VERSION ""

NS_ :

BS_:

BU_: ACS CC TCO SSC RD REX VGW TPMS TECU IC EMS EBS

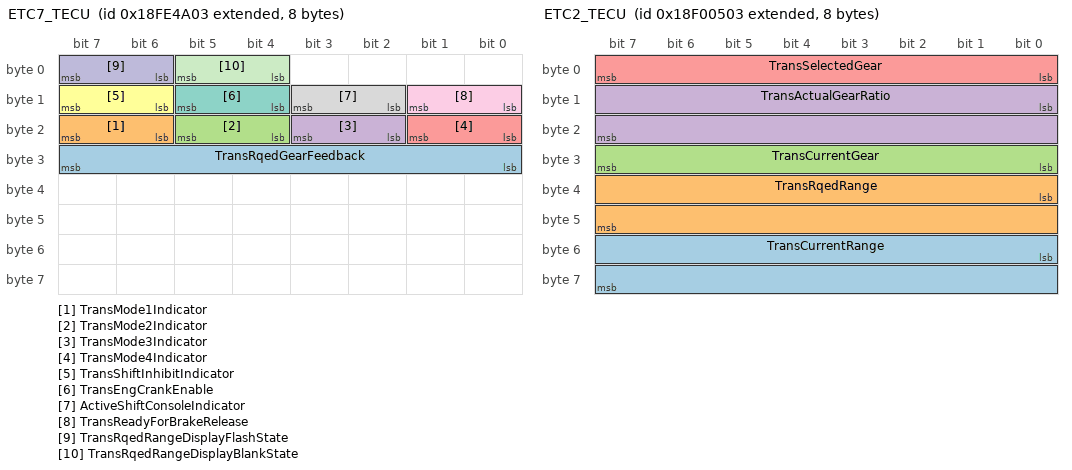
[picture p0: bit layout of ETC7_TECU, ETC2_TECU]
BO_ 2566801923 ETC7_TECU: 8 TECU
 SG_ TransRqedGearFeedback : 24|8@1+ (1,-125) [-125|125] "" Vector__XXX
 SG_ TransMode1Indicator : 22|2@1+ (1,0) [0|3] "" Vector__XXX
 SG_ TransMode2Indicator : 20|2@1+ (1,0) [0|3] "" Vector__XXX
 SG_ TransMode3Indicator : 18|2@1+ (1,0) [0|3] "" Vector__XXX
 SG_ TransMode4Indicator : 16|2@1+ (1,0) [0|3] "" Vector__XXX
 SG_ TransShiftInhibitIndicator : 14|2@1+ (1,0) [0|3] "" Vector__XXX
 SG_ TransEngCrankEnable : 12|2@1+ (1,0) [0|3] ""  EMS
 SG_ ActiveShiftConsoleIndicator : 10|2@1+ (1,0) [0|3] "" Vector__XXX
 SG_ TransReadyForBrakeRelease : 8|2@1+ (1,0) [0|3] "" Vector__XXX
 SG_ TransRqedRangeDisplayFlashState : 6|2@1+ (1,0) [0|3] "" Vector__XXX
 SG_ TransRqedRangeDisplayBlankState : 4|2@1+ (1,0) [0|3] "" Vector__XXX

BO_ 2565866755 ETC2_TECU: 8 TECU
 SG_ TransCurrentRange : 48|16@1+ (1,0) [0|255] "" Vector__XXX
 SG_ TransRqedRange : 32|16@1+ (1,0) [0|255] "" Vector__XXX
 SG_ TransCurrentGear : 24|8@1+ (1,-125) [-125|125] ""  IC,EBS
 SG_ TransActualGearRatio : 8|16@1+ (0.001,0) [0|64.255] "" Vector__XXX
 SG_ TransSelectedGear : 0|8@1+ (1,-125) [-125|125] ""  EMS,IC

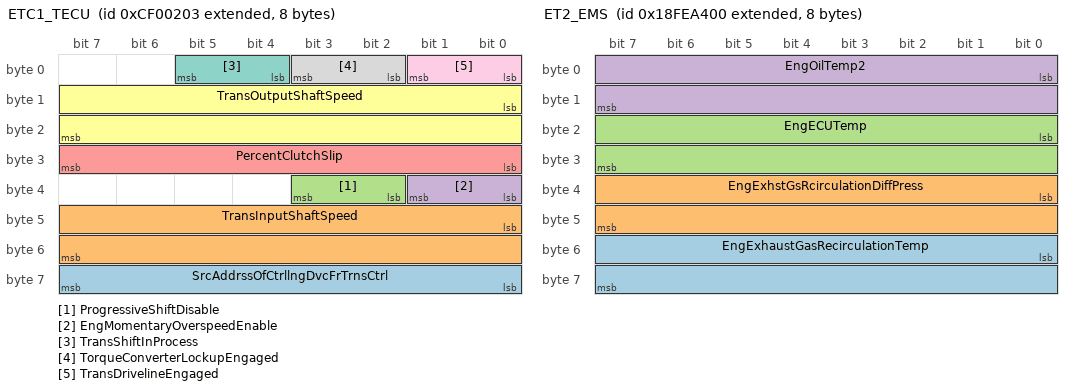
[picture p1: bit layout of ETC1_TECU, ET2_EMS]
BO_ 2364539395 ETC1_TECU: 8 TECU
 SG_ SrcAddrssOfCtrllngDvcFrTrnsCtrl : 56|8@1+ (1,0) [0|255] "" Vector__XXX
 SG_ TransInputShaftSpeed : 40|16@1+ (0.125,0) [0|8031.875] "rpm"  EMS,EBS
 SG_ ProgressiveShiftDisable : 34|2@1+ (1,0) [0|3] "" Vector__XXX
 SG_ EngMomentaryOverspeedEnable : 32|2@1+ (1,0) [0|3] "" Vector__XXX
 SG_ PercentClutchSlip : 24|8@1+ (0.4,0) [0|100] "%" Vector__XXX
 SG_ TransOutputShaftSpeed : 8|16@1+ (0.125,0) [0|8031.875] "rpm" Vector__XXX
 SG_ TransShiftInProcess : 4|2@1+ (1,0) [0|3] ""  EBS
 SG_ TorqueConverterLockupEngaged : 2|2@1+ (1,0) [0|3] ""  EBS
 SG_ TransDrivelineEngaged : 0|2@1+ (1,0) [0|3] ""  EBS

BO_ 2566824960 ET2_EMS: 8 EMS
 SG_ EngExhaustGasRecirculationTemp : 48|16@1+ (0.03125,-273) [-273|1735] "deg" Vector__XXX
 SG_ EngExhstGsRcirculationDiffPress : 32|16@1+ (0.0078125,-250) [-250|251.99] "kPa" Vector__XXX
 SG_ EngECUTemp : 16|16@1+ (0.03125,-273) [-273|1735] "deg" Vector__XXX
 SG_ EngOilTemp2 : 0|16@1+ (0.03125,-273) [-273|1735] "deg" Vector__XXX

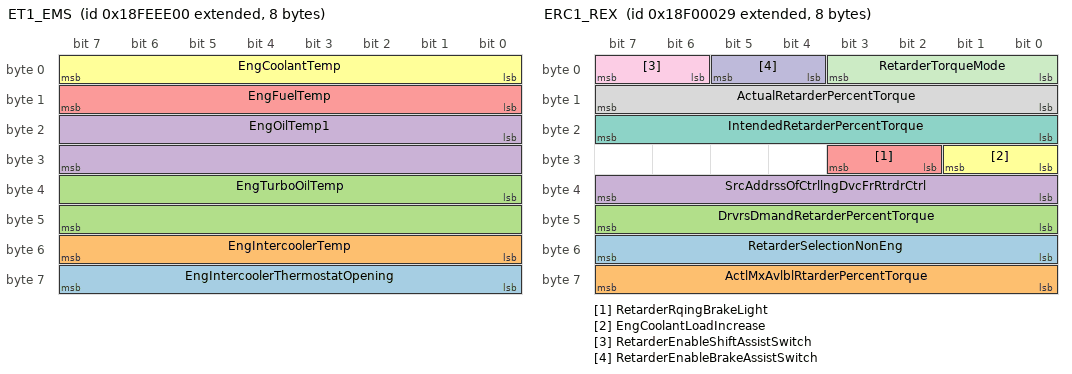
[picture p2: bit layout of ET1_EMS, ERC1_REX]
BO_ 2566843904 ET1_EMS: 8 EMS
 SG_ EngIntercoolerThermostatOpening : 56|8@1+ (0.4,0) [0|100] "%" Vector__XXX
 SG_ EngIntercoolerTemp : 48|8@1+ (1,-40) [-40|210] "deg" Vector__XXX
 SG_ EngTurboOilTemp : 32|16@1+ (0.03125,-273) [-273|1735] "deg" Vector__XXX
 SG_ EngOilTemp1 : 16|16@1+ (0.03125,-273) [-273|1735] "deg" Vector__XXX
 SG_ EngFuelTemp : 8|8@1+ (1,-40) [-40|210] "deg" Vector__XXX
 SG_ EngCoolantTemp : 0|8@1+ (1,-40) [-40|210] "deg"  CC,IC,RD,TECU,VGW

BO_ 2565865513 ERC1_REX: 8 REX
 SG_ RetarderSelectionNonEng : 48|8@1+ (0.4,0) [0|100] "%" Vector__XXX
 SG_ ActlMxAvlblRtarderPercentTorque : 56|8@1+ (1,-125) [-125|125] "%" Vector__XXX
 SG_ DrvrsDmandRetarderPercentTorque : 40|8@1+ (1,-125) [-125|125] "%" Vector__XXX
 SG_ SrcAddrssOfCtrllngDvcFrRtrdrCtrl : 32|8@1+ (1,0) [0|255] "" Vector__XXX
 SG_ RetarderRqingBrakeLight : 26|2@1+ (1,0) [0|3] "" Vector__XXX
 SG_ EngCoolantLoadIncrease : 24|2@1+ (1,0) [0|3] "" Vector__XXX
 SG_ IntendedRetarderPercentTorque : 16|8@1+ (1,-125) [-125|125] "%" Vector__XXX
 SG_ ActualRetarderPercentTorque : 8|8@1+ (1,-125) [-125|125] "%" Vector__XXX
 SG_ RetarderEnableShiftAssistSwitch : 6|2@1+ (1,0) [0|3] "" Vector__XXX
 SG_ RetarderEnableBrakeAssistSwitch : 4|2@1+ (1,0) [0|3] "" Vector__XXX
 SG_ RetarderTorqueMode : 0|4@1+ (1,0) [0|15] "" Vector__XXX

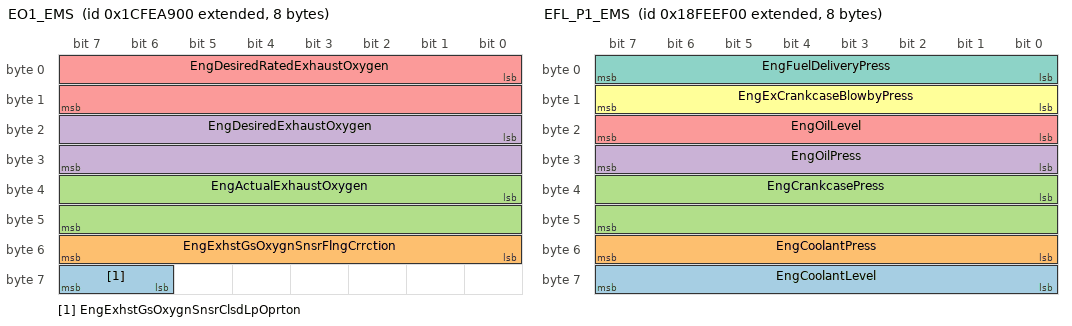
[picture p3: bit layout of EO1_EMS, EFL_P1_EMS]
BO_ 2633935104 EO1_EMS: 8 EMS
 SG_ EngExhstGsOxygnSnsrClsdLpOprton : 62|2@1+ (1,0) [0|3] "" Vector__XXX
 SG_ EngExhstGsOxygnSnsrFlngCrrction : 48|8@1+ (1,-125) [-125|125] "%" Vector__XXX
 SG_ EngActualExhaustOxygen : 32|16@1+ (0.0025,0) [0|160.6375] "%" Vector__XXX
 SG_ EngDesiredExhaustOxygen : 16|16@1+ (0.0025,0) [0|160.6375] "%" Vector__XXX
 SG_ EngDesiredRatedExhaustOxygen : 0|16@1+ (0.0025,0) [0|160.6375] "%" Vector__XXX

BO_ 2566844160 EFL_P1_EMS: 8 EMS
 SG_ EngCoolantLevel : 56|8@1+ (0.4,0) [0|100] "%" Vector__XXX
 SG_ EngCoolantPress : 48|8@1+ (2,0) [0|500] "kPa" Vector__XXX
 SG_ EngCrankcasePress : 32|16@1+ (0.0078125,-250) [-250|251.99] "kPa" Vector__XXX
 SG_ EngOilPress : 24|8@1+ (4,0) [0|1000] "kPa" Vector__XXX
 SG_ EngOilLevel : 16|8@1+ (0.4,0) [0|100] "%" Vector__XXX
 SG_ EngExCrankcaseBlowbyPress : 8|8@1+ (0.05,0) [0|12.5] "kPa" Vector__XXX
 SG_ EngFuelDeliveryPress : 0|8@1+ (4,0) [0|1000] "kPa" Vector__XXX

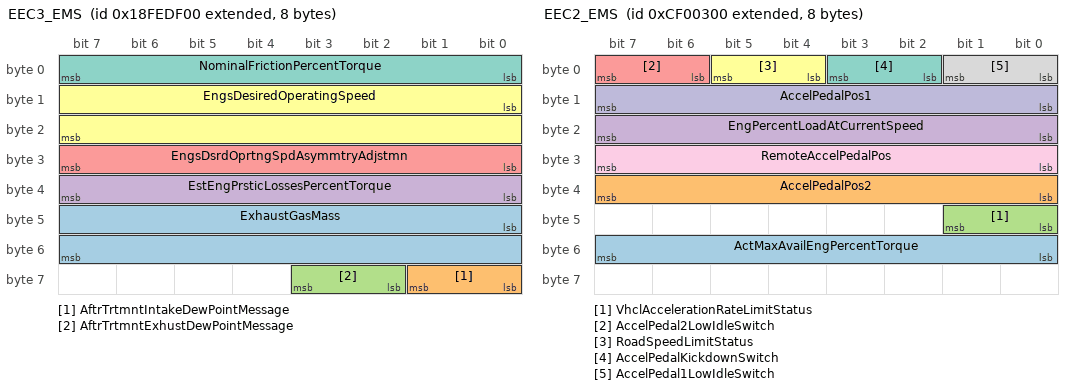
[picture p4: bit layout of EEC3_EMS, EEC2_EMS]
BO_ 2566840064 EEC3_EMS: 8 EMS
 SG_ ExhaustGasMass : 40|16@1+ (2,0) [0|128510] "kg" Vector__XXX
 SG_ AftrTrtmntIntakeDewPointMessage : 56|2@1+ (1,0) [0|3] "" Vector__XXX
 SG_ AftrTrtmntExhustDewPointMessage : 58|2@1+ (1,0) [0|3] "" Vector__XXX
 SG_ EstEngPrsticLossesPercentTorque : 32|8@1+ (1,-125) [-125|125] "%" Vector__XXX
 SG_ EngsDsrdOprtngSpdAsymmtryAdjstmn : 24|8@1+ (1,0) [0|250] "" Vector__XXX
 SG_ EngsDesiredOperatingSpeed : 8|16@1+ (0.125,0) [0|8031.875] "rpm" Vector__XXX
 SG_ NominalFrictionPercentTorque : 0|8@1+ (1,-125) [-125|125] "%"  EBS,TECU

BO_ 2364539648 EEC2_EMS: 8 EMS
 SG_ ActMaxAvailEngPercentTorque : 48|8@1+ (0.4,0) [0|100] "%" Vector__XXX
 SG_ AccelPedalPos2 : 32|8@1+ (0.4,0) [0|100] "%" Vector__XXX
 SG_ VhclAccelerationRateLimitStatus : 40|2@1+ (1,0) [0|3] "" Vector__XXX
 SG_ EngPercentLoadAtCurrentSpeed : 16|8@1+ (1,0) [0|250] "%"  TECU
 SG_ AccelPedal2LowIdleSwitch : 6|2@1+ (1,0) [0|3] "" Vector__XXX
 SG_ RoadSpeedLimitStatus : 4|2@1+ (1,0) [0|3] "" Vector__XXX
 SG_ AccelPedalKickdownSwitch : 2|2@1+ (1,0) [0|3] ""  TECU
 SG_ AccelPedal1LowIdleSwitch : 0|2@1+ (1,0) [0|3] ""  TECU
 SG_ RemoteAccelPedalPos : 24|8@1+ (0.4,0) [0|100] "%" Vector__XXX
 SG_ AccelPedalPos1 : 8|8@1+ (0.4,0) [0|100] "%"  RD,EBS,TECU,VGW

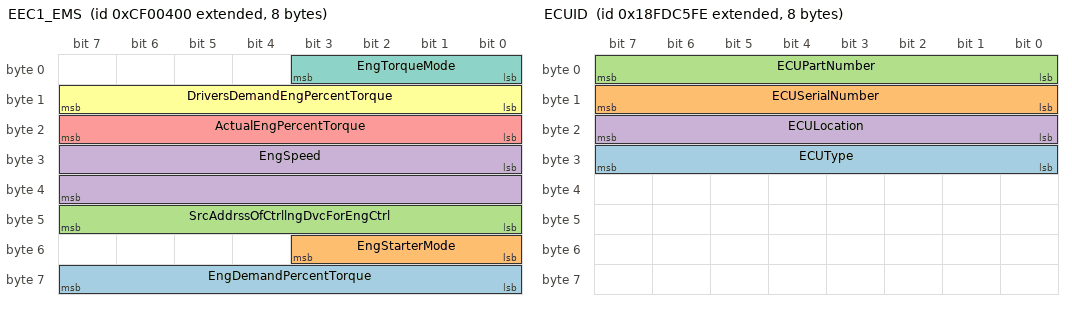
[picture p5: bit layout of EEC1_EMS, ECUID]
BO_ 2364539904 EEC1_EMS: 8 EMS
 SG_ EngDemandPercentTorque : 56|8@1+ (1,-125) [-125|125] "%"  TECU
 SG_ EngStarterMode : 48|4@1+ (1,0) [0|15] "" Vector__XXX
 SG_ SrcAddrssOfCtrllngDvcForEngCtrl : 40|8@1+ (1,0) [0|255] "" Vector__XXX
 SG_ EngSpeed : 24|16@1+ (0.125,0) [0|8031.875] "rpm"  TCO,SSC,IC,RD,EBS,VGW,TECU
 SG_ ActualEngPercentTorque : 16|8@1+ (1,-125) [-125|125] "%"  RD,EBS,TECU
 SG_ DriversDemandEngPercentTorque : 8|8@1+ (1,-125) [-125|125] "%"  SSC,EBS
 SG_ EngTorqueMode : 0|4@1+ (1,0) [0|15] ""  RD,EBS,TECU

BO_ 2566768126 ECUID: 8 EMS
 SG_ ECUType : 24|8@1+ (1,0) [0|255] "" Vector__XXX
 SG_ ECUSerialNumber : 8|8@1+ (1,0) [0|255] "" Vector__XXX
 SG_ ECUPartNumber : 0|8@1+ (1,0) [0|255] "" Vector__XXX
 SG_ ECULocation : 16|8@1+ (1,0) [0|255] "" Vector__XXX

BO_ 2566841088 EC_EMS: 39 EMS
 SG_ SupportTSC1CtrlPurposeGroup4Of4 : 304|8@1+ (1,0) [0|255] "" Vector__XXX
 SG_ SupportVariableRateTSC1Message : 272|8@1+ (1,0) [0|255] "" Vector__XXX
 SG_ SupportTSC1CtrlPurposeGroup3Of4 : 296|8@1+ (1,0) [0|255] "" Vector__XXX
 SG_ SupportTSC1CtrlPurposeGroup2Of4 : 288|8@1+ (1,0) [0|255] "" Vector__XXX
 SG_ SupportTSC1CtrlPurposeGroup1Of4 : 280|8@1+ (1,0) [0|255] "" Vector__XXX
 SG_ EngDefaultTorqueLimit : 256|16@1+ (1,0) [0|64255] "Nm" Vector__XXX
 SG_ EngMomentOfInertia : 240|16@1+ (0.004,0) [0|257.02] "kg-m²" Vector__XXX
 SG_ EngExRngRqdSpdCtrlRngUpperLimit : 224|16@1+ (0.125,0) [0|8031.875] "rpm" Vector__XXX
 SG_ EngRqdTorqueCtrlRangeUpperLimit : 216|8@1+ (1,-125) [-125|125] "%" Vector__XXX
 SG_ EngRqdTorqueCtrlRangeLowerLimit : 208|8@1+ (1,-125) [-125|125] "%" Vector__XXX
 SG_ EngRqedSpeedCtrlRangeUpperLimit : 200|8@1+ (10,0) [0|2500] "rpm" Vector__XXX
 SG_ EngRqedSpeedCtrlRangeLowerLimit : 192|8@1+ (10,0) [0|2500] "rpm" Vector__XXX
 SG_ EngMxMomentaryOverrideTimeLimit : 184|8@1+ (0.1,0) [0|25] "s" Vector__XXX
 SG_ EngMxMmntaryOverrideSpeedPoint7 : 168|16@1+ (0.125,0) [0|8031.875] "rpm" Vector__XXX
 SG_ EngReferenceTorque : 152|16@1+ (1,0) [0|64255] "Nm"  RD,EBS,TECU
 SG_ EngSpeedAtHighIdlePoint6 : 120|16@1+ (0.125,0) [0|8031.875] "rpm"  TECU
 SG_ EngGainOfEndspeedGovernor : 136|16@1+ (0.00078125,0) [0|50.2] "%/rpm" Vector__XXX
 SG_ EngPercentTorqueAtPoint5 : 112|8@1+ (1,-125) [-125|125] "%"  TECU
 SG_ EngSpeedAtPoint5 : 96|16@1+ (0.125,0) [0|8031.875] "rpm"  TECU
 SG_ EngPercentTorqueAtPoint4 : 88|8@1+ (1,-125) [-125|125] "%"  TECU
 SG_ EngSpeedAtPoint4 : 72|16@1+ (0.125,0) [0|8031.875] "rpm"  TECU
 SG_ EngPercentTorqueAtPoint3 : 64|8@1+ (1,-125) [-125|125] "%"  TECU
 SG_ EngSpeedAtPoint3 : 48|16@1+ (0.125,0) [0|8031.875] "rpm"  TECU
 SG_ EngPercentTorqueAtPoint2 : 40|8@1+ (1,-125) [-125|125] "%"  TECU
 SG_ EngSpeedAtPoint2 : 24|16@1+ (0.125,0) [0|8031.875] "rpm"  TECU
 SG_ EngPercentTorqueAtIdlePoint1 : 16|8@1+ (1,-125) [-125|125] "%"  TECU
 SG_ EngSpeedAtIdlePoint1 : 0|16@1+ (0.125,0) [0|8031.875] "rpm"  TECU

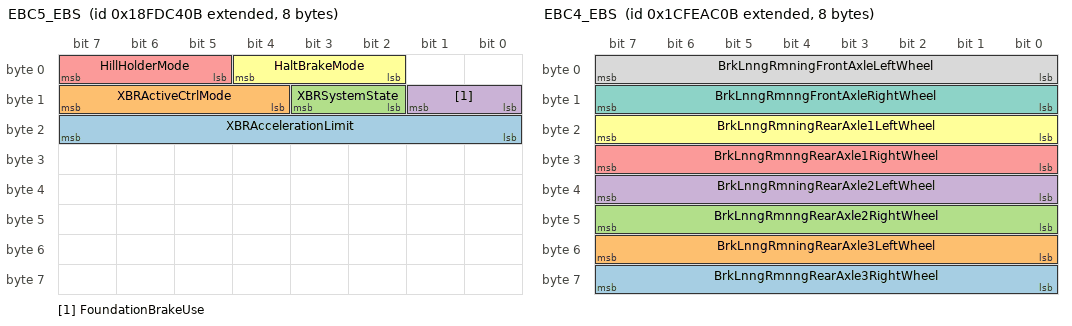
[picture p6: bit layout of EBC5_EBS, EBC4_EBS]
BO_ 2566767627 EBC5_EBS: 8 EBS
 SG_ XBRAccelerationLimit : 16|8@1+ (0.1,-12.5) [-12.5|12.5] "m/s²" Vector__XXX
 SG_ XBRActiveCtrlMode : 12|4@1+ (1,0) [0|15] "" Vector__XXX
 SG_ XBRSystemState : 10|2@1+ (1,0) [0|3] "" Vector__XXX
 SG_ FoundationBrakeUse : 8|2@1+ (1,0) [0|3] "" Vector__XXX
 SG_ HillHolderMode : 5|3@1+ (1,0) [0|7] "" Vector__XXX
 SG_ HaltBrakeMode : 2|3@1+ (1,0) [0|7] ""  IC

BO_ 2633935883 EBC4_EBS: 8 EBS
 SG_ BrkLnngRmnngRearAxle3RightWheel : 56|8@1+ (0.4,0) [0|100] "%" Vector__XXX
 SG_ BrkLnngRmningRearAxle3LeftWheel : 48|8@1+ (0.4,0) [0|100] "%" Vector__XXX
 SG_ BrkLnngRmnngRearAxle2RightWheel : 40|8@1+ (0.4,0) [0|100] "%" Vector__XXX
 SG_ BrkLnngRmningRearAxle2LeftWheel : 32|8@1+ (0.4,0) [0|100] "%" Vector__XXX
 SG_ BrkLnngRmnngRearAxle1RightWheel : 24|8@1+ (0.4,0) [0|100] "%" Vector__XXX
 SG_ BrkLnngRmningRearAxle1LeftWheel : 16|8@1+ (0.4,0) [0|100] "%" Vector__XXX
 SG_ BrkLnngRmnngFrontAxleRightWheel : 8|8@1+ (0.4,0) [0|100] "%" Vector__XXX
 SG_ BrkLnngRmningFrontAxleLeftWheel : 0|8@1+ (0.4,0) [0|100] "%" Vector__XXX

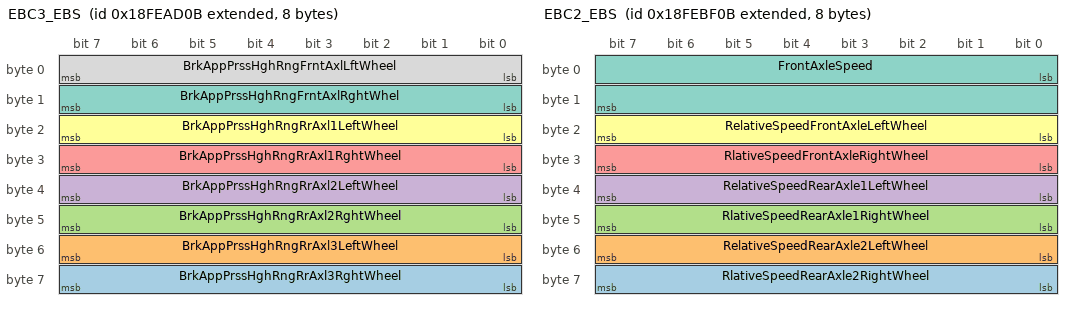
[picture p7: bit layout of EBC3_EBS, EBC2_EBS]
BO_ 2566827275 EBC3_EBS: 8 EBS
 SG_ BrkAppPrssHghRngRrAxl3RghtWheel : 56|8@1+ (5,0) [0|1250] "kPa" Vector__XXX
 SG_ BrkAppPrssHghRngRrAxl3LeftWheel : 48|8@1+ (5,0) [0|1250] "kPa" Vector__XXX
 SG_ BrkAppPrssHghRngRrAxl2RghtWheel : 40|8@1+ (5,0) [0|1250] "kPa" Vector__XXX
 SG_ BrkAppPrssHghRngRrAxl2LeftWheel : 32|8@1+ (5,0) [0|1250] "kPa" Vector__XXX
 SG_ BrkAppPrssHghRngRrAxl1RghtWheel : 24|8@1+ (5,0) [0|1250] "kPa" Vector__XXX
 SG_ BrkAppPrssHghRngRrAxl1LeftWheel : 16|8@1+ (5,0) [0|1250] "kPa" Vector__XXX
 SG_ BrkAppPrssHghRngFrntAxlRghtWhel : 8|8@1+ (5,0) [0|1250] "kPa" Vector__XXX
 SG_ BrkAppPrssHghRngFrntAxlLftWheel : 0|8@1+ (5,0) [0|1250] "kPa" Vector__XXX

BO_ 2566831883 EBC2_EBS: 8 EBS
 SG_ RlativeSpeedRearAxle2RightWheel : 56|8@1+ (0.0625,-7.8125) [-7.8125|7.8125] "km/h" Vector__XXX
 SG_ RelativeSpeedRearAxle2LeftWheel : 48|8@1+ (0.0625,-7.8125) [-7.8125|7.8125] "km/h" Vector__XXX
 SG_ RlativeSpeedRearAxle1RightWheel : 40|8@1+ (0.0625,-7.8125) [-7.8125|7.8125] "km/h" Vector__XXX
 SG_ RelativeSpeedRearAxle1LeftWheel : 32|8@1+ (0.0625,-7.8125) [-7.8125|7.8125] "km/h" Vector__XXX
 SG_ RlativeSpeedFrontAxleRightWheel : 24|8@1+ (0.0625,-7.8125) [-7.8125|7.8125] "km/h" Vector__XXX
 SG_ RelativeSpeedFrontAxleLeftWheel : 16|8@1+ (0.0625,-7.8125) [-7.8125|7.8125] "km/h" Vector__XXX
 SG_ FrontAxleSpeed : 0|16@1+ (0.00390625,0) [0|250.996] "km/h"  EMS

BO_ 2565865739 EBC1_EBS: 8 EBS
 SG_ SrcAddrssOfCtrllngDvcFrBrkCntrl : 48|8@1+ (1,0) [0|255] "" Vector__XXX
 SG_ BrakePedalPos : 8|8@1+ (0.4,0) [0|100] "%"  RD
 SG_ TrctrMntdTrilerABSWarningSignal : 62|2@1+ (1,0) [0|3] "" Vector__XXX
 SG_ TrailerABSStatus : 60|2@1+ (1,0) [0|3] "" Vector__XXX
 SG_ HaltBrakeSwitch : 58|2@1+ (1,0) [0|3] "" Vector__XXX
 SG_ ATC_ASRInformationSignal : 46|2@1+ (1,0) [0|3] "" Vector__XXX
 SG_ ABS_EBSAmberWarningSignal : 44|2@1+ (1,0) [0|3] ""  IC
 SG_ EBSRedWarningSignal : 42|2@1+ (1,0) [0|3] ""  IC
 SG_ ABSFullyOperational : 40|2@1+ (1,0) [0|3] ""  RD
 SG_ EngRetarderSelection : 32|8@1+ (0.4,0) [0|100] "%" Vector__XXX
 SG_ RemoteAccelEnableSwitch : 30|2@1+ (1,0) [0|3] "" Vector__XXX
 SG_ EngAuxEngShutdownSwitch : 28|2@1+ (1,0) [0|3] "" Vector__XXX
 SG_ EngDerateSwitch : 26|2@1+ (1,0) [0|3] "" Vector__XXX
 SG_ AccelInterlockSwitch : 24|2@1+ (1,0) [0|3] "" Vector__XXX
 SG_ TractionCtrlOverrideSwitch : 22|2@1+ (1,0) [0|3] "" Vector__XXX
 SG_ ASRHillHolderSwitch : 20|2@1+ (1,0) [0|3] "" Vector__XXX
 SG_ ASROffroadSwitch : 18|2@1+ (1,0) [0|3] ""  IC
 SG_ ABSOffroadSwitch : 16|2@1+ (1,0) [0|3] "" Vector__XXX
 SG_ EBSBrakeSwitch : 6|2@1+ (1,0) [0|3] "" Vector__XXX
 SG_ AntiLockBrakingActive : 4|2@1+ (1,0) [0|3] ""  IC,RD
 SG_ ASRBrakeCtrlActive : 2|2@1+ (1,0) [0|3] ""  IC,RD
 SG_ ASREngCtrlActive : 0|2@1+ (1,0) [0|3] ""  IC,RD

BO_ 2566810606 DI_TCO: 8 TCO
 SG_ Driver2 : 8|8@1+ (1,0) [0|255] "" Vector__XXX
 SG_ Driver1 : 0|8@1+ (1,0) [0|255] "" Vector__XXX

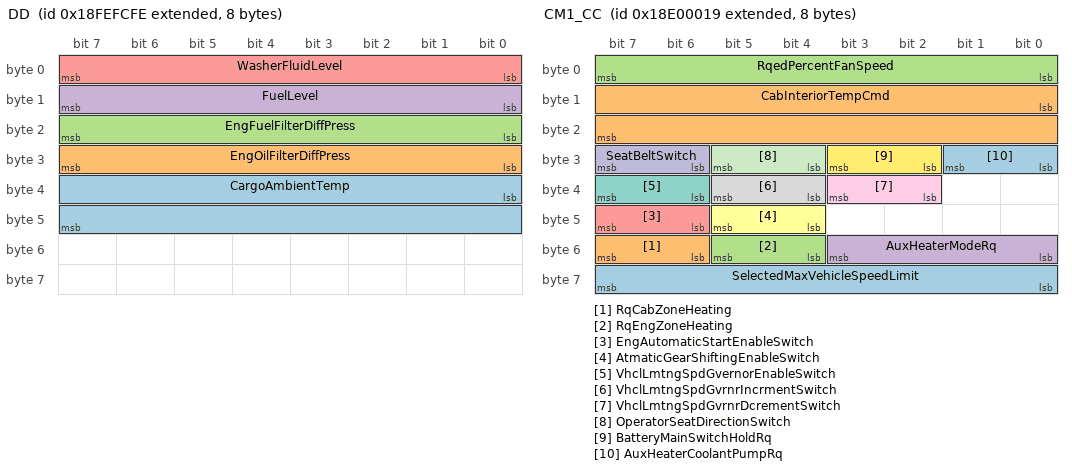
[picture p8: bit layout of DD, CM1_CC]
BO_ 2566847742 DD: 8 Vector__XXX
 SG_ CargoAmbientTemp : 32|16@1+ (0.03125,-273) [-273|1735] "deg" Vector__XXX
 SG_ EngOilFilterDiffPress : 24|8@1+ (0.5,0) [0|125] "kPa" Vector__XXX
 SG_ EngFuelFilterDiffPress : 16|8@1+ (2,0) [0|500] "kPa" Vector__XXX
 SG_ FuelLevel : 8|8@1+ (0.4,0) [0|100] "%"  VGW
 SG_ WasherFluidLevel : 0|8@1+ (0.4,0) [0|100] "%" Vector__XXX

BO_ 2564816921 CM1_CC: 8 CC
 SG_ SelectedMaxVehicleSpeedLimit : 56|8@1+ (1,0) [0|250] "" Vector__XXX
 SG_ RqCabZoneHeating : 54|2@1+ (1,0) [0|3] "" Vector__XXX
 SG_ RqEngZoneHeating : 52|2@1+ (1,0) [0|3] "" Vector__XXX
 SG_ AuxHeaterModeRq : 48|4@1+ (1,0) [0|15] "" Vector__XXX
 SG_ EngAutomaticStartEnableSwitch : 46|2@1+ (1,0) [0|3] "" Vector__XXX
 SG_ AtmaticGearShiftingEnableSwitch : 44|2@1+ (1,0) [0|3] "" Vector__XXX
 SG_ VhclLmtngSpdGvernorEnableSwitch : 38|2@1+ (1,0) [0|3] "" Vector__XXX
 SG_ VhclLmtngSpdGvrnrIncrmentSwitch : 36|2@1+ (1,0) [0|3] "" Vector__XXX
 SG_ VhclLmtngSpdGvrnrDcrementSwitch : 34|2@1+ (1,0) [0|3] "" Vector__XXX
 SG_ SeatBeltSwitch : 30|2@1+ (1,0) [0|3] "" Vector__XXX
 SG_ OperatorSeatDirectionSwitch : 28|2@1+ (1,0) [0|3] "" Vector__XXX
 SG_ BatteryMainSwitchHoldRq : 26|2@1+ (1,0) [0|3] "" Vector__XXX
 SG_ AuxHeaterCoolantPumpRq : 24|2@1+ (1,0) [0|3] "" Vector__XXX
 SG_ CabInteriorTempCmd : 8|16@1+ (0.03125,-273) [-273|1735] "deg" Vector__XXX
 SG_ RqedPercentFanSpeed : 0|8@1+ (0.4,0) [0|100] "%"  EMS

BO_ 2563833623 CL_IC: 8 IC
 SG_ IlluminationBrightnessPercent : 0|8@1+ (0.4,0) [0|100] "%"  TCO

BO_ 2566844672 CCVS_EMS: 8 EMS
 SG_ EngShutdownOverrideSwitch : 62|2@1+ (1,0) [0|3] "" Vector__XXX
 SG_ EngTestModeSwitch : 60|2@1+ (1,0) [0|3] "" Vector__XXX
 SG_ EngIdleDecrementSwitch : 58|2@1+ (1,0) [0|3] "" Vector__XXX
 SG_ EngIdleIncrementSwitch : 56|2@1+ (1,0) [0|3] "" Vector__XXX
 SG_ CruiseCtrlStates : 53|3@1+ (1,0) [0|7] ""  CC,IC
 SG_ PTOState : 48|5@1+ (1,0) [0|31] ""  VGW
 SG_ CruiseCtrlSetSpeed : 40|8@1+ (1,0) [0|250] "km/h"  IC,RD
 SG_ CruiseCtrlAccelerateSwitch : 38|2@1+ (1,0) [0|3] "" Vector__XXX
 SG_ CruiseCtrlResumeSwitch : 36|2@1+ (1,0) [0|3] "" Vector__XXX
 SG_ CruiseCtrlCoastSwitch : 34|2@1+ (1,0) [0|3] "" Vector__XXX
 SG_ CruiseCtrlSetSwitch : 32|2@1+ (1,0) [0|3] "" Vector__XXX
 SG_ ClutchSwitch : 30|2@1+ (1,0) [0|3] ""  RD,TECU,VGW
 SG_ BrakeSwitch : 28|2@1+ (1,0) [0|3] ""  SSC,IC,EBS,VGW
 SG_ CruiseCtrlEnableSwitch : 26|2@1+ (1,0) [0|3] ""  RD
 SG_ CruiseCtrlActive : 24|2@1+ (1,0) [0|3] ""  IC,RD,VGW
 SG_ WheelBasedVehicleSpeed : 8|16@1+ (0.00390625,0) [0|250.996] "km/h"  CC,SSC,RD,TECU,VGW
 SG_ CruiseCtrlPauseSwitch : 4|2@1+ (1,0) [0|3] "" Vector__XXX
 SG_ ParkingBrakeSwitch : 2|2@1+ (1,0) [0|3] ""  CC,SSC,IC,EBS
 SG_ TwoSpeedAxleSwitch : 0|2@1+ (1,0) [0|3] "" Vector__XXX

BO_ 2566775065 CACI_CC: 8 CC
 SG_ CbA_CRfrgrntCmprssorOutletPress : 0|8@1+ (16,0) [0|4000] "kPa" Vector__XXX

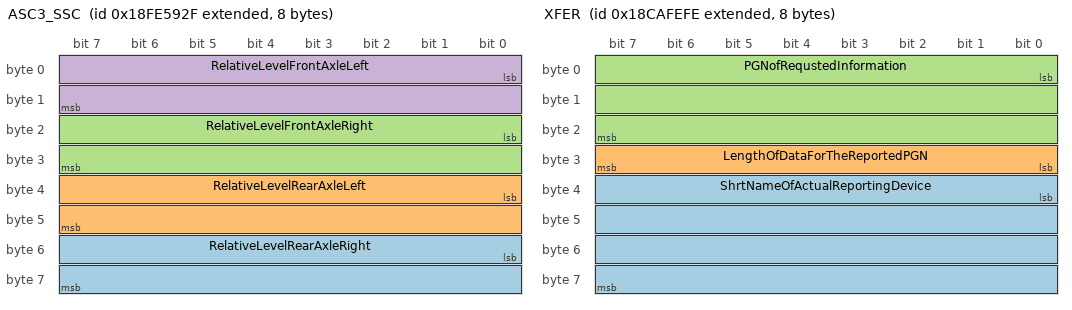
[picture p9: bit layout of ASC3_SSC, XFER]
BO_ 2566805807 ASC3_SSC: 8 SSC
 SG_ RelativeLevelRearAxleRight : 48|16@1+ (0.1,-2800) [-2800|3225.5] "mm" Vector__XXX
 SG_ RelativeLevelRearAxleLeft : 32|16@1+ (0.1,-2800) [-2800|3225.5] "mm" Vector__XXX
 SG_ RelativeLevelFrontAxleRight : 16|16@1+ (0.1,-2800) [-2800|3225.5] "mm" Vector__XXX
 SG_ RelativeLevelFrontAxleLeft : 0|16@1+ (0.1,-2800) [-2800|3225.5] "mm" Vector__XXX

BO_ 2365479471 ASC1_SSC: 8 SSC
 SG_ SspensionCtrlRefusalInformation : 56|4@1+ (1,0) [0|15] "" Vector__XXX
 SG_ SuspensionRemoteCtrl2 : 50|2@1+ (1,0) [0|3] "" Vector__XXX
 SG_ SuspensionRemoteCtrl1 : 48|2@1+ (1,0) [0|3] "" Vector__XXX
 SG_ RearAxleInBumperRange : 42|2@1+ (1,0) [0|3] "" Vector__XXX
 SG_ FrontAxleInBumperRange : 40|2@1+ (1,0) [0|3] "" Vector__XXX
 SG_ DoorRelease : 36|2@1+ (1,0) [0|3] "" Vector__XXX
 SG_ VehicleMotionInhibit : 34|2@1+ (1,0) [0|3] "" Vector__XXX
 SG_ SecurityDevice : 32|2@1+ (1,0) [0|3] "" Vector__XXX
 SG_ LevelCtrlMode : 28|4@1+ (1,0) [0|15] "" Vector__XXX
 SG_ KneelingInformation : 24|4@1+ (1,0) [0|15] "" Vector__XXX
 SG_ LiftingCtrlModeRearAxle : 22|2@1+ (1,0) [0|3] "" Vector__XXX
 SG_ LiftingCtrlModeFrontAxle : 20|2@1+ (1,0) [0|3] "" Vector__XXX
 SG_ LoweringCtrlModeRearAxle : 18|2@1+ (1,0) [0|3] "" Vector__XXX
 SG_ LoweringCtrlModeFrontAxle : 16|2@1+ (1,0) [0|3] "" Vector__XXX
 SG_ AboveNominalLevelRearAxle : 14|2@1+ (1,0) [0|3] "" Vector__XXX
 SG_ AboveNominalLevelFrontAxle : 12|2@1+ (1,0) [0|3] "" Vector__XXX
 SG_ BelowNominalLevelRearAxle : 10|2@1+ (1,0) [0|3] "" Vector__XXX
 SG_ BelowNominalLevelFrontAxle : 8|2@1+ (1,0) [0|3] "" Vector__XXX
 SG_ NominalLevelRearAxle : 4|4@1+ (1,0) [0|15] "" Vector__XXX
 SG_ NominalLevelFrontAxle : 0|4@1+ (1,0) [0|15] "" Vector__XXX
 SG_ LiftAxle2Pos : 46|2@1+ (1,0) [0|3] "" Vector__XXX
 SG_ LiftAxle1Pos : 38|2@1+ (1,0) [0|3] "" Vector__XXX

BO_ 2566836222 DM6: 22 EMS
 SG_ DTC5 : 144|32@1+ (1,0) [0|4294967295] "" Vector__XXX
 SG_ DTC4 : 112|32@1+ (1,0) [0|4294967295] "" Vector__XXX
 SG_ DTC3 : 80|32@1+ (1,0) [0|4294967295] "" Vector__XXX
 SG_ DTC2 : 48|32@1+ (1,0) [0|4294967295] "" Vector__XXX
 SG_ DTC1 : 16|32@1+ (1,0) [0|4294967295] "" Vector__XXX
 SG_ FlashRedStopLamp : 12|2@1+ (1,0) [0|3] "" Vector__XXX
 SG_ FlashProtectLamp : 8|2@1+ (1,0) [0|3] "" Vector__XXX
 SG_ FlashMalfuncIndicatorLamp : 14|2@1+ (1,0) [0|3] "" Vector__XXX
 SG_ MalfunctionIndicatorLampStatus : 6|2@1+ (1,0) [0|3] "" Vector__XXX
 SG_ RedStopLampState : 4|2@1+ (1,0) [0|3] "" Vector__XXX
 SG_ AmberWarningLampStatus : 2|2@1+ (1,0) [0|3] "" Vector__XXX
 SG_ ProtectLampStatus : 0|2@1+ (1,0) [0|3] "" Vector__XXX

BO_ 2566835966 DM5: 8 TPMS
 SG_ MisfireMonitoringSupport : 24|1@1+ (1,0) [0|0] "" Vector__XXX
 SG_ OBDCompliance : 16|8@1+ (1,0) [0|240] "" Vector__XXX
 SG_ PreviouslyActiveTroubleCodes : 8|8@1+ (1,0) [0|240] "" Vector__XXX
 SG_ ActiveTroubleCodes : 0|8@1+ (1,0) [0|240] "" Vector__XXX
 SG_ SecondAirSystemMonStatus : 51|1@1+ (1,0) [0|1] "" Vector__XXX
 SG_ EvaporativeSystemMonStatus : 50|1@1+ (1,0) [0|1] "" Vector__XXX
 SG_ ACSystemRefrigerantMonStatus : 52|1@1+ (1,0) [0|1] "" Vector__XXX
 SG_ OxygenSensorHeaterMonStatus : 54|1@1+ (1,0) [0|1] "" Vector__XXX
 SG_ OxygenSensorMonStatus : 53|1@1+ (1,0) [0|1] "" Vector__XXX
 SG_ EGRSystemMonitoringStatus : 55|1@1+ (1,0) [0|1] "" Vector__XXX
 SG_ CatalystMonStatus : 48|1@1+ (1,0) [0|1] "" Vector__XXX
 SG_ ColdStartAidSystemMonStatus : 56|1@1+ (1,0) [0|1] "" Vector__XXX
 SG_ HeatedCatalystMonStatus : 49|1@1+ (1,0) [0|0] "" Vector__XXX
 SG_ CatalystMonSupp : 32|1@1+ (1,0) [0|1] "" Vector__XXX
 SG_ ColdStartAidSystemMonSupp : 40|1@1+ (1,0) [0|1] "" Vector__XXX
 SG_ HeatedCatalystMonSupp : 33|1@1+ (1,0) [0|0] "" Vector__XXX
 SG_ EvaporativeSystemMonSupp : 34|1@1+ (1,0) [0|1] "" Vector__XXX
 SG_ SecondAirSystemMonSupp : 35|1@1+ (1,0) [0|1] "" Vector__XXX
 SG_ ACSystemRefrigerantMonSupp : 36|1@1+ (1,0) [0|1] "" Vector__XXX
 SG_ OxygenSensorMonSupp : 37|1@1+ (1,0) [0|1] "" Vector__XXX
 SG_ OxygenSensorHeaterMonSupp : 38|1@1+ (1,0) [0|1] "" Vector__XXX
 SG_ EGRSystemMonitoringSupp : 39|1@1+ (1,0) [0|1] "" Vector__XXX
 SG_ MisfireMonitoringStatus : 28|1@1+ (1,0) [0|0] "" Vector__XXX
 SG_ ComprehensiveCompMonStatus : 30|1@1+ (1,0) [0|1] "" Vector__XXX
 SG_ FuelSystemMonitoringStatus : 29|1@1+ (1,0) [0|1] "" Vector__XXX
 SG_ ComprehensiveComponentMonSupp : 26|1@1+ (1,0) [0|0] "" Vector__XXX
 SG_ FuelSystemMonitoringSupport : 25|1@1+ (1,0) [0|1] "" Vector__XXX

BO_ 2566835710 DM4: 13 EMS
 SG_ DTC1 : 8|32@1+ (1,0) [0|4294967295] "" Vector__XXX
 SG_ FreezeFrameLength : 0|8@1+ (1,0) [0|255] "Byte" Vector__XXX
 SG_ EngSpeed : 56|16@1+ (0.125,0) [0|8031.875] "RPM" Vector__XXX
 SG_ EngTorqueMode : 40|4@1+ (1,0) [0|15] "" Vector__XXX
 SG_ EngTurboBoostPress : 48|8@1+ (2,0) [0|500] "kPa" Vector__XXX
 SG_ WheelBasedVehicleSpeed : 88|16@1+ (0.00390625,0) [0|250.996] "km/h" Vector__XXX
 SG_ EngPercentLoadAtCurrentSpeed : 72|8@1+ (1,0) [0|250] "%" Vector__XXX
 SG_ EngineCoolantTemperature : 80|8@1+ (1,-40) [-40|210] "°C" Vector__XXX

BO_ 2566835454 DM3: 0 Vector__XXX

BO_ 2566764542 DM25: 13 TPMS
 SG_ DTC1 : 8|32@1+ (1,0) [0|4294967295] "" Vector__XXX
 SG_ ExpandedFreezeFrameLength : 0|8@1+ (1,0) [0|255] "Byte" Vector__XXX

BO_ 2566764286 DM24: 12 TPMS
 SG_ SPNSupported1High : 21|3@1+ (1,0) [0|7] "" Vector__XXX
 SG_ SPNSupportTypeSTR3 : 82|1@1+ (1,0) [0|1] "" Vector__XXX
 SG_ SPNSupportTypeSTR2 : 50|1@1+ (1,0) [0|1] "" Vector__XXX
 SG_ SPNSupportTypeEFF3 : 80|1@1+ (1,0) [0|1] "" Vector__XXX
 SG_ SPNSupportTypeEFF2 : 48|1@1+ (1,0) [0|1] "" Vector__XXX
 SG_ SPNSupportTypeDS3 : 81|1@1+ (1,0) [0|1] "" Vector__XXX
 SG_ SPNSupportTypeDS2 : 49|1@1+ (1,0) [0|1] "" Vector__XXX
 SG_ SPNSupported3High : 85|3@1+ (1,0) [0|7] "" Vector__XXX
 SG_ SPNSupported2High : 53|3@1+ (1,0) [0|7] "" Vector__XXX
 SG_ SPNSupported3 : 64|16@1+ (1,0) [0|65535] "" Vector__XXX
 SG_ SPNSupported2 : 32|16@1+ (1,0) [0|65535] "" Vector__XXX
 SG_ SPNDataLength3 : 88|8@1+ (1,0) [0|240] "" Vector__XXX
 SG_ SPNSupportTypeSTR1 : 18|1@1+ (1,0) [0|1] "" Vector__XXX
 SG_ SPNSupportTypeDS1 : 17|1@1+ (1,0) [0|1] "" Vector__XXX
 SG_ SPNSupportTypeEFF1 : 16|1@1+ (1,0) [0|1] "" Vector__XXX
 SG_ SPNDataLength2 : 56|8@1+ (1,0) [0|240] "" Vector__XXX
 SG_ SPNDataLength1 : 24|8@1+ (1,0) [0|240] "" Vector__XXX
 SG_ SPNSupported1 : 0|16@1+ (1,0) [0|65535] "" Vector__XXX

BO_ 2566835198 DM2: 22 EMS
 SG_ DTC5 : 144|32@1+ (1,0) [0|4294967295] "" Vector__XXX
 SG_ DTC4 : 112|32@1+ (1,0) [0|4294967295] "" Vector__XXX
 SG_ DTC3 : 80|32@1+ (1,0) [0|4294967295] "" Vector__XXX
 SG_ DTC2 : 48|32@1+ (1,0) [0|4294967295] "" Vector__XXX
 SG_ DTC1 : 16|32@1+ (1,0) [0|4294967295] "" Vector__XXX
 SG_ MalfunctionIndicatorLampStatus : 6|2@1+ (1,0) [0|3] "" Vector__XXX
 SG_ RedStopLampState : 4|2@1+ (1,0) [0|3] "" Vector__XXX
 SG_ AmberWarningLampStatus : 2|2@1+ (1,0) [0|3] "" Vector__XXX
 SG_ ProtectLampStatus : 0|2@1+ (1,0) [0|3] "" Vector__XXX
 SG_ FlashRedStopLamp : 12|2@1+ (1,0) [0|3] "" Vector__XXX
 SG_ FlashProtectLamp : 8|2@1+ (1,0) [0|3] "" Vector__XXX
 SG_ FlashMalfuncIndicatorLamp : 14|2@1+ (1,0) [0|3] "" Vector__XXX
 SG_ FlashAmberWarningLamp : 10|2@1+ (1,0) [0|3] "" Vector__XXX

BO_ 2564030206 DM19: 20 EMS
 SG_ CalibrationID4 : 128|32@1+ (1,0) [0|4294967295] "" Vector__XXX
 SG_ CalibrationID3 : 96|32@1+ (1,0) [0|4294967295] "" Vector__XXX
 SG_ CalibrationID2 : 64|32@1+ (1,0) [0|4294967295] "" Vector__XXX
 SG_ CalibrationID1 : 32|32@1+ (1,0) [0|4294967295] "" Vector__XXX
 SG_ CalibrationVerificationNumber : 0|32@1+ (1,0) [0|4294967295] "" Vector__XXX

BO_ 2566837502 DM12: 22 EMS
 SG_ DTC5 : 144|32@1+ (1,0) [0|4294967295] "" Vector__XXX
 SG_ DTC4 : 112|32@1+ (1,0) [0|4294967295] "" Vector__XXX
 SG_ DTC3 : 80|32@1+ (1,0) [0|4294967295] "" Vector__XXX
 SG_ DTC2 : 48|32@1+ (1,0) [0|4294967295] "" Vector__XXX
 SG_ FlashRedStopLamp : 12|2@1+ (1,0) [0|3] "" Vector__XXX
 SG_ FlashProtectLamp : 8|2@1+ (1,0) [0|3] "" Vector__XXX
 SG_ MalfunctionIndicatorLampStatus : 6|2@1+ (1,0) [0|3] "" Vector__XXX
 SG_ RedStopLampState : 4|2@1+ (1,0) [0|3] "" Vector__XXX
 SG_ AmberWarningLampStatus : 2|2@1+ (1,0) [0|3] "" Vector__XXX
 SG_ ProtectLampStatus : 0|2@1+ (1,0) [0|3] "" Vector__XXX
 SG_ FlashMalfuncIndicatorLamp : 14|2@1+ (1,0) [0|3] "" Vector__XXX
 SG_ FlashAmberWarningLamp : 10|2@1+ (1,0) [0|3] "" Vector__XXX
 SG_ SPN1 : 16|16@1+ (1,0) [0|65536] "" Vector__XXX

BO_ 2566834942 DM1: 22 EMS
 SG_ DTC5 : 144|32@1+ (1,0) [0|4294967295] "" Vector__XXX
 SG_ DTC4 : 112|32@1+ (1,0) [0|4294967295] "" Vector__XXX
 SG_ DTC3 : 80|32@1+ (1,0) [0|4294967295] "" Vector__XXX
 SG_ DTC2 : 48|32@1+ (1,0) [0|4294967295] "" Vector__XXX
 SG_ DTC1 : 16|32@1+ (1,0) [0|4294967295] "" Vector__XXX
 SG_ FlashRedStopLamp : 12|2@1+ (1,0) [0|3] ""  IC
 SG_ FlashProtectLamp : 8|2@1+ (1,0) [0|3] ""  IC
 SG_ FlashMalfuncIndicatorLamp : 14|2@1+ (1,0) [0|3] ""  IC
 SG_ FlashAmberWarningLamp : 10|2@1+ (1,0) [0|3] ""  IC
 SG_ MalfunctionIndicatorLampStatus : 6|2@1+ (1,0) [0|3] ""  IC
 SG_ AmberWarningLampStatus : 2|2@1+ (1,0) [0|3] ""  IC
 SG_ RedStopLampState : 4|2@1+ (1,0) [0|3] ""  IC
 SG_ ProtectLampStatus : 0|2@1+ (1,0) [0|3] ""  IC

BO_ 2565799678 ACL: 8 EBS
 SG_ VehicleSystem5 m5 : 49|7@1+ (1,0) [0|127] "" Vector__XXX
 SG_ VehicleSystem4 m4 : 49|7@1+ (1,0) [0|127] "" Vector__XXX
 SG_ VehicleSystem3 m3 : 49|7@1+ (1,0) [0|127] "" Vector__XXX
 SG_ VehicleSystem2 m2 : 49|7@1+ (1,0) [0|127] "" Vector__XXX
 SG_ VehicleSystem1 m1 : 49|7@1+ (1,0) [0|127] "" Vector__XXX
 SG_ ArbitraryAddressCapable : 63|1@1+ (1,0) [0|1] "" Vector__XXX
 SG_ IndustryGroup M : 60|3@1+ (1,0) [0|7] "" Vector__XXX
 SG_ VehicleSystemInstance : 56|4@1+ (1,0) [0|15] "" Vector__XXX
 SG_ VehicleSystem m0 : 49|7@1+ (1,0) [0|127] "" Vector__XXX
 SG_ Function : 40|8@1+ (1,0) [0|255] "" Vector__XXX
 SG_ FunctionInstance : 35|5@1+ (1,0) [0|31] "" Vector__XXX
 SG_ ECUInstance : 32|3@1+ (1,0) [0|7] "" Vector__XXX
 SG_ ManufacturerCode : 21|11@1+ (1,0) [0|2047] "" Vector__XXX
 SG_ IdentityNumber : 0|21@1+ (1,0) [0|2097152] "" Vector__XXX

BO_ 2563440382 XFER: 8 EMS
 SG_ ShrtNameOfActualReportingDevice : 32|32@1+ (1,0) [0|0] "(2^32 - 1)" Vector__XXX
 SG_ LengthOfDataForTheReportedPGN : 24|8@1+ (1,0) [0|255] "" Vector__XXX
 SG_ PGNofRequstedInformation : 0|24@1+ (1,0) [0|16777215] "" Vector__XXX

BO_ 2565603070 TPDT: 8 Vector__XXX
 SG_ SequenceNumber : 0|8@1+ (1,0) [0|252] "" Vector__XXX

BO_ 2565668606 TPCM: 8 Vector__XXX
 SG_ TotalNumberOfPacketsEoMA m19 : 24|8@1+ (1,0) [0|255] "" Vector__XXX
 SG_ TotalMessageSizeEoMA m19 : 8|16@1+ (1,0) [0|64255] "counts" Vector__XXX
 SG_ TotalMessageSizeBAM m32 : 8|16@1+ (1,0) [0|64255] "counts" Vector__XXX
 SG_ TotalNumberOfPacketsBAM m32 : 24|8@1+ (1,0) [0|255] "" Vector__XXX
 SG_ ConnectionAbortReason m255 : 8|8@1+ (1,0) [0|255] "" Vector__XXX
 SG_ NextPacketNumberToBeSent m17 : 16|8@1+ (1,0) [0|255] "" Vector__XXX
 SG_ NumberOfPacketsThatCanBeSent m17 : 8|8@1+ (1,0) [0|255] "" Vector__XXX
 SG_ PGNumber : 40|24@1+ (1,0) [0|16777200] "" Vector__XXX
 SG_ MaximumNumberOfPackets m16 : 32|8@1+ (1,0) [0|255] "" Vector__XXX
 SG_ TotalNumberOfPackets m16 : 24|8@1+ (1,0) [0|255] "" Vector__XXX
 SG_ TotalMessageSize m16 : 8|16@1+ (1,0) [0|64255] "counts" Vector__XXX
 SG_ ControlByte M : 0|8@1+ (1,0) [0|255] "" Vector__XXX

BO_ 2563374846 RQST2: 8 Vector__XXX
 SG_ UseTransferMode : 24|2@1+ (1,0) [0|3] "" Vector__XXX
 SG_ ParameterGroupNumber : 0|24@1+ (1,0) [0|16777215] "" Vector__XXX

BO_ 2565537534 RQST: 3 Vector__XXX
 SG_ ParameterGroupNumber : 0|24@1+ (1,0) [0|16777215] ""  ACS,CC,TCO,SSC,EBS,TECU,EMS

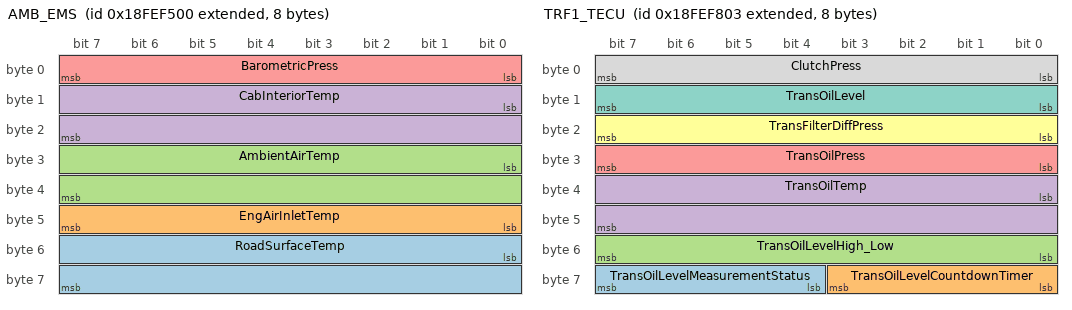
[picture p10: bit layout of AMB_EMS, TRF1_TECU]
BO_ 2566845696 AMB_EMS: 8 EMS
 SG_ RoadSurfaceTemp : 48|16@1+ (0.03125,-273) [-273|1735] "deg" Vector__XXX
 SG_ EngAirInletTemp : 40|8@1+ (1,-40) [-40|210] "deg" Vector__XXX
 SG_ AmbientAirTemp : 24|16@1+ (0.03125,-273) [-273|1735] "deg" Vector__XXX
 SG_ CabInteriorTemp : 8|16@1+ (0.03125,-273) [-273|1735] "deg" Vector__XXX
 SG_ BarometricPress : 0|8@1+ (0.5,0) [0|125] "kPa" Vector__XXX

BO_ 2565406462 ACKM: 8 EBS
 SG_ AddressBusy m3 : 32|8@1+ (1,0) [0|255] "" Vector__XXX
 SG_ ParameterGroupNumber : 40|24@1+ (1,0) [0|16777215] "" Vector__XXX
 SG_ GroupFunctionValue : 8|8@1+ (1,0) [0|255] "" Vector__XXX
 SG_ ControlByte M : 0|8@1+ (1,0) [0|255] "" Vector__XXX
 SG_ AddressAccessDenied m2 : 32|8@1+ (1,0) [0|255] "" Vector__XXX
 SG_ AddressNegativeAcknowledgement m1 : 32|8@1+ (1,0) [0|255] "" Vector__XXX
 SG_ AddressAcknowledged m0 : 32|8@1+ (1,0) [0|255] "" Vector__XXX

BO_ 2566846467 TRF1_TECU: 8 TECU
 SG_ TransOilLevelMeasurementStatus : 60|4@1+ (1,0) [0|15] "" Vector__XXX
 SG_ TransOilLevelCountdownTimer : 56|4@1+ (1,0) [0|15] "" Vector__XXX
 SG_ TransOilLevelHigh_Low : 48|8@1+ (0.5,-62.5) [-62.5|62.5] "L" Vector__XXX
 SG_ TransOilTemp : 32|16@1+ (0.03125,-273) [-273|1735] "deg"  IC
 SG_ TransOilPress : 24|8@1+ (16,0) [0|4000] "kPa" Vector__XXX
 SG_ TransFilterDiffPress : 16|8@1+ (2,0) [0|500] "kPa" Vector__XXX
 SG_ TransOilLevel : 8|8@1+ (0.4,0) [0|100] "%" Vector__XXX
 SG_ ClutchPress : 0|8@1+ (16,0) [0|4000] "kPa" Vector__XXX

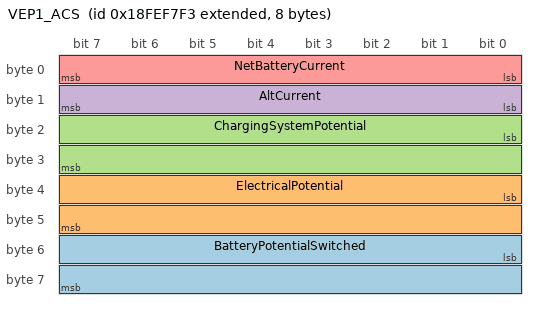
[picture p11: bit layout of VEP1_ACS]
BO_ 2566846451 VEP1_ACS: 8 ACS
 SG_ BatteryPotentialSwitched : 48|16@1+ (0.05,0) [0|3212.75] "V"  CC
 SG_ ElectricalPotential : 32|16@1+ (0.05,0) [0|3212.75] "V"  CC
 SG_ ChargingSystemPotential : 16|16@1+ (0.05,0) [0|3212.75] "V" Vector__XXX
 SG_ AltCurrent : 8|8@1+ (1,0) [0|250] "A"  CC
 SG_ NetBatteryCurrent : 0|8@1+ (1,-125) [-125|125] "A" Vector__XXX

BO_TX_BU_ 2566768126 : TCO,SSC,VGW,TPMS,EBS,TECU,EMS;
BO_TX_BU_ 2566835966 : TECU,EMS,TPMS;
BO_TX_BU_ 2566835710 : EBS,TECU,EMS;
BO_TX_BU_ 2566764542 : EBS,TECU,EMS,TPMS;
BO_TX_BU_ 2566764286 : EBS,TECU,EMS,TPMS;
BO_TX_BU_ 2566835198 : TPMS,CC,ACS,SSC,RD,EBS,TECU,EMS;
BO_TX_BU_ 2566834942 : TPMS,ACS,CC,SSC,RD,EBS,TECU,EMS;
BO_TX_BU_ 2565799678 : ACS,CC,TCO,SSC,REX,RD,VGW,TPMS,TECU,IC,EMS,EBS;
BO_TX_BU_ 2565406462 : ACS,CC,TCO,SSC,REX,RD,VGW,TPMS,TECU,IC,EMS,EBS;

EV_ EnvEMS_TorqueTakeoff: 1 [-100000|100000] "" 0 1 DUMMY_NODE_VECTOR2  EMS;

EV_ EnvTECU_InputShaftSpeed: 1 [0|10000] "rpm" 0 2 DUMMY_NODE_VECTOR3  TECU;

EV_ EnvIC_VehicleSpeed: 1 [0|200] "km/h" 0 3 DUMMY_NODE_VECTOR2  IC;

EV_ EnvIC_EngineSpeed: 1 [0|10000] "" 0 4 DUMMY_NODE_VECTOR2  IC;

EV_ EnvIC_RedStopLamp: 0 [0|1] "" 0 5 DUMMY_NODE_VECTOR2  IC;

EV_ EnvIC_AmberWarningLamp: 0 [0|1] "" 0 6 DUMMY_NODE_VECTOR2  IC;

EV_ EnvIC_ProtectLamp: 0 [0|1] "" 0 7 DUMMY_NODE_VECTOR2  IC;

EV_ EnvVehicleSpeed: 1 [0|0] "km/h" 0 8 DUMMY_NODE_VECTOR0 Vector__XXX;

EV_ EnvEBS_FaultBrakePedalPos: 0 [0|1] "" 0 9 DUMMY_NODE_VECTOR1  EBS;

EV_ EnvEBS_FaultAppPressureError: 0 [0|1] "" 0 10 DUMMY_NODE_VECTOR1  EBS;

EV_ EnvEBS_BrakePedalPos: 0 [0|10] "" 0 11 DUMMY_NODE_VECTOR3  EBS;

EV_ EnvTECU_OutputShaftSpeed: 1 [0|10000] "rpm" 0 12 DUMMY_NODE_VECTOR3  TECU;

EV_ EnvTECU_FaultOilTemp: 0 [0|2] "" 0 13 DUMMY_NODE_VECTOR1  TECU;

EV_ EnvTECU_FaultInputShaftSpeed: 0 [0|2] "" 0 14 DUMMY_NODE_VECTOR1  TECU;

EV_ EnvTECU_GearRatio: 1 [0|100] "" 0 15 DUMMY_NODE_VECTOR0 Vector__XXX;

EV_ EnvTECU_Gear: 0 [0|8] "" 0 16 DUMMY_NODE_VECTOR0 Vector__XXX;

EV_ EnvEMS_FaultOxygen: 0 [0|2] "" 0 17 DUMMY_NODE_VECTOR0 Vector__XXX;

EV_ EnvEMS_FaultTemperature: 0 [0|1] "" 0 18 DUMMY_NODE_VECTOR0  EMS;

EV_ EnvIgnitionSwitch: 0 [0|2] "" 2 19 DUMMY_NODE_VECTOR0  EMS;

EV_ EnvTECU_ShiftDown: 0 [0|1] "" 0 20 DUMMY_NODE_VECTOR0 Vector__XXX;

EV_ EnvTECU_ShiftUp: 0 [0|1] "" 0 21 DUMMY_NODE_VECTOR0 Vector__XXX;

EV_ EnvTECU_GearBitmap: 0 [0|7] "" 0 22 DUMMY_NODE_VECTOR0 Vector__XXX;

EV_ EnvEBS_SimulationMode: 0 [0|1] "" 1 23 DUMMY_NODE_VECTOR3  EMS;

EV_ EnvTECU_SimulationMode: 0 [0|1] "" 1 24 DUMMY_NODE_VECTOR3  EMS;

EV_ EnvEMS_EngineCoolantTemp: 1 [-273|1000] "°C" 0 25 DUMMY_NODE_VECTOR2  EMS;

EV_ EnvEMS_Torque: 1 [-3000|3000] "" 0 26 DUMMY_NODE_VECTOR2  EMS;

EV_ EnvEMS_EngineSpeed: 1 [0|3000] "" 0 27 DUMMY_NODE_VECTOR3  EMS;

EV_ EnvEMS_SimulationMode: 0 [0|1] "" 1 28 DUMMY_NODE_VECTOR3  EMS;

EV_ EnvEMS_Accelerator: 0 [0|10] "" 0 29 DUMMY_NODE_VECTOR1  EMS;

EV_ EnvTPMS_Recalibrate: 0 [0|1] "" 0 30 DUMMY_NODE_VECTOR0 Vector__XXX;

EV_ EnvTPMS_Rear2RightWheelBitmap: 0 [0|3] "" 0 31 DUMMY_NODE_VECTOR0 Vector__XXX;

EV_ EnvTPMS_Rear2RightState: 0 [0|5] "" 0 32 DUMMY_NODE_VECTOR0 Vector__XXX;

EV_ EnvTPMS_Rear2RightPressure: 1 [0|1000] "kPa" 800 33 DUMMY_NODE_VECTOR0 Vector__XXX;

EV_ EnvTPMS_Rear2LeftWheelBitmap: 0 [0|3] "" 0 34 DUMMY_NODE_VECTOR0 Vector__XXX;

EV_ EnvTPMS_Rear2LeftState: 0 [0|5] "" 0 35 DUMMY_NODE_VECTOR0 Vector__XXX;

EV_ EnvTPMS_Rear2LeftPressure: 1 [0|1000] "kPa" 800 36 DUMMY_NODE_VECTOR0 Vector__XXX;

EV_ EnvTPMS_Rear1RightWheelBitmap: 0 [0|3] "" 0 37 DUMMY_NODE_VECTOR0 Vector__XXX;

EV_ EnvTPMS_Rear1RightState: 0 [0|5] "" 0 38 DUMMY_NODE_VECTOR0 Vector__XXX;

EV_ EnvTPMS_Rear1RightPressure: 1 [0|1000] "kPa" 800 39 DUMMY_NODE_VECTOR0 Vector__XXX;

EV_ EnvTPMS_Rear1LeftWheelBitmap: 0 [0|3] "" 0 40 DUMMY_NODE_VECTOR0 Vector__XXX;

EV_ EnvTPMS_Rear1LeftState: 0 [0|5] "" 0 41 DUMMY_NODE_VECTOR0 Vector__XXX;

EV_ EnvTPMS_Rear1LeftPressure: 1 [0|1000] "kPa" 800 42 DUMMY_NODE_VECTOR0 Vector__XXX;

EV_ EnvTPMS_FrontRightWheelBitmap: 0 [0|3] "" 0 43 DUMMY_NODE_VECTOR0 Vector__XXX;

EV_ EnvTPMS_FrontRightState: 0 [0|5] "" 0 44 DUMMY_NODE_VECTOR0 Vector__XXX;

EV_ EnvTPMS_FrontRightPressure: 1 [0|1000] "kPa" 728 45 DUMMY_NODE_VECTOR0 Vector__XXX;

EV_ EnvTPMS_FrontLeftWheelBitmap: 0 [0|3] "" 0 46 DUMMY_NODE_VECTOR0 Vector__XXX;

EV_ EnvTPMS_FrontLeftState: 0 [0|5] "" 0 47 DUMMY_NODE_VECTOR0 Vector__XXX;

EV_ EnvTPMS_FrontLeftPressure: 1 [0|1000] "kPa" 728 48 DUMMY_NODE_VECTOR0 Vector__XXX;
CM_ BO_ 2566801923 "Electronic Transmission Controller 7";
CM_ SG_ 2566801923 TransShiftInhibitIndicator "State signal indicating a transmission request for the Shift Inhibit Indicator to be active or inactive.";
CM_ SG_ 2566801923 TransEngCrankEnable "State signal from the transmission indicating if the transmission’s status is such that engine cranking is allowed (i.";
CM_ BO_ 2565866755 "Electronic Transmission Controller 2";
CM_ SG_ 2565866755 TransCurrentRange "Range currently being commanded by the transmission control system.";
CM_ SG_ 2565866755 TransRqedRange "Range selected by the operator.";
CM_ SG_ 2565866755 TransActualGearRatio "Actual ratio of input shaft speed to output shaft speed.";
CM_ BO_ 2364539395 "Electronic Transmission Controller 1";
CM_ SG_ 2364539395 SrcAddrssOfCtrllngDvcFrTrnsCtrl "The source address of the SAE J1939 device currently controlling the transmission.";
CM_ SG_ 2364539395 TransInputShaftSpeed "Rotational velocity of the primary shaft transferring power into the transmission.";
CM_ SG_ 2364539395 ProgressiveShiftDisable "Command signal used to indicate that progressive shifting by the engine should be disallowed.";
CM_ SG_ 2364539395 PercentClutchSlip "Parameter which represents the ratio of input shaft speed to current engine speed (in percent).";
CM_ SG_ 2364539395 TransOutputShaftSpeed "Calculated speed of the transmission output shaft.";
CM_ SG_ 2364539395 TransShiftInProcess "Indicates that the transmission is in process of shifting from the current gear to the selected gear.";
CM_ SG_ 2364539395 TorqueConverterLockupEngaged "State signal which indicates whether the torque converter lockup is engaged.";
CM_ BO_ 2566824960 "Engine Temperature 2";
CM_ SG_ 2566824960 EngECUTemp "Temperature of the engine electronic control unit.";
CM_ SG_ 2566824960 EngOilTemp2 "Temperature of the engine lubricant.";
CM_ BO_ 2566843904 "Engine Temperature 1";
CM_ SG_ 2566843904 EngIntercoolerThermostatOpening "The current position of the thermostat used to regulate the temperature of the engine intercooler.";
CM_ SG_ 2566843904 EngIntercoolerTemp "Temperature of liquid found in the intercooler located after the turbocharger.";
CM_ SG_ 2566843904 EngTurboOilTemp "Temperature of the turbocharger lubricant.";
CM_ SG_ 2566843904 EngOilTemp1 "Temperature of the engine lubricant.";
CM_ SG_ 2566843904 EngFuelTemp "Temperature of fuel entering injectors.";
CM_ SG_ 2566843904 EngCoolantTemp "Temperature of liquid found in engine cooling system.";
CM_ BO_ 2565865513 "Electronic Retarder Controller 1";
CM_ SG_ 2565865513 ActlMxAvlblRtarderPercentTorque "This is the maximum amount of torque that the retarder can immediately deliver.";
CM_ SG_ 2565865513 SrcAddrssOfCtrllngDvcFrRtrdrCtrl "The source address of the SAE J1939 device currently controlling the retarder.";
CM_ SG_ 2565865513 EngCoolantLoadIncrease "Status of an event, external to the engine, that may increase the nominal temperature of the engine coolant liquid.";
CM_ SG_ 2565865513 IntendedRetarderPercentTorque "Braking torque of retarder that the retarder is currently trying to achieve.";
CM_ SG_ 2565865513 ActualRetarderPercentTorque "Actual braking torque of the retarder as a percent of retarder configuration reference torque SPN 556.";
CM_ SG_ 2565865513 RetarderEnableShiftAssistSwitch "Switch signal which indicates whether the operator wishes the retarder to be enabled for transmission shift assist.";
CM_ SG_ 2565865513 RetarderEnableBrakeAssistSwitch "Switch signal which indicates whether the operator wishes the retarder to be enabled for vehicle braking assist.";
CM_ SG_ 2565865513 RetarderTorqueMode "State signal which indicates which retarder torque mode is currently generating, limiting, or controlling the torque.";
CM_ BO_ 2633935104 "Exhaust Oxygen 1";
CM_ SG_ 2633935104 EngExhstGsOxygnSnsrClsdLpOprton "Indicates whether the engine is using the Exhaust Gas Oxygen sensor to control the air/fuel ratio.";
CM_ BO_ 2566844160 "Engine Fluid Level/Pressure 1";
CM_ SG_ 2566844160 EngCoolantLevel "Ratio of volume of liquid found in engine cooling system to total cooling system volume.";
CM_ SG_ 2566844160 EngCoolantPress "Gage pressure of liquid found in engine cooling system.";
CM_ SG_ 2566844160 EngCrankcasePress "Gage pressure inside engine crankcase.";
CM_ SG_ 2566844160 EngOilPress "Gage pressure of oil in engine lubrication system as provided by oil pump.";
CM_ SG_ 2566844160 EngOilLevel "Ratio of current volume of engine sump oil to maximum required volume.";
CM_ SG_ 2566844160 EngExCrankcaseBlowbyPress "Differential crankcase blow-by pressure as measured through a tube with a venturi.";
CM_ SG_ 2566844160 EngFuelDeliveryPress "Gage pressure of fuel in system as delivered from supply pump to the injection pump.";
CM_ BO_ 2566840064 "Electronic Engine Controller 3";
CM_ SG_ 2566840064 ExhaustGasMass "Measured/calculated exhaust gas mass upstream of the after-treatment system.";
CM_ SG_ 2566840064 EngsDesiredOperatingSpeed "An indication by the engine of the optimal operating speed of the engine for the current existing conditions.";
CM_ BO_ 2364539648 "Electronic Engine Controller 2";
CM_ SG_ 2364539648 ActMaxAvailEngPercentTorque "This is the maximum amount of torque that the engine can immediately deliver as a percentage of the reference engine torque.";
CM_ SG_ 2364539648 VhclAccelerationRateLimitStatus "Status (active or not active) of the system used to limit maximum forward vehicle acceleration.";
CM_ SG_ 2364539648 AccelPedal2LowIdleSwitch "Switch signal which indicates the state of the accelerator pedal 2 low idle switch.";
CM_ SG_ 2364539648 RoadSpeedLimitStatus "Status (active or not active) of the system used to limit maximum vehicle velocity.";
CM_ SG_ 2364539648 AccelPedalKickdownSwitch "Switch signal which indicates whether the accelerator pedal kickdown switch is opened or closed.";
CM_ SG_ 2364539648 AccelPedal1LowIdleSwitch "Switch signal which indicates the state of the accelerator pedal 1 low idle switch.";
CM_ BO_ 2364539904 "Electronic Engine Controller 1";
CM_ SG_ 2364539904 EngStarterMode "There are several phases in a starting action and different reasons why a start cannot take place.";
CM_ SG_ 2364539904 SrcAddrssOfCtrllngDvcForEngCtrl "The source address of the SAE J1939 device currently controlling the engine.";
CM_ SG_ 2364539904 EngSpeed "Actual engine speed which is calculated over a minimum crankshaft angle of 720 degrees divided by the number of cylinders.";
CM_ SG_ 2364539904 ActualEngPercentTorque "The calculated output torque of the engine.";
CM_ SG_ 2364539904 DriversDemandEngPercentTorque "The requested torque output of the engine by the driver.";
CM_ SG_ 2364539904 EngTorqueMode "State signal which indicates which engine torque mode is currently generating, limiting, or controlling the torque.";
CM_ BO_ 2566768126 "ECU Identification Information";
CM_ BO_ 2566841088 "Engine Configuration";
CM_ SG_ 2566841088 SupportTSC1CtrlPurposeGroup4Of4 "This parameter indicates which TSC1 control purposes are supported in group 4 of 4.";
CM_ SG_ 2566841088 SupportTSC1CtrlPurposeGroup3Of4 "This parameter indicates which TSC1 control purposes are supported in group 3 of 4.";
CM_ SG_ 2566841088 SupportTSC1CtrlPurposeGroup2Of4 "This parameter indicates which TSC1 control purposes are supported in group 2 of 4.";
CM_ SG_ 2566841088 SupportTSC1CtrlPurposeGroup1Of4 "This parameter indicates which TSC1 control purposes are supported in group 1 of 4.";
CM_ SG_ 2566841088 EngDefaultTorqueLimit "Companion parameter to Transmission Torque Limit (SPN 1845).";
CM_ SG_ 2566841088 EngMomentOfInertia "Moment of inertia for the engine, including items driven full-time by the engine such as fuel, oil and cooling pumps.";
CM_ SG_ 2566841088 EngRqdTorqueCtrlRangeUpperLimit "The maximum engine torque that the engine will allow when operating in a torque control/limit mode.";
CM_ SG_ 2566841088 EngRqdTorqueCtrlRangeLowerLimit "The minimum engine torque that the engine will allow when operating in a torque control/limit mode.";
CM_ SG_ 2566841088 EngRqedSpeedCtrlRangeLowerLimit "The minimum engine speed that the engine will allow when operating in a speed control/limit mode.";
CM_ SG_ 2566841088 EngMxMomentaryOverrideTimeLimit "The maximum time limit allowed to override the engine's high idle speed.";
CM_ SG_ 2566841088 EngMxMmntaryOverrideSpeedPoint7 "The maximum engine speed above high idle allowed by the engine control during a momentary high idle override.";
CM_ SG_ 2566841088 EngReferenceTorque "This parameter is the 100% reference value for all defined indicated engine torque parameters.";
CM_ SG_ 2566841088 EngSpeedAtHighIdlePoint6 "Engine speed of high idle (point 6) of the engine torque map (see PGN 65251 and supporting document).";
CM_ SG_ 2566841088 EngSpeedAtPoint5 "Engine speed of point 3, 4, and 5 of the engine torque map (see PGN 65251 and supporting document).";
CM_ SG_ 2566841088 EngSpeedAtPoint4 "Engine speed of point 3, 4, and 5 of the engine torque map (see PGN 65251 and supporting document).";
CM_ SG_ 2566841088 EngSpeedAtPoint3 "Engine speed of point 3, 4, and 5 of the engine torque map (see PGN 65251 and supporting document).";
CM_ SG_ 2566841088 EngSpeedAtPoint2 "Engine speed of point 2 of the engine torque map (see PGN 65251 and supporting document).";
CM_ SG_ 2566841088 EngPercentTorqueAtIdlePoint1 "The torque limit that indicates the available engine torque which can be provided by the engine at idle speed.";
CM_ BO_ 2566767627 "Electronic Brake Controller 5";
CM_ SG_ 2566767627 XBRAccelerationLimit "The brake system may temporarily or generally limit the maximum brake performance available for external systems.";
CM_ SG_ 2566767627 XBRActiveCtrlMode "This parameter indicates which XBR Control Mode is executed by the brake system.";
CM_ SG_ 2566767627 XBRSystemState "This parameter indicates which external brake control is allowed.";
CM_ SG_ 2566767627 FoundationBrakeUse "This parameter indicates if the brake system presently uses the foundation brakes.";
CM_ SG_ 2566767627 HillHolderMode "Signal which indicates the current mode of the hill holder function.";
CM_ SG_ 2566767627 HaltBrakeMode "Signal which indicates the current mode of the halt brake function.";
CM_ BO_ 2633935883 "Wheel Brake Lining Remaining Information";
CM_ SG_ 2633935883 BrkLnngRmnngRearAxle3RightWheel "The percentage of brake lining which can still be measured for the right wheel on the rear axle #3.";
CM_ SG_ 2633935883 BrkLnngRmningRearAxle3LeftWheel "The percentage of brake lining which can still be measured for the left wheel on the rear axle #3.";
CM_ SG_ 2633935883 BrkLnngRmnngRearAxle2RightWheel "The percentage of brake lining which can still be measured for the right wheel on the rear axle #2.";
CM_ SG_ 2633935883 BrkLnngRmningRearAxle2LeftWheel "The percentage of brake lining which can still be measured for the left wheel on the rear axle #2.";
CM_ SG_ 2633935883 BrkLnngRmnngRearAxle1RightWheel "The percentage of brake lining which can still be measured for the right wheel on the rear axle #1.";
CM_ SG_ 2633935883 BrkLnngRmningRearAxle1LeftWheel "The percentage of brake lining which can still be measured for the left wheel on the rear axle #1.";
CM_ SG_ 2633935883 BrkLnngRmnngFrontAxleRightWheel "The percentage of brake lining which can still be measured for the right wheel on the front axle.";
CM_ SG_ 2633935883 BrkLnngRmningFrontAxleLeftWheel "The percentage of brake lining which can still be measured for the left wheel on the front axle.";
CM_ BO_ 2566827275 "Wheel Application Pressure High Range Information";
CM_ SG_ 2566827275 BrkAppPrssHghRngRrAxl3RghtWheel "The brake application pressure for the right wheel on the rear axle #3.";
CM_ SG_ 2566827275 BrkAppPrssHghRngRrAxl3LeftWheel "The brake application pressure for the left wheel on the rear axle #3.";
CM_ SG_ 2566827275 BrkAppPrssHghRngRrAxl2RghtWheel "The brake application pressure for the right wheel on the rear axle #2.";
CM_ SG_ 2566827275 BrkAppPrssHghRngRrAxl2LeftWheel "The brake application pressure for the left wheel on the rear axle #2.";
CM_ SG_ 2566827275 BrkAppPrssHghRngRrAxl1RghtWheel "The brake application pressure for the right wheel on the rear axle #1.";
CM_ SG_ 2566827275 BrkAppPrssHghRngRrAxl1LeftWheel "The brake application pressure for the left wheel on the rear axle #1.";
CM_ SG_ 2566827275 BrkAppPrssHghRngFrntAxlRghtWhel "The brake application pressure for the right wheel on the front axle.";
CM_ SG_ 2566827275 BrkAppPrssHghRngFrntAxlLftWheel "The brake application pressure for the left wheel on the front axle.";
CM_ BO_ 2566831883 "Wheel Speed Information";
CM_ SG_ 2566831883 RlativeSpeedRearAxle2RightWheel "The speed of the rear axle #2, right wheel relative to the front axle speed, SPN 904.";
CM_ SG_ 2566831883 RelativeSpeedRearAxle2LeftWheel "The speed of the rear axle #2, left wheel relative to the front axle speed, SPN 904.";
CM_ SG_ 2566831883 RlativeSpeedRearAxle1RightWheel "The speed of the rear axle #1, right wheel relative to the front axle speed, SPN 904.";
CM_ SG_ 2566831883 RelativeSpeedRearAxle1LeftWheel "The speed of the rear axle #1, left wheel relative to the front axle speed, SPN 904.";
CM_ SG_ 2566831883 RlativeSpeedFrontAxleRightWheel "The speed of the front axle, right wheel relative to the front axle speed, SPN 904.";
CM_ SG_ 2566831883 RelativeSpeedFrontAxleLeftWheel "The speed of the front axle, left wheel relative to the front axle speed, SPN 904.";
CM_ SG_ 2566831883 FrontAxleSpeed "The average speed of the two front wheels.";
CM_ BO_ 2565865739 "Electronic Brake Controller 1";
CM_ SG_ 2565865739 SrcAddrssOfCtrllngDvcFrBrkCntrl "The source address of the SAE J1939 device currently controlling the brake system.";
CM_ SG_ 2565865739 BrakePedalPos "Ratio of brake pedal position to maximum pedal position.";
CM_ SG_ 2565865739 TrctrMntdTrilerABSWarningSignal "This parameter commands the tractor-mounted trailer ABS optical warning signal.";
CM_ SG_ 2565865739 TrailerABSStatus "State signal which indicates that ABS in the trailer is actively controlling the brakes.";
CM_ SG_ 2565865739 HaltBrakeSwitch "Switch signal which indicates the position of the halt brake switch.";
CM_ SG_ 2565865739 ATC_ASRInformationSignal "This parameter commands the ATC/ASR driver information signal, for example a dash lamp.";
CM_ SG_ 2565865739 RemoteAccelEnableSwitch "Switch signal which indicates that the remote accelerator has been enabled and controls the engine.";
CM_ SG_ 2565865739 EngAuxEngShutdownSwitch "Switch signal which requests that all engine fueling stop.";
CM_ SG_ 2565865739 EngDerateSwitch "Switch signal used to activate the torque limiting feature of the engine.";
CM_ SG_ 2565865739 AccelInterlockSwitch "Switch signal used to disable the accelerator and remote accelerator inputs, causing the engine to return to idle.";
CM_ SG_ 2565865739 TractionCtrlOverrideSwitch "Switch signal which indicates the position of the traction control override switch.";
CM_ SG_ 2565865739 ASRHillHolderSwitch "Switch signal which indicates the position of the ASR “hill holder” switch.";
CM_ SG_ 2565865739 ASROffroadSwitch "Switch signal which indicates the position of the ASR off-road switch.";
CM_ SG_ 2565865739 ABSOffroadSwitch "Switch signal which indicates the position of the ABS off-road switch.";
CM_ SG_ 2565865739 EBSBrakeSwitch "Switch signal which indicates that the brake pedal is being pressed.";
CM_ SG_ 2565865739 AntiLockBrakingActive "State signal which indicates that the ABS is active.";
CM_ SG_ 2565865739 ASRBrakeCtrlActive "State signal which indicates that ASR brake control is active.";
CM_ SG_ 2565865739 ASREngCtrlActive "State signal which indicates that ASR engine control has been commanded to be active.";
CM_ BO_ 2566810606 "Driver's Identification";
CM_ BO_ 2566847742 "Dash Display";
CM_ SG_ 2566847742 CargoAmbientTemp "Temperature of air inside vehicle container used to accommodate cargo.";
CM_ SG_ 2566847742 EngFuelFilterDiffPress "Differential pressure measured across the fuel filter located between the fuel tank and the supply pump.";
CM_ SG_ 2566847742 FuelLevel "Ratio of volume of fuel to the total volume of fuel storage container.";
CM_ SG_ 2566847742 WasherFluidLevel "Ratio of volume of liquid to total container volume of fluid reservoir in windshield wash system.";
CM_ BO_ 2564816921 "Cab Message 1";
CM_ SG_ 2564816921 RqCabZoneHeating "Request to activate cab zone heating.";
CM_ SG_ 2564816921 RqEngZoneHeating "Request to activate engine zone heating.";
CM_ SG_ 2564816921 AuxHeaterModeRq "Request to activate the auxiliary heater.";
CM_ SG_ 2564816921 EngAutomaticStartEnableSwitch "Switch signal which enables the idle management system to be enabled.";
CM_ SG_ 2564816921 VhclLmtngSpdGvrnrIncrmentSwitch "Switch signal which increases the Vehicle Limiting Speed Governor (VLSG).";
CM_ SG_ 2564816921 VhclLmtngSpdGvrnrDcrementSwitch "Switch signal which decreases the Vehicle Limiting Speed Governor (VLSG).";
CM_ SG_ 2564816921 BatteryMainSwitchHoldRq "Request to hold the battery main switch.";
CM_ SG_ 2564816921 AuxHeaterCoolantPumpRq "Indicates whether to activate the auxiliary heater coolant water pump.";
CM_ SG_ 2564816921 CabInteriorTempCmd "Parameter used to command a certain cab interior temperature.";
CM_ SG_ 2564816921 RqedPercentFanSpeed "Fan speed as a ratio of the actual fan drive (current speed) to the fully engaged fan drive (maximum fan speed).";
CM_ BO_ 2563833623 "Cab Illumination Message";
CM_ BO_ 2566844672 "Cruise Control/Vehicle Speed";
CM_ SG_ 2566844672 EngShutdownOverrideSwitch "Switch signal which indicates the position of the engine shutdown override switch.";
CM_ SG_ 2566844672 EngTestModeSwitch "Switch signal which indicates the position of the engine test mode switch.";
CM_ SG_ 2566844672 EngIdleDecrementSwitch "Switch signal which indicates the position of the idle decrement switch.";
CM_ SG_ 2566844672 EngIdleIncrementSwitch "Switch signal which indicates the position of the idle increment switch.";
CM_ SG_ 2566844672 CruiseCtrlStates "This parameter is used to indicate the current state, or mode, of operation by the cruise control device.";
CM_ SG_ 2566844672 PTOState "This parameter is used to indicate the current state or mode of operation by the power takeoff (PTO) device.";
CM_ SG_ 2566844672 CruiseCtrlSetSpeed "Value of set (chosen) velocity of velocity control system.";
CM_ SG_ 2566844672 CruiseCtrlAccelerateSwitch "Switch signal of the cruise control activator which indicates that the activator is in the position “accelerate.";
CM_ SG_ 2566844672 CruiseCtrlResumeSwitch "Switch signal of the cruise control activator which indicates that the activator is in the position “resume.";
CM_ SG_ 2566844672 CruiseCtrlCoastSwitch "Switch signal of the cruise control activator which indicates that the activator is in the position “coast (decelerate).";
CM_ SG_ 2566844672 CruiseCtrlSetSwitch "Switch signal of the cruise control activator which indicates that the activator is in the position “set.";
CM_ SG_ 2566844672 ClutchSwitch "Switch signal which indicates that the clutch pedal is being pressed.";
CM_ SG_ 2566844672 BrakeSwitch "Switch signal which indicates that the driver operated brake foot pedal is being pressed.";
CM_ SG_ 2566844672 CruiseCtrlEnableSwitch "Switch signal which indicates that it is possible to manage the cruise control function.";
CM_ SG_ 2566844672 CruiseCtrlActive "Cruise control is switched on.";
CM_ SG_ 2566844672 WheelBasedVehicleSpeed "Speed of the vehicle as calculated from wheel or tailshaft speed.";
CM_ SG_ 2566844672 CruiseCtrlPauseSwitch "Switch signal which indicates the position of the Cruise Control Pause Switch used on Remote Cruise Control applications.";
CM_ SG_ 2566844672 ParkingBrakeSwitch "Switch signal which indicates when the parking brake is set.";
CM_ SG_ 2566844672 TwoSpeedAxleSwitch "Switch signal which indicates the current axle range.";
CM_ BO_ 2566775065 "Cab A/C Climate System Information";
CM_ SG_ 2566775065 CbA_CRfrgrntCmprssorOutletPress "This is the gage pressure at the compressor outlet in the cab air conditioning system.";
CM_ BO_ 2566805807 "Air Suspension Control 3";
CM_ SG_ 2566805807 RelativeLevelRearAxleRight "Information of the height at the left side of the rear axle referred to normal level 1.";
CM_ SG_ 2566805807 RelativeLevelRearAxleLeft "Information of the height at the left side of the rear axle referred to normal level 1.";
CM_ SG_ 2566805807 RelativeLevelFrontAxleRight "Information of the height at the right side of the front axle referred to normal level 1.";
CM_ SG_ 2566805807 RelativeLevelFrontAxleLeft "Information of the height at the left side of the front axle referred to normal level 1.";
CM_ BO_ 2365479471 "Air Suspension Control 1";
CM_ SG_ 2365479471 SspensionCtrlRefusalInformation "Signal which indicates that the air suspension control cannot perform a request due to the operating conditions.";
CM_ SG_ 2365479471 SuspensionRemoteCtrl2 "Signal which indicates that the suspension system is controlled by remote control #2.";
CM_ SG_ 2365479471 SuspensionRemoteCtrl1 "Signal which indicates that the suspension system is controlled by remote control #1.";
CM_ SG_ 2365479471 RearAxleInBumperRange "Signal which indicates that the vehicle height at the rear axle (SPNs 1723 and 1724) is within the bumper range.";
CM_ SG_ 2365479471 FrontAxleInBumperRange "Signal which indicates that the vehicle height at the front axle (SPNs 1721 and 1722) is within the bumper range.";
CM_ SG_ 2365479471 DoorRelease "Signal which indicates that the doors may be opened.";
CM_ SG_ 2365479471 VehicleMotionInhibit "Signal which indicates whether vehicle motion is inhibited.";
CM_ SG_ 2365479471 SecurityDevice "The signal which indicates the status of the security device.";
CM_ SG_ 2365479471 AboveNominalLevelRearAxle "Signal which indicates whether the actual height of the rear axle is above the nominal (desired) level of the rear axle.";
CM_ SG_ 2365479471 AboveNominalLevelFrontAxle "Signal which indicates whether the actual height of the front axle is above the nominal (desired) level of the front axle.";
CM_ SG_ 2365479471 BelowNominalLevelRearAxle "Signal which indicates whether the actual height of the rear axle is below the nominal (desired) level for the rear axle.";
CM_ SG_ 2365479471 BelowNominalLevelFrontAxle "Signal which indicates whether the actual height of the front axle is below the nominal (desired) level for the front axle.";
CM_ SG_ 2365479471 NominalLevelRearAxle "Signal which indicates the nominal (desired) height of the rear axle to be controlled by the suspension system.";
CM_ SG_ 2365479471 NominalLevelFrontAxle "Signal which indicates the nominal (desired) height of the front axle to be controlled by the suspension system.";
CM_ SG_ 2365479471 LiftAxle2Pos "Signal which indicates the position / load condition of lift axle / tag axle #2.";
CM_ SG_ 2365479471 LiftAxle1Pos "Signal which indicates the position / load condition of lift axle / tag axle #1.";
CM_ BO_ 2566836222 "Pending DTCs";
CM_ SG_ 2566836222 DTC5 "Diagnostic Trouble Code";
CM_ SG_ 2566836222 DTC4 "Diagnostic Trouble Code";
CM_ SG_ 2566836222 DTC3 "Diagnostic Trouble Code";
CM_ SG_ 2566836222 DTC2 "Diagnostic Trouble Code";
CM_ SG_ 2566836222 DTC1 "Diagnostic Trouble Code";
CM_ SG_ 2566836222 FlashRedStopLamp "This parameter provides the capability to flash the RSL (SPN 3039).";
CM_ SG_ 2566836222 FlashProtectLamp "This parameter provides the capability to flash the engine protect lamp (SPN 3041).";
CM_ SG_ 2566836222 FlashMalfuncIndicatorLamp "This parameter provides the capability to flash the MIL (SPN 3038).";
CM_ SG_ 2566836222 MalfunctionIndicatorLampStatus "A lamp used to relay only emissions-related trouble code information.";
CM_ SG_ 2566836222 RedStopLampState "This lamp is uesed to relay trouble code information that is of a severe enought condition that it warrants stopping the vehicle.";
CM_ SG_ 2566836222 AmberWarningLampStatus "This lamp is used to relay trouble code information that is reporting a problem with the vehicle system but the vehicle need
not be immediately stopped.";
CM_ SG_ 2566836222 ProtectLampStatus "This lamp is used to relay trouble code informatio that is reporting a problem with a vehicle system that is most
probably not electronic subsystem related.";
CM_ BO_ 2566835966 "Diagnostic readiness 1";
CM_ SG_ 2566835966 OBDCompliance "Identifies the OBD compliance capabilityof the responding controller.";
CM_ SG_ 2566835966 PreviouslyActiveTroubleCodes "Identifies the number of previously active trouble codes that are present in a specific controller.";
CM_ SG_ 2566835966 ActiveTroubleCodes "Identifies the number of active trouble codes that are present in a specific controller.";
CM_ BO_ 2566835710 "Freeze frame parameters";
CM_ SG_ 2566835710 DTC1 "Diagnostic Trouble Code";
CM_ SG_ 2566835710 FreezeFrameLength "The freeze frame length shall be equal to the number of bytes in the required parameters plus the number of bytes in the
manufacturer specific parameters.";
CM_ SG_ 2566835710 EngSpeed "Actual engine speed which is calculated over a minimum crankshaft angle of 720 degrees divided by the number of cylinders.";
CM_ SG_ 2566835710 EngTorqueMode "State signal which indicates which engine torque mode is currently generating, limiting, or controlling the torque.";
CM_ SG_ 2566835710 EngTurboBoostPress "Gage pressure of air measured downstream on the compressor discharge side of the turbocharger.";
CM_ SG_ 2566835710 WheelBasedVehicleSpeed "Speed of the vehicle as calculated from wheel or tailshaft speed.";
CM_ BO_ 2566835454 "Diagnostic data clear/reset of previously active DTCs.";
CM_ BO_ 2566764542 "Expanded freeze frame.";
CM_ SG_ 2566764542 DTC1 "Diagnostic Trouble Code";
CM_ SG_ 2566764542 ExpandedFreezeFrameLength "The freeze frame length shall be equal to the number of bytes in the required parameters plus the number of bytes in the
manufacturer specific parameters.";
CM_ BO_ 2566764286 "SPN Support. This message is used to identify those SPNs supported by the product for freeze frames and data stream messages.";
CM_ SG_ 2566764286 SPNSupported1High "This parameter defines the SPN(s) that is/are supported for the freeze frame and/or data stream information.";
CM_ SG_ 2566764286 SPNSupportTypeSTR3 "This parameter defines whether the applicable parameter (that is the SPN) is supported in the freeze frame, the data stream or both the freeze frame and data stream.";
CM_ SG_ 2566764286 SPNSupportTypeSTR2 "This parameter defines whether the applicable parameter (that is the SPN) is supported in the freeze frame, the data stream or both the freeze frame and data stream.";
CM_ SG_ 2566764286 SPNSupportTypeEFF3 "This parameter defines whether the applicable parameter (that is the SPN) is supported in the freeze frame, the data stream or both the freeze frame and data stream.";
CM_ SG_ 2566764286 SPNSupportTypeEFF2 "This parameter defines whether the applicable parameter (that is the SPN) is supported in the freeze frame, the data stream or both the freeze frame and data stream.";
CM_ SG_ 2566764286 SPNSupportTypeDS3 "This parameter defines whether the applicable parameter (that is the SPN) is supported in the freeze frame, the data stream or both the freeze frame and data stream.";
CM_ SG_ 2566764286 SPNSupportTypeDS2 "This parameter defines whether the applicable parameter (that is the SPN) is supported in the freeze frame, the data stream or both the freeze frame and data stream.";
CM_ SG_ 2566764286 SPNSupported3High "This parameter defines the SPN(s) that is/are supported for the freeze frame and/or data stream information.";
CM_ SG_ 2566764286 SPNSupported2High "This parameter defines the SPN(s) that is/are supported for the freeze frame and/or data stream information.";
CM_ SG_ 2566764286 SPNSupported3 "This parameter defines the SPN(s) that is/are supported for the freeze frame and/or data stream information.";
CM_ SG_ 2566764286 SPNSupported2 "This parameter defines the SPN(s) that is/are supported for the freeze frame and/or data stream information.";
CM_ SG_ 2566764286 SPNDataLength3 "The number of data bytes associated with the SPN in the Freeze Frame.";
CM_ SG_ 2566764286 SPNSupportTypeSTR1 "This parameter defines whether the applicable parameter (that is the SPN) is supported in the freeze frame, the data stream or both the freeze frame and data stream.";
CM_ SG_ 2566764286 SPNSupportTypeDS1 "This parameter defines whether the applicable parameter (that is the SPN) is supported in the freeze frame, the data stream or both the freeze frame and data stream.";
CM_ SG_ 2566764286 SPNSupportTypeEFF1 "This parameter defines whether the applicable parameter (that is the SPN) is supported in the freeze frame, the data stream or both the freeze frame and data stream.";
CM_ SG_ 2566764286 SPNDataLength2 "The number of data bytes associated with the SPN in the Freeze Frame.";
CM_ SG_ 2566764286 SPNDataLength1 "The number of data bytes associated with the SPN in the Freeze Frame.";
CM_ SG_ 2566764286 SPNSupported1 "This parameter defines the SPN(s) that is/are supported for the freeze frame and/or data stream information.";
CM_ BO_ 2566835198 "Previously active diagnostic trouble codes";
CM_ SG_ 2566835198 DTC5 "Diagnostic Trouble Code";
CM_ SG_ 2566835198 DTC4 "Diagnostic Trouble Code";
CM_ SG_ 2566835198 DTC3 "Diagnostic Trouble Code";
CM_ SG_ 2566835198 DTC2 "Diagnostic Trouble Code";
CM_ SG_ 2566835198 DTC1 "Diagnostic Trouble Code";
CM_ SG_ 2566835198 MalfunctionIndicatorLampStatus "A lamp used to relay only emissions-related trouble code information.";
CM_ SG_ 2566835198 RedStopLampState "This lamp is uesed to relay trouble code information that is of a severe enought condition that it warrants stopping the vehicle.";
CM_ SG_ 2566835198 AmberWarningLampStatus "This lamp is used to relay trouble code information that is reporting a problem with the vehicle system but the vehicle need
not be immediately stopped.";
CM_ SG_ 2566835198 ProtectLampStatus "This lamp is used to relay trouble code informatio that is reporting a problem with a vehicle system that is most
probably not electronic subsystem related.";
CM_ SG_ 2566835198 FlashRedStopLamp "This parameter provides the capability to flash the RSL (SPN 3039).";
CM_ SG_ 2566835198 FlashProtectLamp "This parameter provides the capability to flash the engine protect lamp (SPN 3041).";
CM_ SG_ 2566835198 FlashMalfuncIndicatorLamp "This parameter provides the capability to flash the MIL (SPN 3038).";
CM_ SG_ 2566835198 FlashAmberWarningLamp "This parameter provides the capability to flash the AWL (SPN 3040). ";
CM_ BO_ 2564030206 "Calibration Information";
CM_ BO_ 2566837502 "Emissions-related active diagnostic trouble codes.";
CM_ SG_ 2566837502 DTC5 "Diagnostic Trouble Code";
CM_ SG_ 2566837502 DTC4 "Diagnostic Trouble Code";
CM_ SG_ 2566837502 DTC3 "Diagnostic Trouble Code";
CM_ SG_ 2566837502 DTC2 "Diagnostic Trouble Code";
CM_ SG_ 2566837502 FlashRedStopLamp "This parameter provides the capability to flash the RSL (SPN 3039).";
CM_ SG_ 2566837502 FlashProtectLamp "This parameter provides the capability to flash the engine protect lamp (SPN 3041).";
CM_ SG_ 2566837502 MalfunctionIndicatorLampStatus "A lamp used to relay only emissions-related trouble code information.";
CM_ SG_ 2566837502 RedStopLampState "This lamp is uesed to relay trouble code information that is of a severe enought condition that it warrants stopping the vehicle.";
CM_ SG_ 2566837502 AmberWarningLampStatus "This lamp is used to relay trouble code information that is reporting a problem with the vehicle system but the vehicle need
not be immediately stopped.";
CM_ SG_ 2566837502 ProtectLampStatus "This lamp is used to relay trouble code informatio that is reporting a problem with a vehicle system that is most
probably not electronic subsystem related.";
CM_ SG_ 2566837502 FlashMalfuncIndicatorLamp "This parameter provides the capability to flash the MIL (SPN 3038).";
CM_ SG_ 2566837502 FlashAmberWarningLamp "This parameter provides the capability to flash the AWL (SPN 3040). ";
CM_ SG_ 2566837502 SPN1 "SPN #1 (Conversion Version 4)";
CM_ BO_ 2566834942 "Active diagnostic trouble codes";
CM_ SG_ 2566834942 DTC5 "Diagnostic Trouble Code";
CM_ SG_ 2566834942 DTC4 "Diagnostic Trouble Code";
CM_ SG_ 2566834942 DTC3 "Diagnostic Trouble Code";
CM_ SG_ 2566834942 DTC2 "Diagnostic Trouble Code";
CM_ SG_ 2566834942 DTC1 "Diagnostic Trouble Code";
CM_ SG_ 2566834942 FlashRedStopLamp "This parameter provides the capability to flash the RSL (SPN 3039).";
CM_ SG_ 2566834942 FlashProtectLamp "This parameter provides the capability to flash the engine protect lamp (SPN 3041).";
CM_ SG_ 2566834942 FlashMalfuncIndicatorLamp "This parameter provides the capability to flash the MIL (SPN 3038).";
CM_ SG_ 2566834942 FlashAmberWarningLamp "This parameter provides the capability to flash the AWL (SPN 3040). ";
CM_ SG_ 2566834942 MalfunctionIndicatorLampStatus "A lamp used to relay only emissions-related trouble code information.";
CM_ SG_ 2566834942 AmberWarningLampStatus "This lamp is used to relay trouble code information that is reporting a problem with the vehicle system but the vehicle need
not be immediately stopped.";
CM_ SG_ 2566834942 RedStopLampState "This lamp is uesed to relay trouble code information that is of a severe enought condition that it warrants stopping the vehicle.";
CM_ SG_ 2566834942 ProtectLampStatus "This lamp is used to relay trouble code informatio that is reporting a problem with a vehicle system that is most
probably not electronic subsystem related.";
CM_ BO_ 2565799678 "Address Claimed";
CM_ SG_ 2565799678 IndustryGroup "0 = Global; 
   1  = On-Highway; 
   2  = Agricultural and Forestry; 
   3  = Construction; 
   4  = Marine;
   5  = Industrial - Process
          Control - Stationary (Gen-Sets)
   6  = Reserve for SAE
   7  = Reserve for SAE";
CM_ SG_ 2565799678 ManufacturerCode "Assigned by NMEA 2000 Committee";
CM_ BO_ 2563440382 "Transfer";
CM_ SG_ 2563440382 ShrtNameOfActualReportingDevice "Short name of reporting device of the requested PGN via the Transfer PGN.";
CM_ SG_ 2563440382 LengthOfDataForTheReportedPGN "Length of data reported with the associated PGN via the Transfer PGN.";
CM_ SG_ 2563440382 PGNofRequstedInformation "PGN associated with this transfer message";
CM_ BO_ 2565603070 "Transport Protocol - Data Transfer";
CM_ BO_ 2565668606 "Transport Protocol - Connection Management";
CM_ SG_ 2565668606 TotalNumberOfPacketsEoMA "Total number of packets for BAM message.Total number of packets received for RTS/CTS message.Total number of packets for RTS/CTS message.";
CM_ SG_ 2565668606 TotalMessageSizeEoMA "Total message size (in bytes) for BAM message.Total message size (in bytes) for RTS/CTS message.Total message size (in bytes) for RTS/CTS message.";
CM_ SG_ 2565668606 TotalMessageSizeBAM "Total message size (in bytes) for BAM message.Total message size (in bytes) for RTS/CTS message.Total message size (in bytes) for RTS/CTS message.";
CM_ SG_ 2565668606 TotalNumberOfPacketsBAM "Total number of packets for BAM message.Total number of packets received for RTS/CTS message.Total number of packets for RTS/CTS message.";
CM_ SG_ 2565668606 ConnectionAbortReason "Reason for connection abort message.";
CM_ SG_ 2565668606 NextPacketNumberToBeSent "Next Packet Number to be sent (TP.CM_CTS)";
CM_ SG_ 2565668606 NumberOfPacketsThatCanBeSent "Number of Packets that can be sent (TP.CM_CTS)";
CM_ SG_ 2565668606 MaximumNumberOfPackets "Maximum number of packets for RTS/CTS message.";
CM_ SG_ 2565668606 TotalNumberOfPackets "Total number of packets for BAM message.Total number of packets received for RTS/CTS message.Total number of packets for RTS/CTS message.";
CM_ SG_ 2565668606 TotalMessageSize "Total message size (in bytes) for BAM message.Total message size (in bytes) for RTS/CTS message.Total message size (in bytes) for RTS/CTS message.";
CM_ BO_ 2563374846 "Request 2";
CM_ SG_ 2563374846 UseTransferMode "Requester is to respond via the Transfer PGN";
CM_ SG_ 2563374846 ParameterGroupNumber "PGN which is requested by Request2 message";
CM_ BO_ 2565537534 "Request";
CM_ SG_ 2565537534 ParameterGroupNumber "PGN which is requested by Request2 message";
CM_ BO_ 2566845696 "Ambient Conditions";
CM_ SG_ 2566845696 RoadSurfaceTemp "Indicated temperature of road surface over which vehicle is operating.";
CM_ SG_ 2566845696 EngAirInletTemp "Temperature of air entering vehicle air induction system.";
CM_ SG_ 2566845696 AmbientAirTemp "Temperature of air surrounding vehicle.";
CM_ SG_ 2566845696 CabInteriorTemp "Temperature of air inside the part of the vehicle that encloses the driver and vehicle operating controls.";
CM_ SG_ 2566845696 BarometricPress "Absolute air pressure of the atmosphere.";
CM_ BO_ 2565406462 "Acknowledgment Message";
CM_ SG_ 2565406462 ParameterGroupNumber "PGN which is requested by Request2 message";
CM_ SG_ 2565406462 GroupFunctionValue "Indicates the acknowledgement response.Indicates the acknowledgement response.Negative Acknowledgement Group Function valuePositive Acknowledgement Group Function value";
CM_ BO_ 2566846467 "Transmission Fluids 1";
CM_ SG_ 2566846467 TransOilLevelHigh_Low "Amount of current volume of transmission sump oil compared to recommended volume.";
CM_ SG_ 2566846467 TransOilTemp "Temperature of the transmission lubricant.";
CM_ SG_ 2566846467 TransOilPress "Gage pressure of lubrication fluid in transmission, measured after pump.";
CM_ SG_ 2566846467 TransOilLevel "Ratio of volume of transmission sump oil to recommended volume.";
CM_ SG_ 2566846467 ClutchPress "Gage pressure of oil within a wet clutch.";
CM_ BO_ 2566846451 "Vehicle Electrical Power #1";
CM_ SG_ 2566846451 BatteryPotentialSwitched "Electrical potential measured at the input of the electronic control unit supplied through a switching device.";
CM_ SG_ 2566846451 ElectricalPotential "Measured electrical potential of the battery.";
CM_ SG_ 2566846451 ChargingSystemPotential "Electrical potential measured at the charging system output.";
CM_ SG_ 2566846451 AltCurrent "Measure of electrical current flow from the alternator.";
CM_ SG_ 2566846451 NetBatteryCurrent "Net flow of electrical current into/out of the battery or batteries.";
CM_ EV_ EnvTPMS_Recalibrate "Recalibrate tire monitoring system";
BA_DEF_ SG_  "SigType" ENUM  "Default","Range","RangeSigned","ASCII","Discrete","Control","ReferencePGN","DTC","StringDelimiter","StringLength","StringLengthControl";
BA_DEF_ SG_  "GenSigStartValue" FLOAT 0 10000;
BA_DEF_ SG_  "GenSigSendType" ENUM  "Cyclic","OnWrite","reserved","OnChange","reserved","reserved","reserved","NoSigSendType";
BA_DEF_ SG_  "GenSigILSupport" ENUM  "Yes","No";
BA_DEF_ BO_  "GenMsgILSupport" ENUM  "Yes","No";
BA_DEF_ SG_  "SPN" INT 0 524287;
BA_DEF_ BO_  "GenMsgRequestable" INT 0 1;
BA_DEF_ BO_  "GenMsgSendType" ENUM  "cyclic","reserved","cyclicIfActive","reserved","reserved","reserved","reserved","reserved","noMsgSendType";
BA_DEF_ BO_  "VFrameFormat" ENUM  "StandardCAN","ExtendedCAN","reserved","J1939PG";
BA_DEF_ BO_  "GenMsgCycleTime" INT 0 3600000;
BA_DEF_DEF_  "SigType" "Default";
BA_DEF_DEF_  "GenSigStartValue" 0;
BA_DEF_DEF_  "GenSigSendType" "NoSigSendType";
BA_DEF_DEF_  "GenSigILSupport" "Yes";
BA_DEF_DEF_  "GenMsgILSupport" "Yes";
BA_DEF_DEF_  "SPN" 0;
BA_DEF_DEF_  "GenMsgRequestable" 1;
BA_DEF_DEF_  "GenMsgSendType" "noMsgSendType";
BA_DEF_DEF_  "VFrameFormat" "J1939PG";
BA_DEF_DEF_  "GenMsgCycleTime" 0;
BA_ "GenMsgSendType" BO_ 2566801923 0;
BA_ "GenMsgCycleTime" BO_ 2566801923 100;
BA_ "GenMsgSendType" BO_ 2565866755 0;
BA_ "GenMsgCycleTime" BO_ 2565866755 100;
BA_ "GenMsgSendType" BO_ 2364539395 0;
BA_ "GenMsgCycleTime" BO_ 2364539395 10;
BA_ "GenMsgSendType" BO_ 2566824960 0;
BA_ "GenMsgCycleTime" BO_ 2566824960 1000;
BA_ "GenMsgSendType" BO_ 2566843904 0;
BA_ "GenMsgCycleTime" BO_ 2566843904 1000;
BA_ "GenMsgSendType" BO_ 2565865513 0;
BA_ "GenMsgCycleTime" BO_ 2565865513 100;
BA_ "GenMsgSendType" BO_ 2566844160 0;
BA_ "GenMsgCycleTime" BO_ 2566844160 500;
BA_ "GenMsgSendType" BO_ 2566840064 0;
BA_ "GenMsgCycleTime" BO_ 2566840064 250;
BA_ "GenMsgSendType" BO_ 2364539648 0;
BA_ "GenMsgCycleTime" BO_ 2364539648 50;
BA_ "GenMsgSendType" BO_ 2364539904 0;
BA_ "GenMsgCycleTime" BO_ 2364539904 100;
BA_ "GenMsgSendType" BO_ 2566767627 0;
BA_ "GenMsgCycleTime" BO_ 2566767627 100;
BA_ "GenMsgSendType" BO_ 2566827275 0;
BA_ "GenMsgCycleTime" BO_ 2566827275 100;
BA_ "GenMsgSendType" BO_ 2566831883 0;
BA_ "GenMsgCycleTime" BO_ 2566831883 100;
BA_ "GenMsgSendType" BO_ 2565865739 0;
BA_ "GenMsgCycleTime" BO_ 2565865739 100;
BA_ "GenMsgSendType" BO_ 2566847742 0;
BA_ "GenMsgCycleTime" BO_ 2566847742 1000;
BA_ "GenMsgSendType" BO_ 2564816921 0;
BA_ "GenMsgCycleTime" BO_ 2564816921 1000;
BA_ "GenMsgSendType" BO_ 2566844672 0;
BA_ "GenMsgCycleTime" BO_ 2566844672 100;
BA_ "GenMsgSendType" BO_ 2566775065 0;
BA_ "GenMsgCycleTime" BO_ 2566775065 1000;
BA_ "GenMsgSendType" BO_ 2566805807 0;
BA_ "GenMsgCycleTime" BO_ 2566805807 100;
BA_ "GenMsgSendType" BO_ 2365479471 0;
BA_ "GenMsgCycleTime" BO_ 2365479471 100;
BA_ "GenMsgSendType" BO_ 2566845696 0;
BA_ "GenMsgCycleTime" BO_ 2566845696 1000;
BA_ "GenMsgSendType" BO_ 2566846467 0;
BA_ "GenMsgCycleTime" BO_ 2566846467 1000;
BA_ "GenMsgSendType" BO_ 2566846451 0;
BA_ "GenMsgCycleTime" BO_ 2566846451 1000;
BA_ "SPN" SG_ 2566801923 TransRqedGearFeedback 3289;
BA_ "SigType" SG_ 2566801923 TransRqedGearFeedback 1;
BA_ "SPN" SG_ 2566801923 TransMode1Indicator 2536;
BA_ "SigType" SG_ 2566801923 TransMode1Indicator 4;
BA_ "SPN" SG_ 2566801923 TransMode2Indicator 2537;
BA_ "SigType" SG_ 2566801923 TransMode2Indicator 4;
BA_ "SPN" SG_ 2566801923 TransMode3Indicator 2538;
BA_ "SigType" SG_ 2566801923 TransMode3Indicator 4;
BA_ "SPN" SG_ 2566801923 TransMode4Indicator 2539;
BA_ "SigType" SG_ 2566801923 TransMode4Indicator 4;
BA_ "SPN" SG_ 2566801923 TransShiftInhibitIndicator 1851;
BA_ "SigType" SG_ 2566801923 TransShiftInhibitIndicator 4;
BA_ "SPN" SG_ 2566801923 TransEngCrankEnable 2900;
BA_ "SigType" SG_ 2566801923 TransEngCrankEnable 4;
BA_ "SPN" SG_ 2566801923 ActiveShiftConsoleIndicator 2945;
BA_ "SigType" SG_ 2566801923 ActiveShiftConsoleIndicator 4;
BA_ "SPN" SG_ 2566801923 TransReadyForBrakeRelease 3086;
BA_ "SigType" SG_ 2566801923 TransReadyForBrakeRelease 4;
BA_ "SPN" SG_ 2566801923 TransRqedRangeDisplayFlashState 1849;
BA_ "SigType" SG_ 2566801923 TransRqedRangeDisplayFlashState 4;
BA_ "SPN" SG_ 2566801923 TransRqedRangeDisplayBlankState 1850;
BA_ "SigType" SG_ 2566801923 TransRqedRangeDisplayBlankState 4;
BA_ "SPN" SG_ 2565866755 TransCurrentRange 163;
BA_ "SigType" SG_ 2565866755 TransCurrentRange 1;
BA_ "SPN" SG_ 2565866755 TransRqedRange 162;
BA_ "SigType" SG_ 2565866755 TransRqedRange 1;
BA_ "SPN" SG_ 2565866755 TransCurrentGear 523;
BA_ "SigType" SG_ 2565866755 TransCurrentGear 1;
BA_ "SPN" SG_ 2565866755 TransActualGearRatio 526;
BA_ "SigType" SG_ 2565866755 TransActualGearRatio 1;
BA_ "SPN" SG_ 2565866755 TransSelectedGear 524;
BA_ "SigType" SG_ 2565866755 TransSelectedGear 1;
BA_ "GenSigStartValue" SG_ 2364539395 SrcAddrssOfCtrllngDvcFrTrnsCtrl 3;
BA_ "SPN" SG_ 2364539395 SrcAddrssOfCtrllngDvcFrTrnsCtrl 1482;
BA_ "SigType" SG_ 2364539395 SrcAddrssOfCtrllngDvcFrTrnsCtrl 1;
BA_ "SPN" SG_ 2364539395 TransInputShaftSpeed 161;
BA_ "SigType" SG_ 2364539395 TransInputShaftSpeed 1;
BA_ "SPN" SG_ 2364539395 ProgressiveShiftDisable 607;
BA_ "SigType" SG_ 2364539395 ProgressiveShiftDisable 4;
BA_ "SPN" SG_ 2364539395 EngMomentaryOverspeedEnable 606;
BA_ "SigType" SG_ 2364539395 EngMomentaryOverspeedEnable 4;
BA_ "SPN" SG_ 2364539395 PercentClutchSlip 522;
BA_ "SigType" SG_ 2364539395 PercentClutchSlip 1;
BA_ "SPN" SG_ 2364539395 TransOutputShaftSpeed 191;
BA_ "SigType" SG_ 2364539395 TransOutputShaftSpeed 1;
BA_ "SPN" SG_ 2364539395 TransShiftInProcess 574;
BA_ "SigType" SG_ 2364539395 TransShiftInProcess 4;
BA_ "SPN" SG_ 2364539395 TorqueConverterLockupEngaged 573;
BA_ "SigType" SG_ 2364539395 TorqueConverterLockupEngaged 4;
BA_ "SPN" SG_ 2364539395 TransDrivelineEngaged 560;
BA_ "SigType" SG_ 2364539395 TransDrivelineEngaged 4;
BA_ "SPN" SG_ 2566824960 EngExhaustGasRecirculationTemp 412;
BA_ "SigType" SG_ 2566824960 EngExhaustGasRecirculationTemp 1;
BA_ "SPN" SG_ 2566824960 EngExhstGsRcirculationDiffPress 411;
BA_ "SigType" SG_ 2566824960 EngExhstGsRcirculationDiffPress 1;
BA_ "SPN" SG_ 2566824960 EngECUTemp 1136;
BA_ "SigType" SG_ 2566824960 EngECUTemp 1;
BA_ "SPN" SG_ 2566824960 EngOilTemp2 1135;
BA_ "SigType" SG_ 2566824960 EngOilTemp2 1;
BA_ "SPN" SG_ 2566843904 EngIntercoolerThermostatOpening 1134;
BA_ "SigType" SG_ 2566843904 EngIntercoolerThermostatOpening 1;
BA_ "SPN" SG_ 2566843904 EngIntercoolerTemp 52;
BA_ "SigType" SG_ 2566843904 EngIntercoolerTemp 1;
BA_ "SPN" SG_ 2566843904 EngTurboOilTemp 176;
BA_ "SigType" SG_ 2566843904 EngTurboOilTemp 1;
BA_ "SPN" SG_ 2566843904 EngOilTemp1 175;
BA_ "SigType" SG_ 2566843904 EngOilTemp1 1;
BA_ "SPN" SG_ 2566843904 EngFuelTemp 174;
BA_ "SigType" SG_ 2566843904 EngFuelTemp 1;
BA_ "SPN" SG_ 2566843904 EngCoolantTemp 110;
BA_ "SigType" SG_ 2566843904 EngCoolantTemp 1;
BA_ "SPN" SG_ 2565865513 RetarderSelectionNonEng 1716;
BA_ "SigType" SG_ 2565865513 RetarderSelectionNonEng 1;
BA_ "SPN" SG_ 2565865513 ActlMxAvlblRtarderPercentTorque 1717;
BA_ "SigType" SG_ 2565865513 ActlMxAvlblRtarderPercentTorque 1;
BA_ "SPN" SG_ 2565865513 DrvrsDmandRetarderPercentTorque 1715;
BA_ "SigType" SG_ 2565865513 DrvrsDmandRetarderPercentTorque 1;
BA_ "SPN" SG_ 2565865513 SrcAddrssOfCtrllngDvcFrRtrdrCtrl 1480;
BA_ "SigType" SG_ 2565865513 SrcAddrssOfCtrllngDvcFrRtrdrCtrl 1;
BA_ "SPN" SG_ 2565865513 RetarderRqingBrakeLight 1667;
BA_ "SigType" SG_ 2565865513 RetarderRqingBrakeLight 4;
BA_ "SPN" SG_ 2565865513 EngCoolantLoadIncrease 1082;
BA_ "SigType" SG_ 2565865513 EngCoolantLoadIncrease 4;
BA_ "SPN" SG_ 2565865513 IntendedRetarderPercentTorque 1085;
BA_ "SigType" SG_ 2565865513 IntendedRetarderPercentTorque 1;
BA_ "SPN" SG_ 2565865513 ActualRetarderPercentTorque 520;
BA_ "SigType" SG_ 2565865513 ActualRetarderPercentTorque 1;
BA_ "SPN" SG_ 2565865513 RetarderEnableShiftAssistSwitch 572;
BA_ "SigType" SG_ 2565865513 RetarderEnableShiftAssistSwitch 4;
BA_ "SPN" SG_ 2565865513 RetarderEnableBrakeAssistSwitch 571;
BA_ "SigType" SG_ 2565865513 RetarderEnableBrakeAssistSwitch 4;
BA_ "SPN" SG_ 2565865513 RetarderTorqueMode 900;
BA_ "SigType" SG_ 2565865513 RetarderTorqueMode 4;
BA_ "SPN" SG_ 2633935104 EngExhstGsOxygnSnsrClsdLpOprton 1696;
BA_ "SigType" SG_ 2633935104 EngExhstGsOxygnSnsrClsdLpOprton 4;
BA_ "SPN" SG_ 2633935104 EngExhstGsOxygnSnsrFlngCrrction 1695;
BA_ "SigType" SG_ 2633935104 EngExhstGsOxygnSnsrFlngCrrction 1;
BA_ "SPN" SG_ 2633935104 EngActualExhaustOxygen 1119;
BA_ "SigType" SG_ 2633935104 EngActualExhaustOxygen 1;
BA_ "SPN" SG_ 2633935104 EngDesiredExhaustOxygen 1118;
BA_ "SigType" SG_ 2633935104 EngDesiredExhaustOxygen 1;
BA_ "SPN" SG_ 2633935104 EngDesiredRatedExhaustOxygen 1117;
BA_ "SigType" SG_ 2633935104 EngDesiredRatedExhaustOxygen 1;
BA_ "SPN" SG_ 2566844160 EngCoolantLevel 111;
BA_ "SigType" SG_ 2566844160 EngCoolantLevel 1;
BA_ "SPN" SG_ 2566844160 EngCoolantPress 109;
BA_ "SigType" SG_ 2566844160 EngCoolantPress 1;
BA_ "SPN" SG_ 2566844160 EngCrankcasePress 101;
BA_ "SigType" SG_ 2566844160 EngCrankcasePress 1;
BA_ "SPN" SG_ 2566844160 EngOilPress 100;
BA_ "SigType" SG_ 2566844160 EngOilPress 1;
BA_ "SPN" SG_ 2566844160 EngOilLevel 98;
BA_ "SigType" SG_ 2566844160 EngOilLevel 1;
BA_ "SPN" SG_ 2566844160 EngExCrankcaseBlowbyPress 22;
BA_ "SigType" SG_ 2566844160 EngExCrankcaseBlowbyPress 1;
BA_ "SPN" SG_ 2566844160 EngFuelDeliveryPress 94;
BA_ "SigType" SG_ 2566844160 EngFuelDeliveryPress 1;
BA_ "SPN" SG_ 2566840064 ExhaustGasMass 3236;
BA_ "SigType" SG_ 2566840064 ExhaustGasMass 1;
BA_ "SPN" SG_ 2566840064 AftrTrtmntIntakeDewPointMessage 3237;
BA_ "SPN" SG_ 2566840064 AftrTrtmntExhustDewPointMessage 3238;
BA_ "SPN" SG_ 2566840064 EstEngPrsticLossesPercentTorque 2978;
BA_ "SigType" SG_ 2566840064 EstEngPrsticLossesPercentTorque 1;
BA_ "SPN" SG_ 2566840064 EngsDsrdOprtngSpdAsymmtryAdjstmn 519;
BA_ "SigType" SG_ 2566840064 EngsDsrdOprtngSpdAsymmtryAdjstmn 1;
BA_ "SPN" SG_ 2566840064 EngsDesiredOperatingSpeed 515;
BA_ "SigType" SG_ 2566840064 EngsDesiredOperatingSpeed 1;
BA_ "SPN" SG_ 2566840064 NominalFrictionPercentTorque 514;
BA_ "SigType" SG_ 2566840064 NominalFrictionPercentTorque 1;
BA_ "SPN" SG_ 2364539648 ActMaxAvailEngPercentTorque 3357;
BA_ "SigType" SG_ 2364539648 ActMaxAvailEngPercentTorque 1;
BA_ "SPN" SG_ 2364539648 AccelPedalPos2 29;
BA_ "SigType" SG_ 2364539648 AccelPedalPos2 1;
BA_ "SPN" SG_ 2364539648 VhclAccelerationRateLimitStatus 2979;
BA_ "SigType" SG_ 2364539648 VhclAccelerationRateLimitStatus 4;
BA_ "SPN" SG_ 2364539648 EngPercentLoadAtCurrentSpeed 92;
BA_ "SigType" SG_ 2364539648 EngPercentLoadAtCurrentSpeed 1;
BA_ "SPN" SG_ 2364539648 AccelPedal2LowIdleSwitch 2970;
BA_ "SigType" SG_ 2364539648 AccelPedal2LowIdleSwitch 4;
BA_ "SPN" SG_ 2364539648 RoadSpeedLimitStatus 1437;
BA_ "SigType" SG_ 2364539648 RoadSpeedLimitStatus 4;
BA_ "SPN" SG_ 2364539648 AccelPedalKickdownSwitch 559;
BA_ "SigType" SG_ 2364539648 AccelPedalKickdownSwitch 4;
BA_ "SPN" SG_ 2364539648 AccelPedal1LowIdleSwitch 558;
BA_ "SigType" SG_ 2364539648 AccelPedal1LowIdleSwitch 4;
BA_ "SPN" SG_ 2364539648 RemoteAccelPedalPos 974;
BA_ "SigType" SG_ 2364539648 RemoteAccelPedalPos 1;
BA_ "SPN" SG_ 2364539648 AccelPedalPos1 91;
BA_ "SigType" SG_ 2364539648 AccelPedalPos1 1;
BA_ "SPN" SG_ 2364539904 EngDemandPercentTorque 2432;
BA_ "SigType" SG_ 2364539904 EngDemandPercentTorque 1;
BA_ "SPN" SG_ 2364539904 EngStarterMode 1675;
BA_ "SigType" SG_ 2364539904 EngStarterMode 4;
BA_ "SPN" SG_ 2364539904 SrcAddrssOfCtrllngDvcForEngCtrl 1483;
BA_ "SigType" SG_ 2364539904 SrcAddrssOfCtrllngDvcForEngCtrl 1;
BA_ "SPN" SG_ 2364539904 EngSpeed 190;
BA_ "SigType" SG_ 2364539904 EngSpeed 1;
BA_ "SPN" SG_ 2364539904 ActualEngPercentTorque 513;
BA_ "SigType" SG_ 2364539904 ActualEngPercentTorque 1;
BA_ "SPN" SG_ 2364539904 DriversDemandEngPercentTorque 512;
BA_ "SigType" SG_ 2364539904 DriversDemandEngPercentTorque 1;
BA_ "SPN" SG_ 2364539904 EngTorqueMode 899;
BA_ "SigType" SG_ 2364539904 EngTorqueMode 4;
BA_ "SigType" SG_ 2566768126 ECUType 8;
BA_ "SPN" SG_ 2566768126 ECUType 2904;
BA_ "SigType" SG_ 2566768126 ECUSerialNumber 8;
BA_ "SPN" SG_ 2566768126 ECUSerialNumber 2902;
BA_ "SigType" SG_ 2566768126 ECUPartNumber 8;
BA_ "SPN" SG_ 2566768126 ECUPartNumber 2901;
BA_ "SigType" SG_ 2566768126 ECULocation 8;
BA_ "SPN" SG_ 2566768126 ECULocation 2903;
BA_ "SPN" SG_ 2566841088 SupportTSC1CtrlPurposeGroup4Of4 3348;
BA_ "SigType" SG_ 2566841088 SupportTSC1CtrlPurposeGroup4Of4 1;
BA_ "SPN" SG_ 2566841088 SupportVariableRateTSC1Message 3344;
BA_ "SigType" SG_ 2566841088 SupportVariableRateTSC1Message 1;
BA_ "SPN" SG_ 2566841088 SupportTSC1CtrlPurposeGroup3Of4 3347;
BA_ "SigType" SG_ 2566841088 SupportTSC1CtrlPurposeGroup3Of4 1;
BA_ "SPN" SG_ 2566841088 SupportTSC1CtrlPurposeGroup2Of4 3346;
BA_ "SigType" SG_ 2566841088 SupportTSC1CtrlPurposeGroup2Of4 1;
BA_ "SPN" SG_ 2566841088 SupportTSC1CtrlPurposeGroup1Of4 3345;
BA_ "SigType" SG_ 2566841088 SupportTSC1CtrlPurposeGroup1Of4 1;
BA_ "SPN" SG_ 2566841088 EngDefaultTorqueLimit 1846;
BA_ "SigType" SG_ 2566841088 EngDefaultTorqueLimit 1;
BA_ "SPN" SG_ 2566841088 EngMomentOfInertia 1794;
BA_ "SigType" SG_ 2566841088 EngMomentOfInertia 1;
BA_ "SPN" SG_ 2566841088 EngExRngRqdSpdCtrlRngUpperLimit 1712;
BA_ "SigType" SG_ 2566841088 EngExRngRqdSpdCtrlRngUpperLimit 1;
BA_ "SPN" SG_ 2566841088 EngRqdTorqueCtrlRangeUpperLimit 538;
BA_ "SigType" SG_ 2566841088 EngRqdTorqueCtrlRangeUpperLimit 1;
BA_ "SPN" SG_ 2566841088 EngRqdTorqueCtrlRangeLowerLimit 537;
BA_ "SigType" SG_ 2566841088 EngRqdTorqueCtrlRangeLowerLimit 1;
BA_ "SPN" SG_ 2566841088 EngRqedSpeedCtrlRangeUpperLimit 536;
BA_ "SigType" SG_ 2566841088 EngRqedSpeedCtrlRangeUpperLimit 1;
BA_ "SPN" SG_ 2566841088 EngRqedSpeedCtrlRangeLowerLimit 535;
BA_ "SigType" SG_ 2566841088 EngRqedSpeedCtrlRangeLowerLimit 1;
BA_ "SPN" SG_ 2566841088 EngMxMomentaryOverrideTimeLimit 534;
BA_ "SigType" SG_ 2566841088 EngMxMomentaryOverrideTimeLimit 1;
BA_ "SPN" SG_ 2566841088 EngMxMmntaryOverrideSpeedPoint7 533;
BA_ "SigType" SG_ 2566841088 EngMxMmntaryOverrideSpeedPoint7 1;
BA_ "SPN" SG_ 2566841088 EngReferenceTorque 544;
BA_ "SigType" SG_ 2566841088 EngReferenceTorque 1;
BA_ "SPN" SG_ 2566841088 EngSpeedAtHighIdlePoint6 532;
BA_ "SigType" SG_ 2566841088 EngSpeedAtHighIdlePoint6 1;
BA_ "SPN" SG_ 2566841088 EngGainOfEndspeedGovernor 545;
BA_ "SigType" SG_ 2566841088 EngGainOfEndspeedGovernor 1;
BA_ "SPN" SG_ 2566841088 EngPercentTorqueAtPoint5 543;
BA_ "SigType" SG_ 2566841088 EngPercentTorqueAtPoint5 1;
BA_ "SPN" SG_ 2566841088 EngSpeedAtPoint5 531;
BA_ "SigType" SG_ 2566841088 EngSpeedAtPoint5 1;
BA_ "SPN" SG_ 2566841088 EngPercentTorqueAtPoint4 542;
BA_ "SigType" SG_ 2566841088 EngPercentTorqueAtPoint4 1;
BA_ "SPN" SG_ 2566841088 EngSpeedAtPoint4 530;
BA_ "SigType" SG_ 2566841088 EngSpeedAtPoint4 1;
BA_ "SPN" SG_ 2566841088 EngPercentTorqueAtPoint3 541;
BA_ "SigType" SG_ 2566841088 EngPercentTorqueAtPoint3 1;
BA_ "SPN" SG_ 2566841088 EngSpeedAtPoint3 529;
BA_ "SigType" SG_ 2566841088 EngSpeedAtPoint3 1;
BA_ "SPN" SG_ 2566841088 EngPercentTorqueAtPoint2 540;
BA_ "SigType" SG_ 2566841088 EngPercentTorqueAtPoint2 1;
BA_ "SPN" SG_ 2566841088 EngSpeedAtPoint2 528;
BA_ "SigType" SG_ 2566841088 EngSpeedAtPoint2 1;
BA_ "SPN" SG_ 2566841088 EngPercentTorqueAtIdlePoint1 539;
BA_ "SigType" SG_ 2566841088 EngPercentTorqueAtIdlePoint1 1;
BA_ "SPN" SG_ 2566841088 EngSpeedAtIdlePoint1 188;
BA_ "SigType" SG_ 2566841088 EngSpeedAtIdlePoint1 1;
BA_ "SPN" SG_ 2566767627 XBRAccelerationLimit 2921;
BA_ "SigType" SG_ 2566767627 XBRAccelerationLimit 1;
BA_ "SPN" SG_ 2566767627 XBRActiveCtrlMode 2918;
BA_ "SigType" SG_ 2566767627 XBRActiveCtrlMode 4;
BA_ "SPN" SG_ 2566767627 XBRSystemState 2917;
BA_ "SigType" SG_ 2566767627 XBRSystemState 4;
BA_ "SPN" SG_ 2566767627 FoundationBrakeUse 2919;
BA_ "SigType" SG_ 2566767627 FoundationBrakeUse 4;
BA_ "SPN" SG_ 2566767627 HillHolderMode 2912;
BA_ "SigType" SG_ 2566767627 HillHolderMode 4;
BA_ "SPN" SG_ 2566767627 HaltBrakeMode 2913;
BA_ "SigType" SG_ 2566767627 HaltBrakeMode 4;
BA_ "SPN" SG_ 2633935883 BrkLnngRmnngRearAxle3RightWheel 1106;
BA_ "SigType" SG_ 2633935883 BrkLnngRmnngRearAxle3RightWheel 1;
BA_ "SPN" SG_ 2633935883 BrkLnngRmningRearAxle3LeftWheel 1105;
BA_ "SigType" SG_ 2633935883 BrkLnngRmningRearAxle3LeftWheel 1;
BA_ "SPN" SG_ 2633935883 BrkLnngRmnngRearAxle2RightWheel 1104;
BA_ "SigType" SG_ 2633935883 BrkLnngRmnngRearAxle2RightWheel 1;
BA_ "SPN" SG_ 2633935883 BrkLnngRmningRearAxle2LeftWheel 1103;
BA_ "SigType" SG_ 2633935883 BrkLnngRmningRearAxle2LeftWheel 1;
BA_ "SPN" SG_ 2633935883 BrkLnngRmnngRearAxle1RightWheel 1102;
BA_ "SigType" SG_ 2633935883 BrkLnngRmnngRearAxle1RightWheel 1;
BA_ "SPN" SG_ 2633935883 BrkLnngRmningRearAxle1LeftWheel 1101;
BA_ "SigType" SG_ 2633935883 BrkLnngRmningRearAxle1LeftWheel 1;
BA_ "SPN" SG_ 2633935883 BrkLnngRmnngFrontAxleRightWheel 1100;
BA_ "SigType" SG_ 2633935883 BrkLnngRmnngFrontAxleRightWheel 1;
BA_ "SPN" SG_ 2633935883 BrkLnngRmningFrontAxleLeftWheel 1099;
BA_ "SigType" SG_ 2633935883 BrkLnngRmningFrontAxleLeftWheel 1;
BA_ "SPN" SG_ 2566827275 BrkAppPrssHghRngRrAxl3RghtWheel 1098;
BA_ "SigType" SG_ 2566827275 BrkAppPrssHghRngRrAxl3RghtWheel 1;
BA_ "SPN" SG_ 2566827275 BrkAppPrssHghRngRrAxl3LeftWheel 1097;
BA_ "SigType" SG_ 2566827275 BrkAppPrssHghRngRrAxl3LeftWheel 1;
BA_ "SPN" SG_ 2566827275 BrkAppPrssHghRngRrAxl2RghtWheel 1096;
BA_ "SigType" SG_ 2566827275 BrkAppPrssHghRngRrAxl2RghtWheel 1;
BA_ "SPN" SG_ 2566827275 BrkAppPrssHghRngRrAxl2LeftWheel 1095;
BA_ "SigType" SG_ 2566827275 BrkAppPrssHghRngRrAxl2LeftWheel 1;
BA_ "SPN" SG_ 2566827275 BrkAppPrssHghRngRrAxl1RghtWheel 1094;
BA_ "SigType" SG_ 2566827275 BrkAppPrssHghRngRrAxl1RghtWheel 1;
BA_ "SPN" SG_ 2566827275 BrkAppPrssHghRngRrAxl1LeftWheel 1093;
BA_ "SigType" SG_ 2566827275 BrkAppPrssHghRngRrAxl1LeftWheel 1;
BA_ "SPN" SG_ 2566827275 BrkAppPrssHghRngFrntAxlRghtWhel 1092;
BA_ "SigType" SG_ 2566827275 BrkAppPrssHghRngFrntAxlRghtWhel 1;
BA_ "SPN" SG_ 2566827275 BrkAppPrssHghRngFrntAxlLftWheel 1091;
BA_ "SigType" SG_ 2566827275 BrkAppPrssHghRngFrntAxlLftWheel 1;
BA_ "SPN" SG_ 2566831883 RlativeSpeedRearAxle2RightWheel 910;
BA_ "SigType" SG_ 2566831883 RlativeSpeedRearAxle2RightWheel 1;
BA_ "SPN" SG_ 2566831883 RelativeSpeedRearAxle2LeftWheel 909;
BA_ "SigType" SG_ 2566831883 RelativeSpeedRearAxle2LeftWheel 1;
BA_ "SPN" SG_ 2566831883 RlativeSpeedRearAxle1RightWheel 908;
BA_ "SigType" SG_ 2566831883 RlativeSpeedRearAxle1RightWheel 1;
BA_ "SPN" SG_ 2566831883 RelativeSpeedRearAxle1LeftWheel 907;
BA_ "SigType" SG_ 2566831883 RelativeSpeedRearAxle1LeftWheel 1;
BA_ "SPN" SG_ 2566831883 RlativeSpeedFrontAxleRightWheel 906;
BA_ "SigType" SG_ 2566831883 RlativeSpeedFrontAxleRightWheel 1;
BA_ "SPN" SG_ 2566831883 RelativeSpeedFrontAxleLeftWheel 905;
BA_ "SigType" SG_ 2566831883 RelativeSpeedFrontAxleLeftWheel 1;
BA_ "SPN" SG_ 2566831883 FrontAxleSpeed 904;
BA_ "SigType" SG_ 2566831883 FrontAxleSpeed 1;
BA_ "GenSigStartValue" SG_ 2565865739 SrcAddrssOfCtrllngDvcFrBrkCntrl 11;
BA_ "SPN" SG_ 2565865739 SrcAddrssOfCtrllngDvcFrBrkCntrl 1481;
BA_ "SigType" SG_ 2565865739 SrcAddrssOfCtrllngDvcFrBrkCntrl 1;
BA_ "SPN" SG_ 2565865739 BrakePedalPos 521;
BA_ "SigType" SG_ 2565865739 BrakePedalPos 1;
BA_ "SPN" SG_ 2565865739 TrctrMntdTrilerABSWarningSignal 1792;
BA_ "SigType" SG_ 2565865739 TrctrMntdTrilerABSWarningSignal 4;
BA_ "SPN" SG_ 2565865739 TrailerABSStatus 1836;
BA_ "SigType" SG_ 2565865739 TrailerABSStatus 4;
BA_ "SPN" SG_ 2565865739 HaltBrakeSwitch 2911;
BA_ "SigType" SG_ 2565865739 HaltBrakeSwitch 4;
BA_ "SPN" SG_ 2565865739 ATC_ASRInformationSignal 1793;
BA_ "SigType" SG_ 2565865739 ATC_ASRInformationSignal 4;
BA_ "SPN" SG_ 2565865739 ABS_EBSAmberWarningSignal 1438;
BA_ "SigType" SG_ 2565865739 ABS_EBSAmberWarningSignal 4;
BA_ "SPN" SG_ 2565865739 EBSRedWarningSignal 1439;
BA_ "SigType" SG_ 2565865739 EBSRedWarningSignal 4;
BA_ "SPN" SG_ 2565865739 ABSFullyOperational 1243;
BA_ "SigType" SG_ 2565865739 ABSFullyOperational 4;
BA_ "SPN" SG_ 2565865739 EngRetarderSelection 973;
BA_ "SigType" SG_ 2565865739 EngRetarderSelection 1;
BA_ "SPN" SG_ 2565865739 RemoteAccelEnableSwitch 969;
BA_ "SigType" SG_ 2565865739 RemoteAccelEnableSwitch 4;
BA_ "SPN" SG_ 2565865739 EngAuxEngShutdownSwitch 970;
BA_ "SigType" SG_ 2565865739 EngAuxEngShutdownSwitch 4;
BA_ "SPN" SG_ 2565865739 EngDerateSwitch 971;
BA_ "SigType" SG_ 2565865739 EngDerateSwitch 4;
BA_ "SPN" SG_ 2565865739 AccelInterlockSwitch 972;
BA_ "SigType" SG_ 2565865739 AccelInterlockSwitch 4;
BA_ "SPN" SG_ 2565865739 TractionCtrlOverrideSwitch 1238;
BA_ "SigType" SG_ 2565865739 TractionCtrlOverrideSwitch 4;
BA_ "SPN" SG_ 2565865739 ASRHillHolderSwitch 577;
BA_ "SigType" SG_ 2565865739 ASRHillHolderSwitch 4;
BA_ "SPN" SG_ 2565865739 ASROffroadSwitch 576;
BA_ "SigType" SG_ 2565865739 ASROffroadSwitch 4;
BA_ "SPN" SG_ 2565865739 ABSOffroadSwitch 575;
BA_ "SigType" SG_ 2565865739 ABSOffroadSwitch 4;
BA_ "SPN" SG_ 2565865739 EBSBrakeSwitch 1121;
BA_ "SigType" SG_ 2565865739 EBSBrakeSwitch 4;
BA_ "SPN" SG_ 2565865739 AntiLockBrakingActive 563;
BA_ "SigType" SG_ 2565865739 AntiLockBrakingActive 4;
BA_ "SPN" SG_ 2565865739 ASRBrakeCtrlActive 562;
BA_ "SigType" SG_ 2565865739 ASRBrakeCtrlActive 4;
BA_ "SPN" SG_ 2565865739 ASREngCtrlActive 561;
BA_ "SigType" SG_ 2565865739 ASREngCtrlActive 4;
BA_ "SigType" SG_ 2566810606 Driver2 8;
BA_ "SPN" SG_ 2566810606 Driver2 1626;
BA_ "SigType" SG_ 2566810606 Driver1 8;
BA_ "SPN" SG_ 2566810606 Driver1 1625;
BA_ "SPN" SG_ 2566847742 CargoAmbientTemp 169;
BA_ "SigType" SG_ 2566847742 CargoAmbientTemp 1;
BA_ "SPN" SG_ 2566847742 EngOilFilterDiffPress 99;
BA_ "SigType" SG_ 2566847742 EngOilFilterDiffPress 1;
BA_ "SPN" SG_ 2566847742 EngFuelFilterDiffPress 95;
BA_ "SigType" SG_ 2566847742 EngFuelFilterDiffPress 1;
BA_ "SPN" SG_ 2566847742 FuelLevel 96;
BA_ "SigType" SG_ 2566847742 FuelLevel 1;
BA_ "SPN" SG_ 2566847742 WasherFluidLevel 80;
BA_ "SigType" SG_ 2566847742 WasherFluidLevel 1;
BA_ "SPN" SG_ 2564816921 SelectedMaxVehicleSpeedLimit 2596;
BA_ "SigType" SG_ 2564816921 SelectedMaxVehicleSpeedLimit 1;
BA_ "SPN" SG_ 2564816921 RqCabZoneHeating 1686;
BA_ "SigType" SG_ 2564816921 RqCabZoneHeating 4;
BA_ "SPN" SG_ 2564816921 RqEngZoneHeating 1685;
BA_ "SigType" SG_ 2564816921 RqEngZoneHeating 4;
BA_ "SPN" SG_ 2564816921 AuxHeaterModeRq 1683;
BA_ "SigType" SG_ 2564816921 AuxHeaterModeRq 4;
BA_ "SPN" SG_ 2564816921 EngAutomaticStartEnableSwitch 1656;
BA_ "SigType" SG_ 2564816921 EngAutomaticStartEnableSwitch 4;
BA_ "SPN" SG_ 2564816921 AtmaticGearShiftingEnableSwitch 1666;
BA_ "SigType" SG_ 2564816921 AtmaticGearShiftingEnableSwitch 4;
BA_ "SPN" SG_ 2564816921 VhclLmtngSpdGvernorEnableSwitch 1653;
BA_ "SigType" SG_ 2564816921 VhclLmtngSpdGvernorEnableSwitch 4;
BA_ "SPN" SG_ 2564816921 VhclLmtngSpdGvrnrIncrmentSwitch 1654;
BA_ "SigType" SG_ 2564816921 VhclLmtngSpdGvrnrIncrmentSwitch 4;
BA_ "SPN" SG_ 2564816921 VhclLmtngSpdGvrnrDcrementSwitch 1655;
BA_ "SigType" SG_ 2564816921 VhclLmtngSpdGvrnrDcrementSwitch 4;
BA_ "SPN" SG_ 2564816921 SeatBeltSwitch 1856;
BA_ "SigType" SG_ 2564816921 SeatBeltSwitch 4;
BA_ "SPN" SG_ 2564816921 OperatorSeatDirectionSwitch 1714;
BA_ "SigType" SG_ 2564816921 OperatorSeatDirectionSwitch 4;
BA_ "SPN" SG_ 2564816921 BatteryMainSwitchHoldRq 1682;
BA_ "SigType" SG_ 2564816921 BatteryMainSwitchHoldRq 4;
BA_ "SPN" SG_ 2564816921 AuxHeaterCoolantPumpRq 1684;
BA_ "SigType" SG_ 2564816921 AuxHeaterCoolantPumpRq 4;
BA_ "SPN" SG_ 2564816921 CabInteriorTempCmd 1691;
BA_ "SigType" SG_ 2564816921 CabInteriorTempCmd 1;
BA_ "SPN" SG_ 2564816921 RqedPercentFanSpeed 986;
BA_ "SigType" SG_ 2564816921 RqedPercentFanSpeed 1;
BA_ "SPN" SG_ 2563833623 IlluminationBrightnessPercent 1487;
BA_ "SigType" SG_ 2563833623 IlluminationBrightnessPercent 1;
BA_ "SPN" SG_ 2566844672 EngShutdownOverrideSwitch 1237;
BA_ "SigType" SG_ 2566844672 EngShutdownOverrideSwitch 4;
BA_ "SPN" SG_ 2566844672 EngTestModeSwitch 966;
BA_ "SigType" SG_ 2566844672 EngTestModeSwitch 4;
BA_ "SPN" SG_ 2566844672 EngIdleDecrementSwitch 967;
BA_ "SigType" SG_ 2566844672 EngIdleDecrementSwitch 4;
BA_ "SPN" SG_ 2566844672 EngIdleIncrementSwitch 968;
BA_ "SigType" SG_ 2566844672 EngIdleIncrementSwitch 4;
BA_ "SPN" SG_ 2566844672 CruiseCtrlStates 527;
BA_ "SigType" SG_ 2566844672 CruiseCtrlStates 4;
BA_ "SPN" SG_ 2566844672 PTOState 976;
BA_ "SigType" SG_ 2566844672 PTOState 4;
BA_ "SPN" SG_ 2566844672 CruiseCtrlSetSpeed 86;
BA_ "SigType" SG_ 2566844672 CruiseCtrlSetSpeed 1;
BA_ "SPN" SG_ 2566844672 CruiseCtrlAccelerateSwitch 602;
BA_ "SigType" SG_ 2566844672 CruiseCtrlAccelerateSwitch 4;
BA_ "SPN" SG_ 2566844672 CruiseCtrlResumeSwitch 601;
BA_ "SigType" SG_ 2566844672 CruiseCtrlResumeSwitch 4;
BA_ "SPN" SG_ 2566844672 CruiseCtrlCoastSwitch 600;
BA_ "SigType" SG_ 2566844672 CruiseCtrlCoastSwitch 4;
BA_ "SPN" SG_ 2566844672 CruiseCtrlSetSwitch 599;
BA_ "SigType" SG_ 2566844672 CruiseCtrlSetSwitch 4;
BA_ "SPN" SG_ 2566844672 ClutchSwitch 598;
BA_ "SigType" SG_ 2566844672 ClutchSwitch 4;
BA_ "SPN" SG_ 2566844672 BrakeSwitch 597;
BA_ "SigType" SG_ 2566844672 BrakeSwitch 4;
BA_ "SPN" SG_ 2566844672 CruiseCtrlEnableSwitch 596;
BA_ "SigType" SG_ 2566844672 CruiseCtrlEnableSwitch 4;
BA_ "SPN" SG_ 2566844672 CruiseCtrlActive 595;
BA_ "SigType" SG_ 2566844672 CruiseCtrlActive 4;
BA_ "SPN" SG_ 2566844672 WheelBasedVehicleSpeed 84;
BA_ "SigType" SG_ 2566844672 WheelBasedVehicleSpeed 1;
BA_ "SPN" SG_ 2566844672 CruiseCtrlPauseSwitch 1633;
BA_ "SigType" SG_ 2566844672 CruiseCtrlPauseSwitch 4;
BA_ "SPN" SG_ 2566844672 ParkingBrakeSwitch 70;
BA_ "SigType" SG_ 2566844672 ParkingBrakeSwitch 4;
BA_ "SPN" SG_ 2566844672 TwoSpeedAxleSwitch 69;
BA_ "SigType" SG_ 2566844672 TwoSpeedAxleSwitch 4;
BA_ "SPN" SG_ 2566775065 CbA_CRfrgrntCmprssorOutletPress 2609;
BA_ "SigType" SG_ 2566775065 CbA_CRfrgrntCmprssorOutletPress 1;
BA_ "SPN" SG_ 2566805807 RelativeLevelRearAxleRight 1723;
BA_ "SigType" SG_ 2566805807 RelativeLevelRearAxleRight 1;
BA_ "SPN" SG_ 2566805807 RelativeLevelRearAxleLeft 1724;
BA_ "SigType" SG_ 2566805807 RelativeLevelRearAxleLeft 1;
BA_ "SPN" SG_ 2566805807 RelativeLevelFrontAxleRight 1722;
BA_ "SigType" SG_ 2566805807 RelativeLevelFrontAxleRight 1;
BA_ "SPN" SG_ 2566805807 RelativeLevelFrontAxleLeft 1721;
BA_ "SigType" SG_ 2566805807 RelativeLevelFrontAxleLeft 1;
BA_ "SPN" SG_ 2365479471 SspensionCtrlRefusalInformation 1827;
BA_ "SigType" SG_ 2365479471 SspensionCtrlRefusalInformation 4;
BA_ "SPN" SG_ 2365479471 SuspensionRemoteCtrl2 1825;
BA_ "SigType" SG_ 2365479471 SuspensionRemoteCtrl2 4;
BA_ "SPN" SG_ 2365479471 SuspensionRemoteCtrl1 1826;
BA_ "SigType" SG_ 2365479471 SuspensionRemoteCtrl1 4;
BA_ "SPN" SG_ 2365479471 RearAxleInBumperRange 1823;
BA_ "SigType" SG_ 2365479471 RearAxleInBumperRange 4;
BA_ "SPN" SG_ 2365479471 FrontAxleInBumperRange 1824;
BA_ "SigType" SG_ 2365479471 FrontAxleInBumperRange 4;
BA_ "SPN" SG_ 2365479471 DoorRelease 1744;
BA_ "SigType" SG_ 2365479471 DoorRelease 4;
BA_ "SPN" SG_ 2365479471 VehicleMotionInhibit 1745;
BA_ "SigType" SG_ 2365479471 VehicleMotionInhibit 4;
BA_ "SPN" SG_ 2365479471 SecurityDevice 1746;
BA_ "SigType" SG_ 2365479471 SecurityDevice 4;
BA_ "SPN" SG_ 2365479471 LevelCtrlMode 1741;
BA_ "SigType" SG_ 2365479471 LevelCtrlMode 4;
BA_ "SPN" SG_ 2365479471 KneelingInformation 1742;
BA_ "SigType" SG_ 2365479471 KneelingInformation 4;
BA_ "SPN" SG_ 2365479471 LiftingCtrlModeRearAxle 1756;
BA_ "SigType" SG_ 2365479471 LiftingCtrlModeRearAxle 4;
BA_ "SPN" SG_ 2365479471 LiftingCtrlModeFrontAxle 1739;
BA_ "SigType" SG_ 2365479471 LiftingCtrlModeFrontAxle 4;
BA_ "SPN" SG_ 2365479471 LoweringCtrlModeRearAxle 1755;
BA_ "SigType" SG_ 2365479471 LoweringCtrlModeRearAxle 4;
BA_ "SPN" SG_ 2365479471 LoweringCtrlModeFrontAxle 1740;
BA_ "SigType" SG_ 2365479471 LoweringCtrlModeFrontAxle 4;
BA_ "SPN" SG_ 2365479471 AboveNominalLevelRearAxle 1736;
BA_ "SigType" SG_ 2365479471 AboveNominalLevelRearAxle 4;
BA_ "SPN" SG_ 2365479471 AboveNominalLevelFrontAxle 1737;
BA_ "SigType" SG_ 2365479471 AboveNominalLevelFrontAxle 4;
BA_ "SPN" SG_ 2365479471 BelowNominalLevelRearAxle 1754;
BA_ "SigType" SG_ 2365479471 BelowNominalLevelRearAxle 4;
BA_ "SPN" SG_ 2365479471 BelowNominalLevelFrontAxle 1738;
BA_ "SigType" SG_ 2365479471 BelowNominalLevelFrontAxle 4;
BA_ "SPN" SG_ 2365479471 NominalLevelRearAxle 1733;
BA_ "SigType" SG_ 2365479471 NominalLevelRearAxle 4;
BA_ "SPN" SG_ 2365479471 NominalLevelFrontAxle 1734;
BA_ "SigType" SG_ 2365479471 NominalLevelFrontAxle 4;
BA_ "SPN" SG_ 2365479471 LiftAxle2Pos 1822;
BA_ "SigType" SG_ 2365479471 LiftAxle2Pos 4;
BA_ "SPN" SG_ 2365479471 LiftAxle1Pos 1743;
BA_ "SigType" SG_ 2365479471 LiftAxle1Pos 4;
BA_ "SigType" SG_ 2566836222 DTC5 7;
BA_ "SigType" SG_ 2566836222 DTC4 7;
BA_ "SigType" SG_ 2566836222 DTC3 7;
BA_ "SigType" SG_ 2566836222 DTC2 7;
BA_ "SigType" SG_ 2566836222 DTC1 7;
BA_ "SPN" SG_ 2566836222 FlashRedStopLamp 3039;
BA_ "SPN" SG_ 2566836222 FlashProtectLamp 3041;
BA_ "SPN" SG_ 2566836222 FlashMalfuncIndicatorLamp 3038;
BA_ "SigType" SG_ 2566836222 FlashMalfuncIndicatorLamp 4;
BA_ "SPN" SG_ 2566836222 MalfunctionIndicatorLampStatus 1213;
BA_ "SigType" SG_ 2566836222 MalfunctionIndicatorLampStatus 4;
BA_ "SPN" SG_ 2566836222 RedStopLampState 623;
BA_ "SigType" SG_ 2566836222 RedStopLampState 4;
BA_ "SPN" SG_ 2566836222 AmberWarningLampStatus 624;
BA_ "SigType" SG_ 2566836222 AmberWarningLampStatus 4;
BA_ "SPN" SG_ 2566836222 ProtectLampStatus 987;
BA_ "SigType" SG_ 2566836222 ProtectLampStatus 4;
BA_ "SPN" SG_ 2566835966 MisfireMonitoringSupport 1221;
BA_ "SPN" SG_ 2566835966 OBDCompliance 1220;
BA_ "SigType" SG_ 2566835966 OBDCompliance 1;
BA_ "SPN" SG_ 2566835966 PreviouslyActiveTroubleCodes 1219;
BA_ "SigType" SG_ 2566835966 PreviouslyActiveTroubleCodes 1;
BA_ "SPN" SG_ 2566835966 ActiveTroubleCodes 1218;
BA_ "SigType" SG_ 2566835966 ActiveTroubleCodes 1;
BA_ "SPN" SG_ 2566835966 SecondAirSystemMonStatus 1223;
BA_ "SPN" SG_ 2566835966 EvaporativeSystemMonStatus 1223;
BA_ "SPN" SG_ 2566835966 ACSystemRefrigerantMonStatus 1223;
BA_ "SPN" SG_ 2566835966 OxygenSensorHeaterMonStatus 1223;
BA_ "SPN" SG_ 2566835966 OxygenSensorMonStatus 1223;
BA_ "SPN" SG_ 2566835966 EGRSystemMonitoringStatus 1223;
BA_ "SPN" SG_ 2566835966 CatalystMonStatus 1223;
BA_ "SPN" SG_ 2566835966 ColdStartAidSystemMonStatus 1223;
BA_ "SPN" SG_ 2566835966 HeatedCatalystMonStatus 1223;
BA_ "SPN" SG_ 2566835966 CatalystMonSupp 1222;
BA_ "SPN" SG_ 2566835966 ColdStartAidSystemMonSupp 1222;
BA_ "SPN" SG_ 2566835966 HeatedCatalystMonSupp 1222;
BA_ "SPN" SG_ 2566835966 EvaporativeSystemMonSupp 1222;
BA_ "SPN" SG_ 2566835966 SecondAirSystemMonSupp 1222;
BA_ "SPN" SG_ 2566835966 ACSystemRefrigerantMonSupp 1222;
BA_ "SPN" SG_ 2566835966 OxygenSensorMonSupp 1222;
BA_ "SPN" SG_ 2566835966 OxygenSensorHeaterMonSupp 1222;
BA_ "SPN" SG_ 2566835966 EGRSystemMonitoringSupp 1222;
BA_ "SPN" SG_ 2566835966 MisfireMonitoringStatus 1221;
BA_ "SPN" SG_ 2566835966 ComprehensiveCompMonStatus 1221;
BA_ "SPN" SG_ 2566835966 FuelSystemMonitoringStatus 1221;
BA_ "SPN" SG_ 2566835966 ComprehensiveComponentMonSupp 1221;
BA_ "SPN" SG_ 2566835966 FuelSystemMonitoringSupport 1221;
BA_ "SigType" SG_ 2566835710 DTC1 7;
BA_ "SPN" SG_ 2566835710 FreezeFrameLength 1217;
BA_ "SPN" SG_ 2566835710 EngSpeed 190;
BA_ "SigType" SG_ 2566835710 EngSpeed 1;
BA_ "SPN" SG_ 2566835710 EngTorqueMode 899;
BA_ "SigType" SG_ 2566835710 EngTorqueMode 4;
BA_ "SPN" SG_ 2566835710 EngTurboBoostPress 102;
BA_ "SigType" SG_ 2566835710 EngTurboBoostPress 1;
BA_ "SPN" SG_ 2566835710 WheelBasedVehicleSpeed 84;
BA_ "SigType" SG_ 2566835710 WheelBasedVehicleSpeed 1;
BA_ "SPN" SG_ 2566835710 EngPercentLoadAtCurrentSpeed 92;
BA_ "SigType" SG_ 2566835710 EngPercentLoadAtCurrentSpeed 1;
BA_ "SPN" SG_ 2566835710 EngineCoolantTemperature 110;
BA_ "SigType" SG_ 2566835710 EngineCoolantTemperature 1;
BA_ "SigType" SG_ 2566764542 DTC1 7;
BA_ "SPN" SG_ 2566764542 ExpandedFreezeFrameLength 3149;
BA_ "SPN" SG_ 2566764286 SPNSupported1High 3146;
BA_ "SPN" SG_ 2566764286 SPNSupported3High 3146;
BA_ "SPN" SG_ 2566764286 SPNSupported2High 3146;
BA_ "SPN" SG_ 2566764286 SPNSupported3 3146;
BA_ "SPN" SG_ 2566764286 SPNSupported2 3146;
BA_ "SPN" SG_ 2566764286 SPNDataLength3 3148;
BA_ "SPN" SG_ 2566764286 SPNDataLength2 3148;
BA_ "SPN" SG_ 2566764286 SPNDataLength1 3148;
BA_ "SPN" SG_ 2566764286 SPNSupported1 3146;
BA_ "SigType" SG_ 2566835198 DTC5 7;
BA_ "SigType" SG_ 2566835198 DTC4 7;
BA_ "SigType" SG_ 2566835198 DTC3 7;
BA_ "SigType" SG_ 2566835198 DTC2 7;
BA_ "SigType" SG_ 2566835198 DTC1 7;
BA_ "SPN" SG_ 2566835198 MalfunctionIndicatorLampStatus 1213;
BA_ "SigType" SG_ 2566835198 MalfunctionIndicatorLampStatus 4;
BA_ "SPN" SG_ 2566835198 RedStopLampState 623;
BA_ "SigType" SG_ 2566835198 RedStopLampState 4;
BA_ "SPN" SG_ 2566835198 AmberWarningLampStatus 624;
BA_ "SigType" SG_ 2566835198 AmberWarningLampStatus 4;
BA_ "SPN" SG_ 2566835198 ProtectLampStatus 987;
BA_ "SigType" SG_ 2566835198 ProtectLampStatus 4;
BA_ "SPN" SG_ 2566835198 FlashRedStopLamp 3039;
BA_ "SPN" SG_ 2566835198 FlashProtectLamp 3041;
BA_ "SPN" SG_ 2566835198 FlashMalfuncIndicatorLamp 3038;
BA_ "SigType" SG_ 2566835198 FlashMalfuncIndicatorLamp 4;
BA_ "SPN" SG_ 2566835198 FlashAmberWarningLamp 3040;
BA_ "SPN" SG_ 2564030206 CalibrationID4 1635;
BA_ "SPN" SG_ 2564030206 CalibrationID3 1635;
BA_ "SPN" SG_ 2564030206 CalibrationID2 1635;
BA_ "SPN" SG_ 2564030206 CalibrationID1 1635;
BA_ "SPN" SG_ 2564030206 CalibrationVerificationNumber 1634;
BA_ "SigType" SG_ 2564030206 CalibrationVerificationNumber 1;
BA_ "SigType" SG_ 2566837502 DTC5 7;
BA_ "SigType" SG_ 2566837502 DTC4 7;
BA_ "SigType" SG_ 2566837502 DTC3 7;
BA_ "SigType" SG_ 2566837502 DTC2 7;
BA_ "SPN" SG_ 2566837502 FlashRedStopLamp 3039;
BA_ "SPN" SG_ 2566837502 FlashProtectLamp 3041;
BA_ "SPN" SG_ 2566837502 MalfunctionIndicatorLampStatus 1213;
BA_ "SigType" SG_ 2566837502 MalfunctionIndicatorLampStatus 4;
BA_ "SPN" SG_ 2566837502 RedStopLampState 623;
BA_ "SigType" SG_ 2566837502 RedStopLampState 4;
BA_ "SPN" SG_ 2566837502 AmberWarningLampStatus 624;
BA_ "SigType" SG_ 2566837502 AmberWarningLampStatus 4;
BA_ "SPN" SG_ 2566837502 ProtectLampStatus 987;
BA_ "SigType" SG_ 2566837502 ProtectLampStatus 4;
BA_ "SPN" SG_ 2566837502 FlashMalfuncIndicatorLamp 3038;
BA_ "SigType" SG_ 2566837502 FlashMalfuncIndicatorLamp 4;
BA_ "SPN" SG_ 2566837502 FlashAmberWarningLamp 3040;
BA_ "SPN" SG_ 2566837502 SPN1 1214;
BA_ "SigType" SG_ 2566834942 DTC5 7;
BA_ "SigType" SG_ 2566834942 DTC4 7;
BA_ "SigType" SG_ 2566834942 DTC3 7;
BA_ "SigType" SG_ 2566834942 DTC2 7;
BA_ "SigType" SG_ 2566834942 DTC1 7;
BA_ "SPN" SG_ 2566834942 FlashRedStopLamp 3039;
BA_ "SPN" SG_ 2566834942 FlashProtectLamp 3041;
BA_ "SPN" SG_ 2566834942 FlashMalfuncIndicatorLamp 3038;
BA_ "SigType" SG_ 2566834942 FlashMalfuncIndicatorLamp 4;
BA_ "SPN" SG_ 2566834942 FlashAmberWarningLamp 3040;
BA_ "SPN" SG_ 2566834942 MalfunctionIndicatorLampStatus 1213;
BA_ "SigType" SG_ 2566834942 MalfunctionIndicatorLampStatus 4;
BA_ "SPN" SG_ 2566834942 AmberWarningLampStatus 624;
BA_ "SigType" SG_ 2566834942 AmberWarningLampStatus 4;
BA_ "SPN" SG_ 2566834942 RedStopLampState 623;
BA_ "SigType" SG_ 2566834942 RedStopLampState 4;
BA_ "SPN" SG_ 2566834942 ProtectLampStatus 987;
BA_ "SigType" SG_ 2566834942 ProtectLampStatus 4;
BA_ "SigType" SG_ 2565799678 IndustryGroup 4;
BA_ "SigType" SG_ 2565799678 ManufacturerCode 1;
BA_ "SPN" SG_ 2563440382 ShrtNameOfActualReportingDevice 2554;
BA_ "SigType" SG_ 2563440382 ShrtNameOfActualReportingDevice 4;
BA_ "SPN" SG_ 2563440382 LengthOfDataForTheReportedPGN 2553;
BA_ "SigType" SG_ 2563440382 LengthOfDataForTheReportedPGN 1;
BA_ "SPN" SG_ 2563440382 PGNofRequstedInformation 2552;
BA_ "SigType" SG_ 2563440382 PGNofRequstedInformation 6;
BA_ "SPN" SG_ 2565603070 SequenceNumber 2572;
BA_ "SigType" SG_ 2565603070 SequenceNumber 1;
BA_ "SPN" SG_ 2565668606 TotalNumberOfPacketsEoMA 2558;
BA_ "SigType" SG_ 2565668606 TotalNumberOfPacketsEoMA 1;
BA_ "SPN" SG_ 2565668606 TotalMessageSizeEoMA 2557;
BA_ "SigType" SG_ 2565668606 TotalMessageSizeEoMA 1;
BA_ "SPN" SG_ 2565668606 TotalMessageSizeBAM 2557;
BA_ "SigType" SG_ 2565668606 TotalMessageSizeBAM 1;
BA_ "SPN" SG_ 2565668606 TotalNumberOfPacketsBAM 2558;
BA_ "SigType" SG_ 2565668606 TotalNumberOfPacketsBAM 1;
BA_ "SPN" SG_ 2565668606 ConnectionAbortReason 2570;
BA_ "SigType" SG_ 2565668606 ConnectionAbortReason 1;
BA_ "SPN" SG_ 2565668606 NextPacketNumberToBeSent 2562;
BA_ "SigType" SG_ 2565668606 NextPacketNumberToBeSent 1;
BA_ "SPN" SG_ 2565668606 NumberOfPacketsThatCanBeSent 2561;
BA_ "SigType" SG_ 2565668606 NumberOfPacketsThatCanBeSent 1;
BA_ "SigType" SG_ 2565668606 PGNumber 6;
BA_ "SPN" SG_ 2565668606 PGNumber 2560;
BA_ "SPN" SG_ 2565668606 MaximumNumberOfPackets 2559;
BA_ "SigType" SG_ 2565668606 MaximumNumberOfPackets 1;
BA_ "SPN" SG_ 2565668606 TotalNumberOfPackets 2558;
BA_ "SigType" SG_ 2565668606 TotalNumberOfPackets 1;
BA_ "SPN" SG_ 2565668606 TotalMessageSize 2557;
BA_ "SigType" SG_ 2565668606 TotalMessageSize 1;
BA_ "SPN" SG_ 2565668606 ControlByte 2556;
BA_ "SPN" SG_ 2563374846 UseTransferMode 2575;
BA_ "SigType" SG_ 2563374846 UseTransferMode 4;
BA_ "SPN" SG_ 2563374846 ParameterGroupNumber 2574;
BA_ "SigType" SG_ 2563374846 ParameterGroupNumber 6;
BA_ "SPN" SG_ 2565537534 ParameterGroupNumber 2574;
BA_ "SigType" SG_ 2565537534 ParameterGroupNumber 6;
BA_ "SPN" SG_ 2566845696 RoadSurfaceTemp 79;
BA_ "SigType" SG_ 2566845696 RoadSurfaceTemp 1;
BA_ "SPN" SG_ 2566845696 EngAirInletTemp 172;
BA_ "SigType" SG_ 2566845696 EngAirInletTemp 1;
BA_ "SPN" SG_ 2566845696 AmbientAirTemp 171;
BA_ "SigType" SG_ 2566845696 AmbientAirTemp 1;
BA_ "SPN" SG_ 2566845696 CabInteriorTemp 170;
BA_ "SigType" SG_ 2566845696 CabInteriorTemp 1;
BA_ "SPN" SG_ 2566845696 BarometricPress 108;
BA_ "SigType" SG_ 2566845696 BarometricPress 1;
BA_ "SPN" SG_ 2565406462 ParameterGroupNumber 2574;
BA_ "SigType" SG_ 2565406462 ParameterGroupNumber 6;
BA_ "SPN" SG_ 2565406462 GroupFunctionValue 2542;
BA_ "SigType" SG_ 2565406462 GroupFunctionValue 1;
BA_ "SPN" SG_ 2565406462 ControlByte 2556;
BA_ "SPN" SG_ 2566846467 TransOilLevelMeasurementStatus 3026;
BA_ "SigType" SG_ 2566846467 TransOilLevelMeasurementStatus 4;
BA_ "SPN" SG_ 2566846467 TransOilLevelCountdownTimer 3028;
BA_ "SigType" SG_ 2566846467 TransOilLevelCountdownTimer 4;
BA_ "SPN" SG_ 2566846467 TransOilLevelHigh_Low 3027;
BA_ "SigType" SG_ 2566846467 TransOilLevelHigh_Low 1;
BA_ "SPN" SG_ 2566846467 TransOilTemp 177;
BA_ "SigType" SG_ 2566846467 TransOilTemp 1;
BA_ "SPN" SG_ 2566846467 TransOilPress 127;
BA_ "SigType" SG_ 2566846467 TransOilPress 1;
BA_ "SPN" SG_ 2566846467 TransFilterDiffPress 126;
BA_ "SigType" SG_ 2566846467 TransFilterDiffPress 1;
BA_ "SPN" SG_ 2566846467 TransOilLevel 124;
BA_ "SigType" SG_ 2566846467 TransOilLevel 1;
BA_ "SPN" SG_ 2566846467 ClutchPress 123;
BA_ "SigType" SG_ 2566846467 ClutchPress 1;
BA_ "SPN" SG_ 2566846451 BatteryPotentialSwitched 158;
BA_ "GenSigILSupport" SG_ 2566846451 BatteryPotentialSwitched 1;
BA_ "SigType" SG_ 2566846451 BatteryPotentialSwitched 1;
BA_ "SPN" SG_ 2566846451 ElectricalPotential 168;
BA_ "SigType" SG_ 2566846451 ElectricalPotential 1;
BA_ "SPN" SG_ 2566846451 ChargingSystemPotential 167;
BA_ "GenSigILSupport" SG_ 2566846451 ChargingSystemPotential 1;
BA_ "SigType" SG_ 2566846451 ChargingSystemPotential 1;
BA_ "SPN" SG_ 2566846451 AltCurrent 115;
BA_ "SigType" SG_ 2566846451 AltCurrent 1;
BA_ "SPN" SG_ 2566846451 NetBatteryCurrent 114;
BA_ "SigType" SG_ 2566846451 NetBatteryCurrent 1;
VAL_ 2566801923 TransMode1Indicator 3 "NotAvailable" 2 "Error" 1 "TransMode1Active" 0 "TransMode1NotActive" ;
VAL_ 2566801923 TransMode2Indicator 3 "NotAvailable" 2 "Error" 1 "TransMode2Active" 0 "TransMode2NotActive" ;
VAL_ 2566801923 TransMode3Indicator 3 "NotAvailable" 2 "Error" 1 "TransMode3Active" 0 "TransMode3NotActive" ;
VAL_ 2566801923 TransMode4Indicator 3 "NotAvailable" 2 "Error" 1 "TransMode4Active" 0 "TransMode4NotActive" ;
VAL_ 2566801923 TransShiftInhibitIndicator 3 "TakeNoAction" 2 "Reserved" 1 "ActiveShiftIsInhibited" 0 "InactiveShiftIsNotInhibited" ;
VAL_ 2566801923 TransEngCrankEnable 3 "NotAvailable" 2 "Error" 1 "CrnkngEnbldEngCrnkngIsAllwdByTr" 0 "CrnkngDsbldEngCrnkngIsPrhbtdByT" ;
VAL_ 2566801923 ActiveShiftConsoleIndicator 3 "NotAvailable" 2 "Reserved" 1 "SecondShiftConsoleIsActive" 0 "PrimaryShiftConsoleIsActive" ;
VAL_ 2566801923 TransReadyForBrakeRelease 3 "DontCare" 2 "Reserved" 1 "TransReadyForBrakeRelease" 0 "TransNotReadyForBrakeRelease" ;
VAL_ 2566801923 TransRqedRangeDisplayFlashState 3 "TakeNoAction" 2 "Reserved" 1 "ActvTrnsRqdRngDsplyShldBFlshing" 0 "InctvTrnsRqdRngDsplyShldNtBFlsh" ;
VAL_ 2566801923 TransRqedRangeDisplayBlankState 3 "TakeNoAction" 2 "Reserved" 1 "ActvTrnsRqdRngDsplyShldBBlanked" 0 "InctvTrnsRqdRngDsplyShldNtBBlnk" ;
VAL_ 2364539395 ProgressiveShiftDisable 2 "Reserved" 3 "TakeNoAction" 1 "ProgressiveShiftIsDisabled" 0 "ProgressiveShiftIsNotDisabled" ;
VAL_ 2364539395 EngMomentaryOverspeedEnable 2 "Reserved" 3 "TakeNoAction" 1 "MomentaryEngOverspeedIsEnabled" 0 "MomentaryEngOverspeedIsDisabled" ;
VAL_ 2364539395 TransShiftInProcess 3 "NotAvailable" 2 "Error" 1 "ShiftInProcess" 0 "ShiftIsNotInProcess" ;
VAL_ 2364539395 TorqueConverterLockupEngaged 3 "NotAvailable" 2 "Error" 1 "TorqueConverterLockupEngaged" 0 "TorqueConverterLockupDisengaged" ;
VAL_ 2364539395 TransDrivelineEngaged 3 "NotAvailable" 2 "Error" 1 "DrivelineEngaged" 0 "DrivelineDisengaged" ;
VAL_ 2565865513 EngCoolantLoadIncrease 3 "NotAvailable" 2 "Error" 1 "CoolantLoadIncreasePossible" 0 "NoCoolantLoadIncrease" ;
VAL_ 2565865513 RetarderEnableShiftAssistSwitch 3 "NotAvailable" 2 "Error" 1 "RetarderShiftAssistEnabled" 0 "RetarderShiftAssistDisabled" ;
VAL_ 2565865513 RetarderEnableBrakeAssistSwitch 3 "NotAvailable" 2 "Error" 1 "RetarderBrakeAssistEnabled" 0 "RetarderBrakeAssistDisabled" ;
VAL_ 2633935104 EngExhstGsOxygnSnsrClsdLpOprton 3 "DontCare_TakeNoAction" 2 "Reserved" 1 "CmdToEnableFunction" 0 "CmdToDisableFunction" ;
VAL_ 2364539648 VhclAccelerationRateLimitStatus 3 "NotAvailable" 2 "Reserved" 1 "LimitActive" 0 "LimitNotActive" ;
VAL_ 2364539648 AccelPedal2LowIdleSwitch 3 "NotAvailable" 2 "Error" 1 "AccelPedal2InLowIdleCondition" 0 "AcclPedal2NotInLowIdleCondition" ;
VAL_ 2364539648 RoadSpeedLimitStatus 3 "NotAvailable" 2 "Error" 1 "NotActive" 0 "Active" ;
VAL_ 2364539648 AccelPedalKickdownSwitch 3 "NotAvailable" 2 "Error" 1 "KickdownActive" 0 "KickdownPassive" ;
VAL_ 2364539648 AccelPedal1LowIdleSwitch 3 "NotAvailable" 2 "Error" 1 "AccelPedal1InLowIdleCondition" 0 "AcclPedal1NotInLowIdleCondition" ;
VAL_ 2364539904 EngStarterMode 15 "notAvailable" 14 "error" 12 "starterInhibitedReasonUnknown" 9 "1011Reserved" 8 "strtrInhbtdDueToStarterOvertemp" 7 "strtrInhbtdDToActiveImmobilizer" 6 "strtrInhbtdDTDrvlnEnggdOthrTrns" 5 "strtrInhbtdDTEngNtReadyForStart" 4 "strtrInhbtdDToEngAlreadyRunning" 3 "strtFnshdStrtrNtActvAftrHvngBnA" 2 "starterActiveGearEngaged" 1 "starterActiveGearNotEngaged" 0 "startNotRqed" ;
VAL_ 2364539904 EngTorqueMode 15 "Not available" 11 "Remote accelerator" 10 "Braking system" 9 "High speed governor" 8 "Torque limiting" 7 "ABS control" 6 "Transmission control" 5 "ASR control" 4 "Road speed governor" 3 "PTO governor" 2 "Cruise control" 1 "Accelerator pedal/operator selec" 0 "Low idle governor/no request (de" ;
VAL_ 2566841088 SupportTSC1CtrlPurposeGroup4Of4 1 "P25ReservedForAssignmentBySAE" ;
VAL_ 2566841088 SupportVariableRateTSC1Message 1 "MsTransRate" ;
VAL_ 2566841088 SupportTSC1CtrlPurposeGroup3Of4 1 "P17ReservedForAssignmentBySAE" ;
VAL_ 2566841088 SupportTSC1CtrlPurposeGroup2Of4 1 "P9ReservedForAssignmentBySAE" ;
VAL_ 2566841088 SupportTSC1CtrlPurposeGroup1Of4 1 "P1AccelPedal_OperatorSelection" ;
VAL_ 2566767627 XBRActiveCtrlMode 15 "NotAvailable" 4 "1110ReservedForSAEAssignment" 3 "MxMdOfXBRAcclrtnCtrlBngExecuted" 2 "AddtnMdOfXBRAcclrtnCtrlBngExctd" 1 "DrvrsBrkDmndBngExctdNExtlBrkDmn" 0 "NoBrakeDemandBeingExecuted" ;
VAL_ 2566767627 XBRSystemState 3 "NotAvailable" 2 "NoExtlBrakeDemandWillBeAccepted" 1 "OnlyExtlBrkDmndOfHghstXBRPrrtyW" 0 "AnyExtlBrkeDemandWillBeAccepted" ;
VAL_ 2566767627 FoundationBrakeUse 3 "NotAvailable" 2 "Reserved" 1 "FoundationBrakesInUse" 0 "FoundationBrakesNotInUse" ;
VAL_ 2566767627 HillHolderMode 7 "NotAvailable" 6 "Reserved" 3 "101NotDefined" 2 "ActvBtWllChngTInctvInAShortTime" 1 "Active" 0 "Inactive" ;
VAL_ 2566767627 HaltBrakeMode 7 "NotAvailable" 6 "Reserved" 3 "101NotDefined" 2 "ActiveButNotFunctioningProperly" 1 "Active" 0 "Inactive" ;
VAL_ 2565865739 TrctrMntdTrilerABSWarningSignal 3 "TakeNoAction" 2 "Reserved" 1 "On" 0 "Off" ;
VAL_ 2565865739 TrailerABSStatus 3 "TrlrABSSttsInfrmtnNtAvlblPrmtrN" 2 "Reserved" 1 "TrailerABSActive" 0 "TrlrABSSttsInfrmtnAvlblBtNtActv" ;
VAL_ 2565865739 HaltBrakeSwitch 3 "NotAvailable" 2 "Error" 1 "HaltBrakeSwitchActive" 0 "HaltBrakeSwitchPassive" ;
VAL_ 2565865739 ATC_ASRInformationSignal 3 "TakeNoAction" 2 "Reserved" 1 "On" 0 "Off" ;
VAL_ 2565865739 ABS_EBSAmberWarningSignal 3 "TakeNoAction" 2 "Reserved" 1 "On" 0 "Off" ;
VAL_ 2565865739 EBSRedWarningSignal 3 "TakeNoAction" 2 "Reserved" 1 "On" 0 "Off" ;
VAL_ 2565865739 ABSFullyOperational 3 "NotAvailable" 2 "Reserved" 1 "FullyOperational" 0 "NotFullyOperational" ;
VAL_ 2565865739 RemoteAccelEnableSwitch 3 "NotAvailable" 2 "Error" 1 "On" 0 "Off" ;
VAL_ 2565865739 EngAuxEngShutdownSwitch 3 "NotAvailable" 2 "Error" 1 "On" 0 "Off" ;
VAL_ 2565865739 EngDerateSwitch 3 "NotAvailable" 2 "Error" 1 "On" 0 "Off" ;
VAL_ 2565865739 AccelInterlockSwitch 3 "NotAvailable" 2 "Error" 1 "On" 0 "Off" ;
VAL_ 2565865739 TractionCtrlOverrideSwitch 3 "NotAvailableNotInstalled" 2 "Error" 1 "On" 0 "Off" ;
VAL_ 2565865739 ASRHillHolderSwitch 3 "NotAvailable" 2 "Error" 1 "ASRHillHolderSwitchActive" 0 "ASRHillHolderSwitchPassive" ;
VAL_ 2565865739 ASROffroadSwitch 2 "Error" 1 "ASROffroadSwitchActive" 0 "ASROffroadSwitchPassive" 3 "NotAvailable" ;
VAL_ 2565865739 ABSOffroadSwitch 3 "NotAvailable" 2 "Error" 1 "ABSOffroadSwitchActive" 0 "ABSOffroadSwitchPassive" ;
VAL_ 2565865739 EBSBrakeSwitch 3 "NotAvailable" 2 "Error" 1 "BrakePedalIsBeingPressed" 0 "BrakePedalIsNotBeingPressed" ;
VAL_ 2565865739 AntiLockBrakingActive 3 "NotAvailable" 2 "Reserved" 1 "ABSActive" 0 "ABSPassiveButInstalled" ;
VAL_ 2565865739 ASRBrakeCtrlActive 3 "NotAvailable" 2 "Reserved" 1 "ASRBrakeCtrlActive" 0 "ASRBrakeCtrlPassiveButInstalled" ;
VAL_ 2565865739 ASREngCtrlActive 3 "NotAvailable" 2 "Reserved" 1 "ASREngCtrlActive" 0 "ASREngCtrlPassiveButInstalled" ;
VAL_ 2564816921 RqCabZoneHeating 3 "DontCare_TakeNoAction" 2 "Reserved" 1 "HeatCabZone" 0 "DoNotCabEngZone" ;
VAL_ 2564816921 RqEngZoneHeating 3 "DontCare_TakeNoAction" 2 "Reserved" 1 "HeatEngZone" 0 "DoNotHeatEngZone" ;
VAL_ 2564816921 AuxHeaterModeRq 15 "DontCare_TakeNoAction" 14 "Reserved" 4 "1101NotDefined" 3 "NormalMode" 2 "EconomyMode" 1 "OffDTADRPrErpnRgltnsFrTrnsprtOf" 0 "DeactivateAuxHeater" ;
VAL_ 2564816921 SeatBeltSwitch 3 "NotAvailable" 2 "ErrrSwtchStteCannotBeDetermined" 1 "OKSeatBeltIsBuckled" 0 "NOTBuckled" ;
VAL_ 2564816921 OperatorSeatDirectionSwitch 3 "NotAvailable" 2 "Error" 1 "OperatorSeatIsFacingForward" 0 "OperatorSeatNotFacingForward" ;
VAL_ 2564816921 BatteryMainSwitchHoldRq 3 "DontCare_TakeNoAction" 2 "undefined" 1 "HoldBatteryMainSwitch" 0 "ReleaseBatteryMainSwitch" ;
VAL_ 2564816921 AuxHeaterCoolantPumpRq 3 "DontCare_TakeNoAction" 2 "Reserved" 1 "ActivateWaterPump" 0 "DeactivateWaterPump" ;
VAL_ 2566844672 EngShutdownOverrideSwitch 3 "NotAvailable" 2 "Error" 1 "On" 0 "Off" ;
VAL_ 2566844672 EngTestModeSwitch 3 "NotAvailable" 2 "Error" 1 "On" 0 "Off" ;
VAL_ 2566844672 EngIdleDecrementSwitch 3 "NotAvailable" 2 "Error" 1 "On" 0 "Off" ;
VAL_ 2566844672 EngIdleIncrementSwitch 3 "NotAvailable" 2 "Error" 1 "On" 0 "Off" ;
VAL_ 2566844672 CruiseCtrlAccelerateSwitch 3 "NotAvailable" 2 "Error" 1 "CrsCtrlActivatorInPosAccelerate" 0 "CrsCtrlActvtrNotInPosAccelerate" ;
VAL_ 2566844672 CruiseCtrlResumeSwitch 3 "NotAvailable" 2 "Error" 1 "CruiseCtrlActivatorInPosResume" 0 "CrseCtrlActivatorNotInPosResume" ;
VAL_ 2566844672 CruiseCtrlCoastSwitch 3 "NotAvailable" 2 "Error" 1 "CruiseCtrlActivatorInPosCoast" 0 "CriseCtrlActivatorNotInPosCoast" ;
VAL_ 2566844672 CruiseCtrlSetSwitch 3 "NotAvailable" 2 "Error" 1 "CruiseCtrlActivatorInPosSet" 0 "CruiseCtrlActivatorNotInPosSet" ;
VAL_ 2566844672 ClutchSwitch 3 "NotAvailable" 2 "Error" 1 "ClutchPedalDepressed" 0 "ClutchPedalReleased" ;
VAL_ 2566844672 BrakeSwitch 3 "NotAvailable" 2 "Error" 1 "BrakePedalDepressed" 0 "BrakePedalReleased" ;
VAL_ 2566844672 CruiseCtrlEnableSwitch 3 "NotAvailable" 2 "Error" 1 "CruiseCtrlEnabled" 0 "CruiseCtrlDisabled" ;
VAL_ 2566844672 CruiseCtrlActive 3 "NotAvailable" 2 "Error" 1 "CruiseCtrlSwitchedOn" 0 "CruiseCtrlSwitchedOff" ;
VAL_ 2566844672 CruiseCtrlPauseSwitch 3 "TakeNoAction" 2 "ErrorIndicator" 1 "On" 0 "Off" ;
VAL_ 2566844672 ParkingBrakeSwitch 3 "NotAvailable" 2 "Error" 1 "ParkingBrakeSet" 0 "ParkingBrakeNotSet" ;
VAL_ 2566844672 TwoSpeedAxleSwitch 3 "NotAvailable" 2 "Error" 1 "HighSpeedRange" 0 "LowSpeedRange" ;
VAL_ 2365479471 SspensionCtrlRefusalInformation 7 "1101NotDefined" 15 "NotAvailable" 14 "Error" 6 "GnrlRjctINSpcifiedReasonApplies" 5 "BelowSpeedLimit" 4 "AboveSpeedLimit" 3 "BogieDiffNotLocked" 2 "WouldExceedAxleLoadLimit" 1 "AxleLoadLimitReached" 0 "ActualRqNotRefused" ;
VAL_ 2365479471 SuspensionRemoteCtrl2 3 "NotAvailable" 2 "Error" 1 "Active" 0 "NotActive" ;
VAL_ 2365479471 SuspensionRemoteCtrl1 3 "NotAvailable" 2 "Error" 1 "Active" 0 "NotActive" ;
VAL_ 2365479471 RearAxleInBumperRange 3 "NotAvailable" 2 "Error" 1 "ActualLevelWithinBumperRange" 0 "ActualLevelOutOfBumperRange" ;
VAL_ 2365479471 FrontAxleInBumperRange 3 "NotAvailable" 2 "Error" 1 "ActualLevelWithinBumperRange" 0 "ActualLevelOutOfBumperRange" ;
VAL_ 2365479471 DoorRelease 3 "NotAvailable" 2 "Error" 1 "DoorsMayBeOpened" 0 "DoorsMayNotBeOpened" ;
VAL_ 2365479471 VehicleMotionInhibit 3 "NotAvailable" 2 "Error" 1 "VehicleMotionIsInhibited" 0 "VehicleMayBeMoved" ;
VAL_ 2365479471 SecurityDevice 3 "NotAvailable" 2 "Error" 1 "Active" 0 "NotActive" ;
VAL_ 2365479471 LevelCtrlMode 10 "1101NotDefined" 15 "NotAvailable" 14 "Error" 9 "AirSuspensionCtrlProhibited" 8 "ExhstngBllwFnctnIBllwsArExhstdT" 7 "TractionHelpLoadReduce" 6 "OptmmTrctn2IPrssAtThDrvnAxlIsCt" 5 "OptmmTrctn1IPrssAtThDrvnAxlIsCt" 4 "PrssRt2IRtBtwnThPrssrsAtThDrvnA" 3 "PrssRt1IRtBtwnThPrssrsAtThDrvnA" 2 "LdFxngIDrvnAxlnIsLddTAVlDfndByT" 1 "TrctnHlpIDrvnAxlIsLddTAMxVlGvnB" 0 "NrmlOprtnISystmPrfrmsAPrCtrlOfT" ;
VAL_ 2365479471 KneelingInformation 15 "NotAvailable" 14 "Error" 5 "1101NotDefined" 4 "KneelingAborted" 3 "LiftingActive" 2 "KneelingLevelReached" 0 "NotActive" ;
VAL_ 2365479471 LiftingCtrlModeRearAxle 3 "NotAvailable" 2 "Error" 1 "LiftingActive" 0 "LiftingNotActive" ;
VAL_ 2365479471 LiftingCtrlModeFrontAxle 3 "NotAvailable" 2 "Error" 1 "LiftingActive" 0 "LiftingNotActive" ;
VAL_ 2365479471 LoweringCtrlModeRearAxle 3 "NotAvailable" 2 "Error" 1 "LoweringActive" 0 "LoweringNotActive" ;
VAL_ 2365479471 LoweringCtrlModeFrontAxle 3 "NotAvailable" 2 "Error" 1 "LoweringActive" 0 "LoweringNotActive" ;
VAL_ 2365479471 AboveNominalLevelRearAxle 3 "NotAvailable" 2 "Error" 1 "Above" 0 "NotAbove" ;
VAL_ 2365479471 AboveNominalLevelFrontAxle 3 "NotAvailable" 2 "Error" 1 "Above" 0 "NotAbove" ;
VAL_ 2365479471 BelowNominalLevelRearAxle 3 "NotAvailable" 2 "Error" 1 "Below" 0 "NotBelow" ;
VAL_ 2365479471 BelowNominalLevelFrontAxle 3 "NotAvailable" 2 "Error" 1 "Below" 0 "NotBelow" ;
VAL_ 2365479471 NominalLevelRearAxle 15 "NotAvailable" 14 "Error" 8 "1101NotDefined" 7 "LowerLevel" 6 "UpperLevel" 5 "CustomerLevel" 4 "PresetLevel" 3 "NormalLevel3" 2 "NormalLevel2" 1 "NormalLevel1" 0 "LevelNotSpecified" ;
VAL_ 2365479471 NominalLevelFrontAxle 15 "NotAvailable" 14 "Error" 8 "1101NotDefined" 7 "LowerLevel" 6 "UpperLevel" 5 "CustomerLevel" 4 "PresetLevel" 3 "NormalLevel3" 2 "NormalLevel2" 1 "NormalLevel1" 0 "LevelNotSpecified" ;
VAL_ 2365479471 LiftAxle2Pos 3 "NotAvailable" 2 "Error" 1 "LiftAxlePosUp_TagAxleUnladen" 0 "LiftAxlePosDown_TagAxleLaden" ;
VAL_ 2365479471 LiftAxle1Pos 3 "NotAvailable" 2 "Error" 1 "LiftAxlePosUp_TagAxleUnladen" 0 "LiftAxlePosDown_TagAxleLaden" ;
VAL_ 2566836222 FlashRedStopLamp 3 "Unavailable / Do Not Flash" 2 "Reserved" 1 "Fast Flash" 0 "Slow Flash" ;
VAL_ 2566836222 FlashProtectLamp 3 "Unavailable / Do Not Flash" 2 "Reserved" 1 "Fast Flash" 0 "Slow Flash" ;
VAL_ 2566836222 FlashMalfuncIndicatorLamp 3 "Unavailable / Do Not Flash" 2 "Reserved" 1 "Fast Flash" 0 "Slow Flash" ;
VAL_ 2566836222 MalfunctionIndicatorLampStatus 3 "Not available" 2 "Reserved" 1 "Lamp on" 0 "Lamp off" ;
VAL_ 2566836222 RedStopLampState 3 "Not available" 2 "Reserved" 1 "Lamp on" 0 "Lamp off" ;
VAL_ 2566836222 AmberWarningLampStatus 3 "Not available" 2 "Reserved" 1 "Lamp on" 0 "Lamp off" ;
VAL_ 2566836222 ProtectLampStatus 3 "Not available" 2 "Reserved" 1 "Lamp on" 0 "Lamp off" ;
VAL_ 2566835966 MisfireMonitoringSupport 3 "Not available" 2 "Reserved" 1 "test supported" 0 "test not supported" ;
VAL_ 2566835966 OBDCompliance 5 "Not intended to meet OBD II requ" 4 "OBD I" 3 "OBD and OBD II" 2 "OBD (Federal, EPA)" 1 "OBD II (California, ARB)" 0 "Reserver for assignment by SAE" ;
VAL_ 2566835966 SecondAirSystemMonStatus 1 "TestNotComplete" 0 "TestComplete" ;
VAL_ 2566835966 EvaporativeSystemMonStatus 1 "TestNotComplete" 0 "TestComplete" ;
VAL_ 2566835966 ACSystemRefrigerantMonStatus 1 "TestNotComplete" 0 "TestComplete" ;
VAL_ 2566835966 OxygenSensorHeaterMonStatus 1 "TestNotComplete" 0 "TestComplete" ;
VAL_ 2566835966 OxygenSensorMonStatus 1 "test not complete" 0 "test complete" ;
VAL_ 2566835966 EGRSystemMonitoringStatus 1 "TestNotComplete" 0 "TestComplete" ;
VAL_ 2566835966 CatalystMonStatus 0 "TestComplete" 1 "TestNotComplete" ;
VAL_ 2566835966 ColdStartAidSystemMonStatus 1 "TestNotComplete" 0 "TestComplete" ;
VAL_ 2566835966 HeatedCatalystMonStatus 1 "TestNotComplete" 0 "TestComplete" ;
VAL_ 2566835966 CatalystMonSupp 1 "TestSupported" 0 "TestNotSupported" ;
VAL_ 2566835966 ColdStartAidSystemMonSupp 1 "TestSupported" 0 "TestNotSupported" ;
VAL_ 2566835966 HeatedCatalystMonSupp 1 "TestSupported" 0 "TestNotSupported" ;
VAL_ 2566835966 EvaporativeSystemMonSupp 1 "TestSupported" 0 "TestNotSupported" ;
VAL_ 2566835966 SecondAirSystemMonSupp 1 "TestSupported" 0 "TestNotSupported" ;
VAL_ 2566835966 ACSystemRefrigerantMonSupp 1 "TestSupported" 0 "TestNotSupported" ;
VAL_ 2566835966 OxygenSensorMonSupp 1 "TestSupported" 0 "TestNotSupported" ;
VAL_ 2566835966 OxygenSensorHeaterMonSupp 1 "TestSupported" 0 "TestNotSupported" ;
VAL_ 2566835966 EGRSystemMonitoringSupp 1 "TestSupported" 0 "TestNotSupported" ;
VAL_ 2566835966 MisfireMonitoringStatus 1 "test not complete" 0 "test complete" ;
VAL_ 2566835966 ComprehensiveCompMonStatus 1 "test not complete" 0 "test complete" ;
VAL_ 2566835966 FuelSystemMonitoringStatus 1 "test not complete" 0 "test complete" ;
VAL_ 2566835966 ComprehensiveComponentMonSupp 3 "Not available" 2 "Reserved" 1 "test supported" 0 "test not supported" ;
VAL_ 2566835966 FuelSystemMonitoringSupport 1 "test supported" 0 "test not supported" ;
VAL_ 2566835710 EngTorqueMode 15 "Not available" 11 "Remote accelerator" 10 "Braking system" 9 "High speed governor" 8 "Torque limiting" 7 "ABS control" 6 "Transmission control" 5 "ASR control" 4 "Road speed governor" 3 "PTO governor" 2 "Cruise control" 1 "Accelerator pedal/operator selec" 0 "Low idle governor/no request (de" ;
VAL_ 2566764286 SPNSupportTypeSTR3 1 "NotSupportedInScaledTestResults" 0 "SupportedInScaledTestResults" ;
VAL_ 2566764286 SPNSupportTypeSTR2 1 "NotSupportedInScaledTestResults" 0 "SupportedInScaledTestResults" ;
VAL_ 2566764286 SPNSupportTypeEFF3 1 "NotSupportedInExFreezeFrame" 0 "SupportedInExFreezeFrame" ;
VAL_ 2566764286 SPNSupportTypeEFF2 1 "NotSupportedInExFreezeFrame" 0 "SupportedInExFreezeFrame" ;
VAL_ 2566764286 SPNSupportTypeDS3 1 "NotSupportedInDataStream" 0 "SupportedInDataStream" ;
VAL_ 2566764286 SPNSupportTypeDS2 1 "NotSupportedInDataStream" 0 "SupportedInDataStream" ;
VAL_ 2566764286 SPNSupportTypeSTR1 1 "NotSupportedInScaledTestResults" 0 "SupportedInScaledTestResults" ;
VAL_ 2566764286 SPNSupportTypeDS1 1 "NotSupportedInDataStream" 0 "SupportedInDataStream" ;
VAL_ 2566764286 SPNSupportTypeEFF1 1 "NotSupportedInExFreezeFrame" 0 "SupportedInExFreezeFrame" ;
VAL_ 2566835198 MalfunctionIndicatorLampStatus 3 "Not available" 2 "Reserved" 1 "Lamp on" 0 "Lamp off" ;
VAL_ 2566835198 RedStopLampState 3 "Not available" 2 "Reserved" 1 "Lamp on" 0 "Lamp off" ;
VAL_ 2566835198 AmberWarningLampStatus 3 "Not available" 2 "Reserved" 1 "Lamp on" 0 "Lamp off" ;
VAL_ 2566835198 ProtectLampStatus 3 "Not available" 2 "Reserved" 1 "Lamp on" 0 "Lamp off" ;
VAL_ 2566835198 FlashRedStopLamp 3 "Unavailable / Do Not Flash" 2 "Reserved" 1 "Fast Flash" 0 "Slow Flash" ;
VAL_ 2566835198 FlashProtectLamp 3 "Unavailable / Do Not Flash" 2 "Reserved" 1 "Fast Flash" 0 "Slow Flash" ;
VAL_ 2566835198 FlashMalfuncIndicatorLamp 3 "Unavailable / Do Not Flash" 2 "Reserved" 1 "Fast Flash" 0 "Slow Flash" ;
VAL_ 2566835198 FlashAmberWarningLamp 3 "Unavailable / Do Not Flash" 2 "Reserved" 1 "Fast Flash" 0 "Slow Flash" ;
VAL_ 2566837502 FlashRedStopLamp 3 "Unavailable / Do Not Flash" 2 "Reserved" 1 "Fast Flash" 0 "Slow Flash" ;
VAL_ 2566837502 FlashProtectLamp 3 "Unavailable / Do Not Flash" 2 "Reserved" 1 "Fast Flash" 0 "Slow Flash" ;
VAL_ 2566837502 MalfunctionIndicatorLampStatus 3 "Not available" 2 "Reserved" 1 "Lamp on" 0 "Lamp off" ;
VAL_ 2566837502 RedStopLampState 3 "Not available" 2 "Reserved" 1 "Lamp on" 0 "Lamp off" ;
VAL_ 2566837502 AmberWarningLampStatus 3 "Not available" 2 "Reserved" 1 "Lamp on" 0 "Lamp off" ;
VAL_ 2566837502 ProtectLampStatus 3 "Not available" 2 "Reserved" 1 "Lamp on" 0 "Lamp off" ;
VAL_ 2566837502 FlashMalfuncIndicatorLamp 3 "Unavailable / Do Not Flash" 2 "Reserved" 1 "Fast Flash" 0 "Slow Flash" ;
VAL_ 2566837502 FlashAmberWarningLamp 3 "Unavailable / Do Not Flash" 2 "Reserved" 1 "Fast Flash" 0 "Slow Flash" ;
VAL_ 2566834942 FlashRedStopLamp 3 "Unavailable / Do Not Flash" 2 "Reserved" 1 "Fast Flash" 0 "Slow Flash" ;
VAL_ 2566834942 FlashProtectLamp 3 "Unavailable / Do Not Flash" 2 "Reserved" 1 "Fast Flash" 0 "Slow Flash" ;
VAL_ 2566834942 FlashMalfuncIndicatorLamp 3 "Unavailable / Do Not Flash" 2 "Reserved" 1 "Fast Flash" 0 "Slow Flash" ;
VAL_ 2566834942 FlashAmberWarningLamp 3 "Unavailable / Do Not Flash" 2 "Reserved" 1 "Fast Flash" 0 "Slow Flash" ;
VAL_ 2566834942 MalfunctionIndicatorLampStatus 3 "Not available" 2 "Reserved" 1 "Lamp on" 0 "Lamp off" ;
VAL_ 2566834942 AmberWarningLampStatus 3 "Not available" 2 "Reserved" 1 "Lamp on" 0 "Lamp off" ;
VAL_ 2566834942 RedStopLampState 3 "Not available" 2 "Reserved" 1 "Lamp on" 0 "Lamp off" ;
VAL_ 2566834942 ProtectLampStatus 3 "Not available" 2 "Reserved" 1 "Lamp on" 0 "Lamp off" ;
VAL_ 2565799678 VehicleSystem5 127 "Not Available" 0 "Ind. Process Control Stationary" ;
VAL_ 2565799678 VehicleSystem4 100 "Deck/Cargo/Fishing equip. sys" 90 "Environmental (HVAC) Systems" 80 "Instrumentation/General Systems" 70 "Communications Systems" 60 "Navigation Systems" 50 "Propulsion Systems" 40 "Steering Systems" 30 "Power Mgmt and lighting systems" 25 "Gateway" 20 "Safety Systems" 10 "System Tools" 127 "Not Available" 0 "Non-specific System" ;
VAL_ 2565799678 VehicleSystem3 8 "Grader" 7 "Four Wheel Drive Loader" 6 "Forklift" 5 "Excavator" 4 "Crawler" 3 "Backhoe" 2 "Articulated Dump Truck" 1 "Skid Steer Loader" 127 "Not Available" 0 "Non-specific System" ;
VAL_ 2565799678 VehicleSystem2 16 "Skidder" 15 "Earth Work" 14 "Special Crops" 13 "Powered Auxiliary Device" 12 "Farm Yard Operations" 11 "Transport/Trailer" 10 "Irrigation" 9 "Forage" 8 "Root Harvesters" 7 "Harvesters" 6 "Sprayers" 5 "Fertilizers" 4 "Planters/Seeders" 3 "Secondary Tillage" 2 "Tillage" 1 "Tractor" 127 "Not Available" 0 "Non-specific System" ;
VAL_ 2565799678 VehicleSystem1 2 "Trailer" 1 "Tractor" 127 "Not Available" 0 "Non-specific System" ;
VAL_ 2565799678 IndustryGroup 6 "Reserved for SAE" 7 "Reserved for SAE" 5 "IndustrialProcessCtrlStationary" 4 "Marine" 3 "Construction" 2 "Agricultural and Forestry" 1 "On-Highway" 0 "Global" ;
VAL_ 2565799678 VehicleSystem 0 "Non-specific System" 127 "Not Available" ;
VAL_ 2565799678 Function 127 "Reserved" 126 "Reserved" 125 "Reserved" 124 "Reserved" 123 "Reserved" 122 "Reserved" 121 "Reserved" 120 "Reserved" 119 "Reserved" 118 "Reserved" 117 "Reserved" 116 "Reserved" 115 "Reserved" 114 "Reserved" 113 "Reserved" 112 "Reserved" 111 "Reserved" 110 "Reserved" 109 "Reserved" 108 "Reserved" 107 "Reserved" 106 "Reserved" 105 "Reserved" 104 "Reserved" 103 "Reserved" 102 "Reserved" 101 "Reserved" 42 "Water Pump Control" 41 "Lighting - Operator Controls" 40 "Seat Control" 39 "Ignition Control Module" 38 "Tire Pressure Control" 37 "Cab Controller" 36 "Pneumatic - System Controller" 35 "Suspension - System Controller" 34 "Hydraulic Pump Controller" 33 "System Monitor" 32 "Headway Controller" 31 "Propulsion Battery Charger" 30 "Management Computer" 29 "Virtual Terminal (In Cab)" 28 "Off Vehicle Gateway" 27 "Power TakeOff (Secondary or Front)" 26 "Body Controller" 25 "Network Interconnect ECU" 24 "Vehicle Security" 23 "Vehicle Navigation" 22 "Aerodynamic Control" 21 "Cab Climate Control" 20 "Trip Recorder" 19 "Instrument Cluster" 18 "Suspension - Drive Axle" 17 "Suspension - Steer Axle" 16 "Steeting Controller" 15 "Fuel System" 14 "Cruise Control" 13 "Retarder - Driveline" 12 "Retarder - Engine" 11 "Brakes - Drive Axle" 10 "Brakes - Steer Axle" 9 "Brakes - System Controller" 8 "Axle - Drive" 7 "Axle - Steering" 6 "Power TakeOff - (Main or Rear)" 5 "Shift Control/Console" 4 "Battery Pack Monitor" 3 "Transmission" 2 "Electric Propulsion Control" 1 "Auxiliary Power Unit (APU)" 0 "Engine" 100 "Reserved" 99 "Reserved" 98 "Reserved" 97 "Reserved" 96 "Reserved" 95 "Reserved" 94 "Reserved" 93 "Reserved" 92 "Reserved" 91 "Reserved" 90 "Reserved" 89 "Reserved" 88 "Reserved" 87 "Reserved" 86 "Reserved" 85 "Reserved" 84 "Reserved" 83 "Reserved" 82 "Reserved" 81 "Reserved" 80 "Reserved" 79 "Reserved" 78 "Reserved" 77 "Reserved" 76 "Reserved" 75 "Reserved" 74 "Reserved" 73 "Reserved" 72 "Coolant Valve Controller" 71 "Transfer Case Control" 70 "Auxiliary Regeneration Device" 69 "Engine Emission Aftertreatement System" 68 "Aftertreatment system gas measurement" 67 "Electrical System Controller" 66 "I/O Controller" 65 "Gas Flow Measurement" 64 "Endurance Braking" 63 "Engine Valve Controller" 62 "On-Board Diagnostic Unit" 61 "File Server/Printer" 60 "Cab Display" 59 "Starter" 58 "Fan Drive Control" 57 "Steering Column Unit" 56 "Communications Unit, Radio" 55 "Communications Unit, Satellite" 54 "Communications Unit, Cellular" 53 "Alternator/Charging System" 52 "Chassis Controller" 51 "Forward-Looking Collision Warning System" 50 "Auxiliary Heater" 49 "Clutch/Converter Control" 48 "Ramp Control" 47 "Information System Controller" 46 "Oil Sensor Unit" 45 "Vehicle Dynamic Stability Control" 44 "Exhaust Emission Control" 43 "Transmission Display" ;
VAL_ 2565799678 ManufacturerCode 1863 "Thomas G. Faria Co." 1862 "Sanshin" 1861 "Vector CANtech" 1860 "MMP" 1859 "Kvasar AB" 1858 "Litton" 1857 "Simrad" 1856 "Trimble" 1855 "Furuno USA" 1854 "Northstar Technologies" 1853 "Japan Radio Co." 1852 "Navionics" 1851 "Raymarine" 1850 "Teleflex" 222 "Generac Power Systems, Inc." 221 "SiE" 220 "Beede Electrical Instrument Company, Inc." 219 "Cat OEM Solutions" 218 "Gits Manufacturing Company" 217 "RM Michaelides Software & Elektronik GmbH" 216 "Paneltronics Inc." 215 "Aetna Engineering/Fireboy-Xintex" 214 "MC elettronica Srl" 213 "CNH Belgium N.V." 212 "Sure Power Industries, Inc." 211 "DNA Group" 210 "Iteris, Inc." 209 "Bell Equip. Co. SA (PTY) LTD" 208 "Drew Technologies, Inc." 207 "Otto Engineering" 206 "port GmbH" 205 "SmarTire Systems Inc" 204 "The Morey Corporation" 203 "MILtronik GmbH" 202 "Curtis Instruments, Inc." 201 "Disenos y Tecnologia S.A." 200 "MGM Brakes" 199 "Actia Corp." 198 "Mystic Valley Communications" 197 "Mechron Power Systems" 196 "LEMKEN GmbH & Co. KG" 195 "General Engine Products" 194 "TriMark Corporation" 193 "Jeppesen Marine" 192 "Floscan" 191 "XATA Corporation" 190 "Hella KGaA Hueck & Co." 189 "QUALCOMM" 188 "EMP Corp." 187 "Air-Weigh" 186 "Altronic, Inc." 185 "Beede Electrical Instrument Company" 184 "EIA Electronics" 183 "KDS Controls, Inc." 182 "Vehicle Systems Engineering B.V." 181 "Coretronics, Inc." 180 "Smart Power Systems" 179 "Midwest Technologies Illinois, LLC" 178 "Siemens VDO Automotive AG" 177 "Diagnostic System Associates" 176 "Moritz Aerospace" 175 "Veris Technologies, Inc." 174 "AB Volvo Penta" 173 "Ryeso, Inc." 172 "Yanmar Marine USA" 171 "Wachendorff Elektronik GmbH & Co. KG" 170 "Computronics Corporation Ltd." 169 "Marlin Technologies Inc." 168 "Xantrex" 167 "JLG Industries Inc." 166 "Phoenix International" 165 "CPAC Systems AB" 164 "DaimlerChrysler Off-Highway" 163 "BRP Inc." 162 "Axiomatic Technologies" 161 "Offshore Systems (UK) Limited" 160 "Nido" 159 "NTech Industries Inc." 158 "Firestone Industrial Products Company" 157 "ISSPRO Inc." 156 "ITT Industries - Cannon" 155 "Vetronix Corporation" 154 "Westerbeke Corporation" 153 "Woodward, Industrial Controls Division" 152 "Elobau Elektrobauelemente GmbH & Co. KG" 151 "Raven Industries Inc. - Flow Controls Division" 150 "Fleetguard" 149 "Holset" 148 "Blue Water Data, Inc." 147 "Nautibus Electronic GmbH" 146 "Maxima Technologies" 145 "MurCal Controls" 144 "Mercury Marine" 143 "W. Gmeiner GmbH & Co." 142 "TRW Automotive (Commercial Steering Systems)" 141 "Thales Navigation Ltd." 140 "Lowrance Electronics, Inc." 139 "Caterpillar Trimble Control Technologies (CTCT), LLC" 138 "Georg Fritzmeier GmbH & Co. KG" 137 "Maretron" 136 "Komatsu Ltd." 135 "Airmar Technology Corporation" 134 "Iris Technology Ltd." 133 "Bucher Schoerling GmbH" 132 "Mulag-Fahrzeugwerk" 131 "ITT Industries" 130 "Nido - Universal Machines B.V." 129 "OMNEX Control Systems, Inc." 128 "Gerhard Duecker GmbH & Co. KG" 127 "Holland USA" 126 "Driver Tech" 125 "Nevada Automotive Test Center" 124 "Hydac Electronic" 123 "Basler Electric" 122 "FG Wilson (Engineering) Limited" 121 "HED (Hydro Electronic Devices, Inc.)" 120 "RDS Technology Ltd." 119 "IntegriNautics" 118 "Intron GmbH" 117 "HUSCO International" 116 "BEELINE Technologies" 115 "NACCO Materials Handling Group, Inc." 114 "EControls, Inc." 113 "Stress-Tek, Inc." 112 "MECALAC" 111 "Maschinenfabrik Bernhard Krone GmbH" 110 "EPIQ Sensor-Nite" 109 "LH Technologies ApS" 108 "WTK-Elecktronik GmbH" 107 "Grimme Landmaschinen GmbH & Co. KG" 106 "BAE Systems Controls, Inc." 105 "Kiepe Elektrik GmbH & Co. KG" 104 "Claas Selbstfahrende Erntemaschinen GmbH" 103 "Agrocom GmbH & Co. Agrarsystem KG" 102 "AGCO GmbH & Co." 101 "Sensoria" 100 "VDO Technik AG" 99 "International Transmissions Ltd (ITL)" 98 "Mueller-Elektronik GmbH & Co." 97 "Ag Leader Technology, Inc." 96 "Mech@tronic IT GmbH" 95 "Pacific Insight Electronics Corp." 94 "CNH Global N.V." 93 "Perkins Engines Company Ltd." 92 "Ag-Chem Equipment Co., Inc." 91 "BSG Bodensee Steuergeraete GmbH" 90 "Knorr-Bremse SfN GmbH" 89 "Kverneland Group, Electronics Division" 88 "Satloc Precision GPS" 87 "J.C. Bamford Excavators Ltd (JCB)" 86 "C.E. Niehoff & Company" 85 "Kohler Co." 84 "New Holland UK Limited" 83 "Eaton VORAD Technologies" 82 "Bobcat/Ingersoll-Rand" 81 "Fire Research Corp" 80 "Twin Disc, Inc." 79 "Daimler Benz AG - Engine Division (PBM)" 78 "Frank W. Murphy Manufacturing, Inc." 77 "Deere Power Systems Group" 76 "unused" 75 "Deere & Co. Agricultural Division" 74 "Eaton Axle-Brake Division" 73 "LeTourneau, Inc." 72 "Sisu Corporation" 71 "Vansco Electronics Ltd." 70 "Flex-Coil Limited" 69 "Trimble Navigation" 68 "Scania" 67 "Funk Manufacturing Company" 66 "John Deere Construction Equipment Division" 65 "MAN Nutzfahrzeuge AG" 64 "unused" 63 "ZF Industries Inc." 62 "Wabco" 61 "Volvo Truck Corp." 60 "Volvo Trucks North America Inc." 59 "VES Inc." 58 "SPX Corporation, OTC Division" 57 "Sauer-Danfoss Co." 56 "SAIC" 55 "Ryder System Inc." 54 "Meritor Wabco" 53 "Rockwell Land Transportation" 52 "Meritor Automotive, Inc." 51 "Robert Bosch GmbH" 50 "Robert Bosch Corp" 49 "RE America Inc." 48 "Pollak Alphabet" 47 "Phillips Semiconductor" 46 "Parasoft Computing Solutions" 45 "PACCAR" 44 "Nippondenso Co. Ltd." 43 "International Truck and Engine Corp. Vehicle Electronics" 42 "International Truck and Engine Corp. Engine Electronics" 41 "Motorola Inc." 40 "Motorola AIEG Inc." 39 "Microfirm Inc." 38 "Micro Processor Systems Inc." 37 "Mack Trucks Inc." 36 "Lucas Ltd." 35 "Kenworth Truck Co." 34 "Kelsey Hayes Co." 33 "John Deere" 32 "Jacobs Vehicle Systems" 31 "J Pollak Corp." 30 "Isuzu Motors Ltd." 29 "Hino Motors Ltd." 28 "Grote Ind. Inc." 27 "GMC" 26 "General Motors Corp., Service Technology Group" 25 "Freightliner LLC" 24 "Ford Motor Co., Vehicle Controls" 23 "Ford Motor Co., Heavy Truck" 22 "Ford Motor Co., Electronic Concepts $ Systems" 21 "Echilin Inc., Midland Brake Inc." 20 "Eaton Ltd" 19 "Eaton Corp. Trucking Info Services" 18 "Eaton Corp, Transmission Division" 17 "Eaton Corp. Res & Dev" 16 "Eaton Corp." 15 "Dickey-John Corp." 14 "Detroit Diesel Corporation" 13 "Delco Electronics" 12 "Deere & Company, Precision Farming" 11 "Dearborn Group Inc." 10 "Cummins Engine Co." 9 "Chrysler Corp." 8 "Caterpillar Inc." 7 "Case Corp." 6 "Berifors Electronics AB" 5 "AMP Inc." 4 "Ametek-Dixson" 3 "Ametek, US Gauge Division" 2 "Allison Transmission, GMC" 1 "Allied Signal Inc." 0 "Reserved" ;
VAL_ 2565668606 PGNumber 255 "NotAvailable" ;
VAL_ 2565668606 ControlByte 24 "EAbort" 23 "EEoMACK" 22 "EDPO" 21 "ECTS" 20 "ERTS" 3 "CannotRespond" 2 "AccessDenied" 1 "NACK" 0 "ACK" 255 "Abort" 32 "BAM" 19 "EoMA" 17 "CTS" 16 "RTS" ;
VAL_ 2563374846 UseTransferMode 3 "NA" 2 "Undefined" 1 "Yes" 0 "No" ;
VAL_ 2565406462 ControlByte 24 "EAbort" 23 "EEoMACK" 22 "EDPO" 21 "ECTS" 20 "ERTS" 3 "CannotRespond" 2 "AccessDenied" 1 "NACK" 0 "ACK" 255 "Abort" 32 "BAM" 19 "EoMA" 17 "CTS" 16 "RTS" ;
VAL_ 2566846467 TransOilLevelMeasurementStatus 15 "NotAvailable" 14 "Error" 13 "ConditionsNotValidOther" 12 "NotDefined" 8 "CndtionsNotValidEngSpeedTooHigh" 7 "CnditionsNotValidEngSpeedTooLow" 6 "CndtionsNotValidVehicleNotLevel" 5 "CndtnsNtVldVhclMvngOtptShftSpdT" 4 "CndtnsNtVldTrnsFluidTempTooHigh" 3 "CndtnsNtVldTransFluidTempTooLow" 2 "ConditionsNotValidTransInGear" 1 "CndtnsNtVldSttlngTmrStllCntngDw" 0 "CndtnsVldFrTrnsOlLvlMeasurement" ;
VAL_ 2566846467 TransOilLevelCountdownTimer 15 "NotAvailable" 14 "Error" 13 "ThirteenMinutes" 12 "TwelveMinutes" 11 "ElevenMinutes" 10 "TenMinutes" 9 "NineMinutes" 8 "EightMinutes" 7 "SevenMinutes" 6 "SixMinutes" 5 "FiveMinutes" 4 "FourMinutes" 3 "ThreeMinutes" 2 "TwoMinutes" 1 "OneMinute" 0 "lessThan1Minute" ;
VAL_ EnvEBS_SimulationMode 1 "SimulateValues" 0 "ManualValueAdjustment" ;
VAL_ EnvTECU_SimulationMode 1 "SimulateValues" 0 "ManualValueAdjustment" ;
VAL_ EnvEMS_SimulationMode 1 "SimulateValues" 0 "ManualValueAdjustment" ;
